VERSION ""

NS_ :

BS_:

BU_: ACM APIM APIM_CDC APIM_CIM APIM_CISM ARM DSP ESPM FCIMB GENERIC GWM HUD_ADV IPC MRCMB_RDAPM_HS3 RACM_RCIM TRM_ITRM TSTR WCM WCMB WCMC

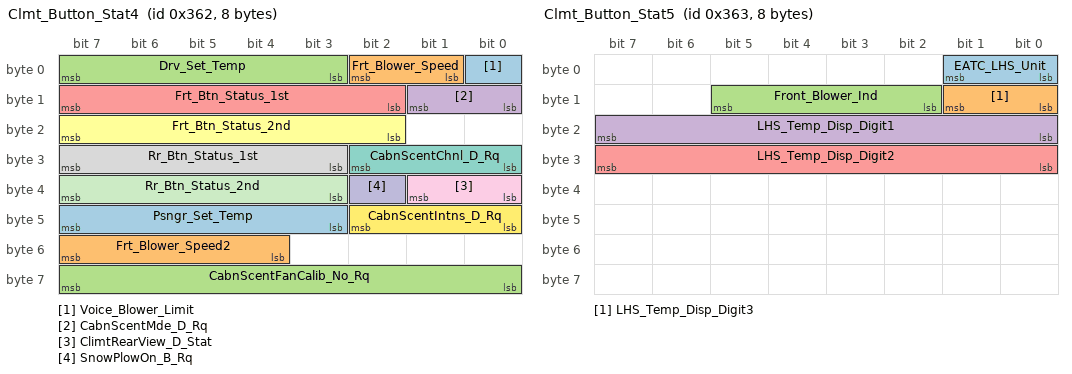
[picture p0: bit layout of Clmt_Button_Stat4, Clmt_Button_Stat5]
BO_ 866 Clmt_Button_Stat4: 8 APIM_CDC
 SG_ Voice_Blower_Limit : 0|1@0+ (1,0) [0|1] "SED"  GWM
 SG_ Frt_Blower_Speed : 2|2@0+ (1,0) [0|3] "SED"  GWM,RACM_RCIM
 SG_ Drv_Set_Temp : 7|5@0+ (1,0) [0|31] "SED"  GWM,RACM_RCIM
 SG_ CabnScentMde_D_Rq : 9|2@0+ (1,0) [0|3] "SED"  GWM
 SG_ Frt_Btn_Status_1st : 15|6@0+ (1,0) [0|63] "SED"  ACM,GWM,RACM_RCIM
 SG_ Frt_Btn_Status_2nd : 23|6@0+ (1,0) [0|63] "SED"  ACM,GWM,RACM_RCIM
 SG_ CabnScentChnl_D_Rq : 26|3@0+ (1,0) [0|7] "SED"  GWM
 SG_ Rr_Btn_Status_1st : 31|5@0+ (1,0) [0|31] "SED"  GWM,RACM_RCIM
 SG_ ClimtRearView_D_Stat : 33|2@0+ (1,0) [0|3] "SED"  GWM,RACM_RCIM
 SG_ SnowPlowOn_B_Rq : 34|1@0+ (1,0) [0|1] "SED"  GWM
 SG_ Rr_Btn_Status_2nd : 39|5@0+ (1,0) [0|31] "SED"  GWM,RACM_RCIM
 SG_ CabnScentIntns_D_Rq : 42|3@0+ (1,0) [0|7] "SED"  GWM
 SG_ Psngr_Set_Temp : 47|5@0+ (1,0) [0|31] "SED"  GWM,RACM_RCIM
 SG_ Frt_Blower_Speed2 : 55|4@0+ (1,0) [0|15] "SED"  GWM,RACM_RCIM
 SG_ CabnScentFanCalib_No_Rq : 63|8@0+ (1,0) [0|255] "SED"  GWM

BO_ 867 Clmt_Button_Stat5: 8 APIM_CDC
 SG_ EATC_LHS_Unit : 1|2@0+ (1,0) [0|3] "SED"  GWM,HUD_ADV
 SG_ LHS_Temp_Disp_Digit3 : 9|2@0+ (1,0) [0|3] "SED"  GWM,HUD_ADV
 SG_ Front_Blower_Ind : 13|4@0+ (1,0) [0|15] "SED"  GWM
 SG_ LHS_Temp_Disp_Digit1 : 23|8@0+ (1,0) [0|255] "ASCII"  GWM,HUD_ADV
 SG_ LHS_Temp_Disp_Digit2 : 31|8@0+ (1,0) [0|255] "ASCII"  GWM,HUD_ADV

BO_ 868 Clmt_Button_Stat6_HS3: 8 GWM
 SG_ Rr_Blower_Indicate_Stat : 7|4@0+ (1,0) [0|15] "SED"  GENERIC

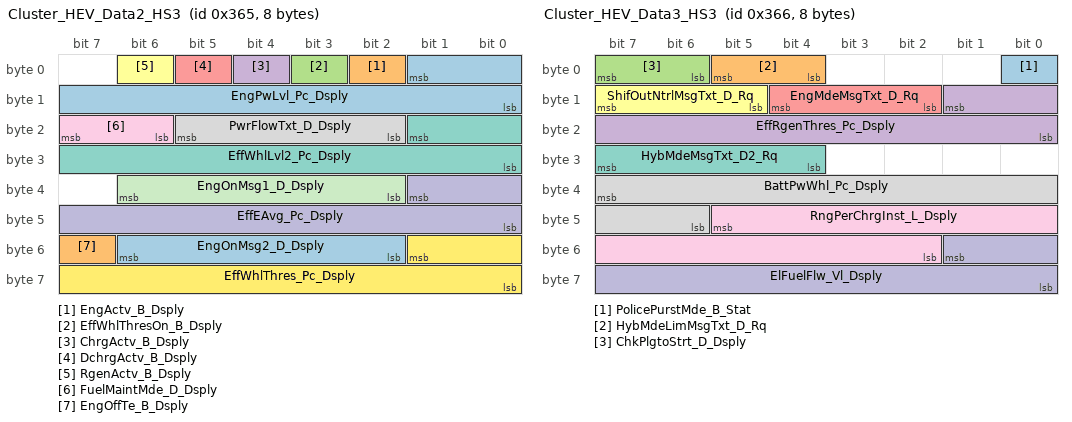
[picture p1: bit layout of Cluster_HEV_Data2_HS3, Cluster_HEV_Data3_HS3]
BO_ 869 Cluster_HEV_Data2_HS3: 8 GWM
 SG_ EngPwLvl_Pc_Dsply : 1|10@0+ (0.1,0) [0|102.3] "percent"  APIM,APIM_CDC,APIM_CIM,APIM_CISM,IPC
 SG_ EngActv_B_Dsply : 2|1@0+ (1,0) [0|1] "SED"  APIM,APIM_CDC,APIM_CIM,APIM_CISM,IPC
 SG_ EffWhlThresOn_B_Dsply : 3|1@0+ (1,0) [0|1] "SED"  APIM_CDC,APIM_CIM,APIM_CISM,IPC
 SG_ ChrgActv_B_Dsply : 4|1@0+ (1,0) [0|1] "SED"  APIM_CDC,APIM_CIM,APIM_CISM,IPC
 SG_ DchrgActv_B_Dsply : 5|1@0+ (1,0) [0|1] "SED"  APIM_CDC,APIM_CIM,APIM_CISM,IPC
 SG_ RgenActv_B_Dsply : 6|1@0+ (1,0) [0|1] "SED"  APIM_CDC,APIM_CIM,APIM_CISM,IPC
 SG_ EffWhlLvl2_Pc_Dsply : 17|10@0+ (0.2,-102.2) [-102.2|102.4] "percent"  ACM,APIM,APIM_CDC,APIM_CIM,APIM_CISM,IPC
 SG_ PwrFlowTxt_D_Dsply : 21|4@0+ (1,0) [0|15] "SED"  APIM,APIM_CDC,APIM_CIM,APIM_CISM,IPC
 SG_ FuelMaintMde_D_Dsply : 23|2@0+ (1,0) [0|3] "SED"  APIM_CDC,APIM_CIM,IPC
 SG_ EffEAvg_Pc_Dsply : 33|10@0+ (0.1,0) [0|102.3] "percent"  APIM,APIM_CDC,APIM_CIM,APIM_CISM,IPC
 SG_ EngOnMsg1_D_Dsply : 38|5@0+ (1,0) [0|31] "SED"  APIM,APIM_CDC,APIM_CIM,APIM_CISM,IPC
 SG_ EffWhlThres_Pc_Dsply : 49|10@0+ (0.1,0) [0|102.3] "percent"  APIM_CDC,APIM_CIM,IPC
 SG_ EngOnMsg2_D_Dsply : 54|5@0+ (1,0) [0|31] "SED"  APIM,APIM_CDC,APIM_CIM,APIM_CISM,IPC
 SG_ EngOffTe_B_Dsply : 55|1@0+ (1,0) [0|1] "SED"  APIM_CDC,APIM_CIM,APIM_CISM,IPC

BO_ 870 Cluster_HEV_Data3_HS3: 8 GWM
 SG_ PolicePurstMde_B_Stat : 0|1@0+ (1,0) [0|1] "SED"  APIM_CDC,APIM_CIM,IPC
 SG_ HybMdeLimMsgTxt_D_Rq : 5|2@0+ (1,0) [0|3] "SED"  APIM_CDC,APIM_CIM,APIM_CISM,IPC
 SG_ ChkPlgtoStrt_D_Dsply : 7|2@0+ (1,0) [0|3] "SED"  APIM_CDC,APIM_CIM,IPC
 SG_ EffRgenThres_Pc_Dsply : 9|10@0+ (0.1,-102.3) [-102.3|0] "percent"  APIM_CDC,APIM_CIM,IPC
 SG_ EngMdeMsgTxt_D_Rq : 12|3@0+ (1,0) [0|7] "SED"  APIM_CDC,APIM_CIM,IPC
 SG_ ShifOutNtrlMsgTxt_D_Rq : 15|3@0+ (1,0) [0|7] "SED"  APIM_CDC,APIM_CIM,APIM_CISM,IPC
 SG_ HybMdeMsgTxt_D2_Rq : 31|4@0+ (1,0) [0|15] "SED"  APIM_CDC,APIM_CIM,IPC
 SG_ BattPwWhl_Pc_Dsply : 39|10@0+ (0.1,0) [0|102.3] "percent"  APIM_CDC,APIM_CIM,APIM_CISM,IPC
 SG_ RngPerChrgInst_L_Dsply : 45|12@0+ (0.1,0) [0|409.5] "km"  APIM_CDC,APIM_CIM,IPC
 SG_ ElFuelFlw_Vl_Dsply : 49|10@0+ (25,0) [0|25575] "micro-litre"  APIM_CDC,APIM_CIM,APIM_CISM,IPC

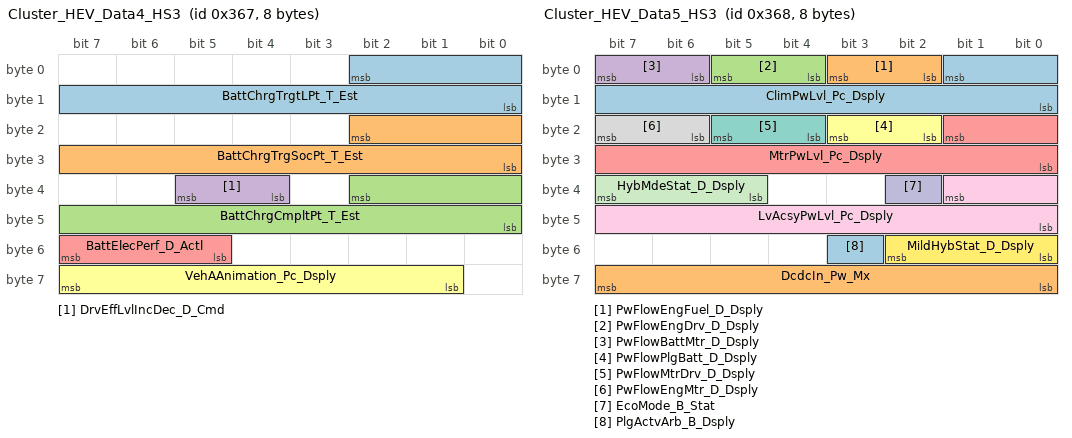
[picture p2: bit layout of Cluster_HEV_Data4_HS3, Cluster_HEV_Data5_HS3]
BO_ 871 Cluster_HEV_Data4_HS3: 8 GWM
 SG_ BattChrgTrgtLPt_T_Est : 2|11@0+ (1,0) [0|2047] "minute"  IPC
 SG_ BattChrgTrgSocPt_T_Est : 18|11@0+ (1,0) [0|2047] "minute"  IPC
 SG_ BattChrgCmpltPt_T_Est : 34|11@0+ (1,0) [0|2047] "minute"  IPC
 SG_ DrvEffLvlIncDec_D_Cmd : 37|2@0+ (1,0) [0|3] "SED"  APIM_CDC,APIM_CIM,APIM_CISM,IPC
 SG_ BattElecPerf_D_Actl : 55|3@0+ (1,0) [0|7] "SED"  APIM_CDC,APIM_CIM,APIM_CISM,IPC
 SG_ VehAAnimation_Pc_Dsply : 63|7@0+ (1,0) [0|127] "percent"  APIM_CDC,APIM_CIM,APIM_CISM,IPC

BO_ 872 Cluster_HEV_Data5_HS3: 8 GWM
 SG_ ClimPwLvl_Pc_Dsply : 1|10@0+ (0.1,0) [0|102.3] "percent"  APIM,APIM_CDC,APIM_CIM,APIM_CISM,IPC
 SG_ PwFlowEngFuel_D_Dsply : 3|2@0+ (1,0) [0|3] "SED"  APIM,APIM_CDC,APIM_CIM,APIM_CISM,IPC
 SG_ PwFlowEngDrv_D_Dsply : 5|2@0+ (1,0) [0|3] "SED"  APIM,APIM_CDC,APIM_CIM,APIM_CISM,IPC
 SG_ PwFlowBattMtr_D_Dsply : 7|2@0+ (1,0) [0|3] "SED"  APIM,APIM_CDC,APIM_CIM,APIM_CISM,IPC
 SG_ MtrPwLvl_Pc_Dsply : 17|10@0+ (0.2,-102.2) [-102.2|102.4] "percent"  APIM,APIM_CDC,APIM_CIM,APIM_CISM,IPC
 SG_ PwFlowPlgBatt_D_Dsply : 19|2@0+ (1,0) [0|3] "SED"  APIM,APIM_CDC,APIM_CIM,APIM_CISM,IPC
 SG_ PwFlowMtrDrv_D_Dsply : 21|2@0+ (1,0) [0|3] "SED"  APIM,APIM_CDC,APIM_CIM,APIM_CISM,IPC
 SG_ PwFlowEngMtr_D_Dsply : 23|2@0+ (1,0) [0|3] "SED"  APIM,APIM_CDC,APIM_CIM,APIM_CISM,IPC
 SG_ LvAcsyPwLvl_Pc_Dsply : 33|10@0+ (0.1,0) [0|102.3] "percent"  APIM,APIM_CDC,APIM_CIM,APIM_CISM,IPC
 SG_ EcoMode_B_Stat : 34|1@0+ (1,0) [0|1] "SED"  APIM_CDC,APIM_CIM,IPC
 SG_ HybMdeStat_D_Dsply : 39|3@0+ (1,0) [0|7] "SED"  APIM,APIM_CDC,APIM_CIM,APIM_CISM,HUD_ADV,IPC
 SG_ MildHybStat_D_Dsply : 50|3@0+ (1,0) [0|7] "SED"  APIM_CDC,APIM_CIM,IPC
 SG_ PlgActvArb_B_Dsply : 51|1@0+ (1,0) [0|1] "SED"  APIM,APIM_CDC,APIM_CIM,APIM_CISM,IPC
 SG_ DcdcIn_Pw_Mx : 63|8@0+ (20,1000) [1000|6100] "watts" Vector__XXX

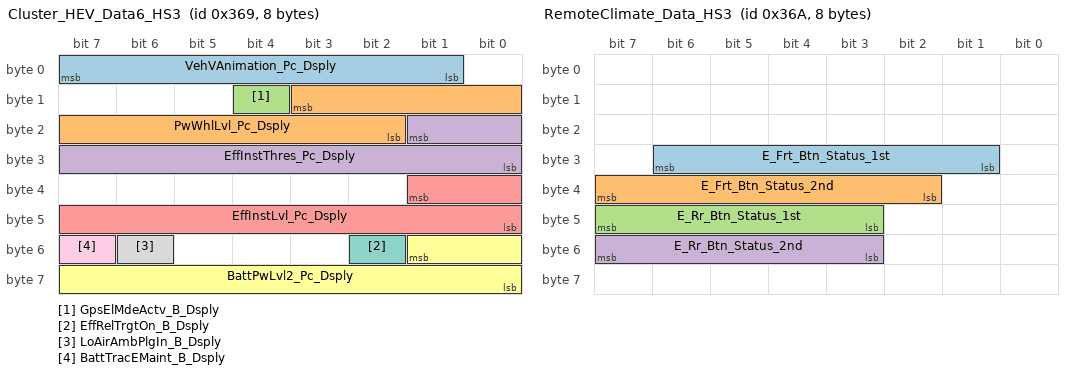
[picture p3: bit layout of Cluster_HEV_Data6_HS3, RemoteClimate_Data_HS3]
BO_ 873 Cluster_HEV_Data6_HS3: 8 GWM
 SG_ VehVAnimation_Pc_Dsply : 7|7@0+ (1,0) [0|127] "percent"  APIM_CDC,APIM_CIM,APIM_CISM,IPC
 SG_ PwWhlLvl_Pc_Dsply : 11|10@0+ (0.2,-102.2) [-102.2|102.4] "percent"  APIM_CDC,APIM_CIM,APIM_CISM,IPC
 SG_ GpsElMdeActv_B_Dsply : 12|1@0+ (1,0) [0|1] "SED"  APIM,APIM_CDC,APIM_CIM,APIM_CISM,IPC
 SG_ EffInstThres_Pc_Dsply : 17|10@0+ (0.1,0) [0|102.3] "percent"  APIM_CDC,APIM_CIM,APIM_CISM,IPC
 SG_ EffInstLvl_Pc_Dsply : 33|10@0+ (0.1,0) [0|102.3] "percent"  APIM_CDC,APIM_CIM,APIM_CISM,IPC
 SG_ BattPwLvl2_Pc_Dsply : 49|10@0+ (0.2,-102.2) [-102.2|102.4] "percent"  APIM,APIM_CDC,APIM_CIM,APIM_CISM,IPC
 SG_ EffRelTrgtOn_B_Dsply : 50|1@0+ (1,0) [0|1] "SED"  APIM_CDC,APIM_CIM,APIM_CISM,IPC
 SG_ LoAirAmbPlgIn_B_Dsply : 54|1@0+ (1,0) [0|1] "SED"  APIM_CDC,APIM_CIM,APIM_CISM,IPC
 SG_ BattTracEMaint_B_Dsply : 55|1@0+ (1,0) [0|1] "SED"  APIM_CDC,APIM_CIM,APIM_CISM,IPC

BO_ 874 RemoteClimate_Data_HS3: 8 FCIMB
 SG_ E_Frt_Btn_Status_1st : 30|6@0+ (1,0) [0|63] "SED"  APIM,APIM_CDC,APIM_CIM,APIM_CISM,GWM
 SG_ E_Frt_Btn_Status_2nd : 39|6@0+ (1,0) [0|63] "SED"  APIM,APIM_CDC,APIM_CIM,APIM_CISM,GWM
 SG_ E_Rr_Btn_Status_1st : 47|5@0+ (1,0) [0|31] "SED"  APIM,APIM_CDC,APIM_CIM,APIM_CISM,GWM
 SG_ E_Rr_Btn_Status_2nd : 55|5@0+ (1,0) [0|31] "SED"  APIM,APIM_CDC,APIM_CIM,APIM_CISM,GWM

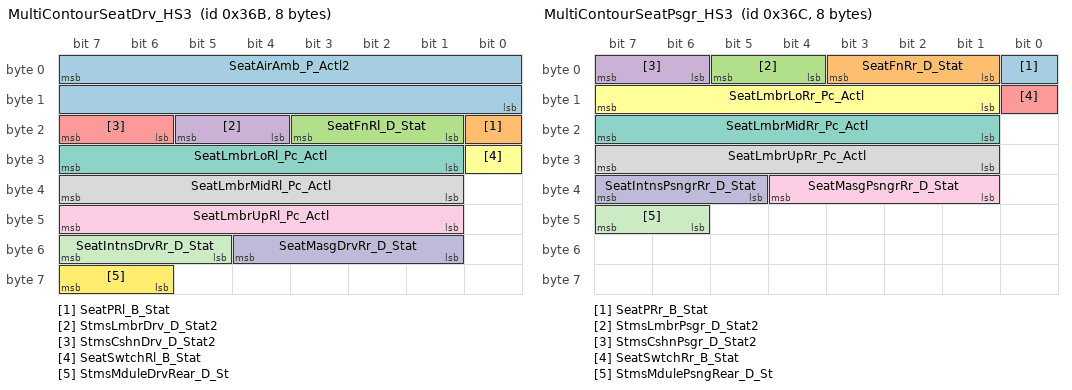
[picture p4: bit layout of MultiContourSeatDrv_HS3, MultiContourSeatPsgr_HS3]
BO_ 875 MultiContourSeatDrv_HS3: 8 GWM
 SG_ SeatAirAmb_P_Actl2 : 7|16@0+ (0.01,0) [0|655.35] "kilopascal"  RACM_RCIM
 SG_ SeatPRl_B_Stat : 16|1@0+ (1,0) [0|1] "SED"  RACM_RCIM
 SG_ SeatFnRl_D_Stat : 19|3@0+ (1,0) [0|7] "SED"  RACM_RCIM
 SG_ StmsLmbrDrv_D_Stat2 : 21|2@0+ (1,0) [0|3] "SED"  RACM_RCIM
 SG_ StmsCshnDrv_D_Stat2 : 23|2@0+ (1,0) [0|3] "SED"  RACM_RCIM
 SG_ SeatSwtchRl_B_Stat : 24|1@0+ (1,0) [0|1] "SED"  RACM_RCIM
 SG_ SeatLmbrLoRl_Pc_Actl : 31|7@0+ (1,0) [0|127] "Percent"  RACM_RCIM
 SG_ SeatLmbrMidRl_Pc_Actl : 39|7@0+ (1,0) [0|127] "Percent"  RACM_RCIM
 SG_ SeatLmbrUpRl_Pc_Actl : 47|7@0+ (1,0) [0|127] "Percent"  RACM_RCIM
 SG_ SeatMasgDrvRr_D_Stat : 52|4@0+ (1,0) [0|15] "SED"  RACM_RCIM
 SG_ SeatIntnsDrvRr_D_Stat : 55|3@0+ (1,0) [0|7] "SED"  RACM_RCIM
 SG_ StmsMduleDrvRear_D_St : 63|2@0+ (1,0) [0|3] "SED"  RACM_RCIM

BO_ 876 MultiContourSeatPsgr_HS3: 8 GWM
 SG_ SeatPRr_B_Stat : 0|1@0+ (1,0) [0|1] "SED"  RACM_RCIM
 SG_ SeatFnRr_D_Stat : 3|3@0+ (1,0) [0|7] "SED"  RACM_RCIM
 SG_ StmsLmbrPsgr_D_Stat2 : 5|2@0+ (1,0) [0|3] "SED"  RACM_RCIM
 SG_ StmsCshnPsgr_D_Stat2 : 7|2@0+ (1,0) [0|3] "SED"  RACM_RCIM
 SG_ SeatSwtchRr_B_Stat : 8|1@0+ (1,0) [0|1] "SED"  RACM_RCIM
 SG_ SeatLmbrLoRr_Pc_Actl : 15|7@0+ (1,0) [0|127] "Percent"  RACM_RCIM
 SG_ SeatLmbrMidRr_Pc_Actl : 23|7@0+ (1,0) [0|127] "Percent"  RACM_RCIM
 SG_ SeatLmbrUpRr_Pc_Actl : 31|7@0+ (1,0) [0|127] "Percent"  RACM_RCIM
 SG_ SeatMasgPsngrRr_D_Stat : 36|4@0+ (1,0) [0|15] "SED"  RACM_RCIM
 SG_ SeatIntnsPsngrRr_D_Stat : 39|3@0+ (1,0) [0|7] "SED"  RACM_RCIM
 SG_ StmsMdulePsngRear_D_St : 47|2@0+ (1,0) [0|3] "SED"  RACM_RCIM

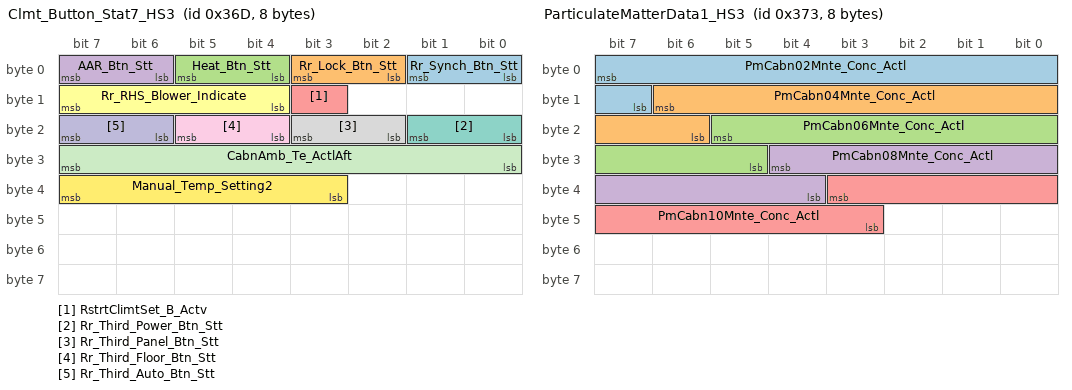
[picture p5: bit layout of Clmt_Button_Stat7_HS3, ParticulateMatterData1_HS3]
BO_ 877 Clmt_Button_Stat7_HS3: 8 GWM
 SG_ Rr_Synch_Btn_Stt : 1|2@0+ (1,0) [0|3] "SED"  APIM,APIM_CDC,APIM_CIM,APIM_CISM,RACM_RCIM
 SG_ Rr_Lock_Btn_Stt : 3|2@0+ (1,0) [0|3] "SED"  APIM,APIM_CDC,APIM_CIM,APIM_CISM,RACM_RCIM
 SG_ Heat_Btn_Stt : 5|2@0+ (1,0) [0|3] "SED"  APIM,APIM_CDC,APIM_CIM,APIM_CISM,FCIMB,RACM_RCIM
 SG_ AAR_Btn_Stt : 7|2@0+ (1,0) [0|3] "SED"  APIM,APIM_CDC,APIM_CIM,APIM_CISM,FCIMB,RACM_RCIM
 SG_ RstrtClimtSet_B_Actv : 11|1@0+ (1,0) [0|1] "SED" Vector__XXX
 SG_ Rr_RHS_Blower_Indicate : 15|4@0+ (1,0) [0|15] "SED"  APIM,APIM_CDC,APIM_CIM,APIM_CISM,RACM_RCIM
 SG_ Rr_Third_Power_Btn_Stt : 17|2@0+ (1,0) [0|3] "SED"  APIM,APIM_CDC,APIM_CIM,APIM_CISM,RACM_RCIM
 SG_ Rr_Third_Panel_Btn_Stt : 19|2@0+ (1,0) [0|3] "SED"  APIM,APIM_CDC,APIM_CIM,APIM_CISM,RACM_RCIM
 SG_ Rr_Third_Floor_Btn_Stt : 21|2@0+ (1,0) [0|3] "SED"  APIM,APIM_CDC,APIM_CIM,APIM_CISM,RACM_RCIM
 SG_ Rr_Third_Auto_Btn_Stt : 23|2@0+ (1,0) [0|3] "SED"  APIM,APIM_CDC,APIM_CIM,APIM_CISM,RACM_RCIM
 SG_ CabnAmb_Te_ActlAft : 31|8@0+ (0.5,-57) [-57|70.5] "degC" Vector__XXX
 SG_ Manual_Temp_Setting2 : 39|5@0+ (1,0) [0|31] "SED"  APIM,APIM_CDC,APIM_CIM,APIM_CISM

BO_ 878 Rear_Climate_Data2: 8 RACM_RCIM
 SG_ ClimtRearTe2_An_Actl : 7|9@0+ (1,0) [0|511] "degrees"  GWM
 SG_ ClimtRearBlwr2_D_Stat : 9|2@0+ (1,0) [0|3] "SED"  GWM
 SG_ ClimtRearTe2_D_Stat : 11|2@0+ (1,0) [0|3] "SED"  GWM
 SG_ ClimtRearFlr2_B_Stat : 12|1@0+ (1,0) [0|1] "SED"  GWM
 SG_ ClimtRearPnlFlr2_B_Stat : 13|1@0+ (1,0) [0|1] "SED"  GWM
 SG_ ClimtRearPnl2_B_Stat : 14|1@0+ (1,0) [0|1] "SED"  GWM
 SG_ ClimtRearBlwr2_An_Actl : 23|9@0+ (1,0) [0|511] "degrees"  GWM
 SG_ ClimtRearPw2_B_Stat : 29|1@0+ (1,0) [0|1] "SED"  GWM
 SG_ ClimtRearAuto2_B_Stat : 30|1@0+ (1,0) [0|1] "SED"  GWM
 SG_ ClimtSeatRr2_D_Rq : 39|8@0+ (1,0) [0|128] "SED"  GWM
 SG_ ClimtSeatRl2_D_Rq : 47|8@0+ (1,0) [0|128] "SED"  GWM
 SG_ ClimtRrBlwr3rd2_D_Stat : 49|2@0+ (1,0) [0|3] "SED"  GWM
 SG_ ClimtRrTe3rd2_D_Stat : 51|2@0+ (1,0) [0|3] "SED"  GWM
 SG_ ClimtStCoolRr2_B_Stat : 52|1@0+ (1,0) [0|1] "SED"  GWM
 SG_ ClimtStCoolRl2_B_Stat : 53|1@0+ (1,0) [0|1] "SED"  GWM
 SG_ ClimtStHeatRr2_B_Stat : 54|1@0+ (1,0) [0|1] "SED"  GWM
 SG_ ClimtStHeatRl2_B_Stat : 55|1@0+ (1,0) [0|1] "SED"  GWM
 SG_ ClimtRearView2_D_Stat : 57|2@0+ (1,0) [0|3] "SED"  GWM
 SG_ ClimtSyncRear2_B_Stat : 58|1@0+ (1,0) [0|1] "SED"  GWM
 SG_ ClimtRrPw3rd2_B_Stat : 59|1@0+ (1,0) [0|1] "SED"  GWM
 SG_ ClimtRrAuto3rd2_B_Stat : 60|1@0+ (1,0) [0|1] "SED"  GWM
 SG_ ClimtRrFlr3rd2_B_Stat : 61|1@0+ (1,0) [0|1] "SED"  GWM
 SG_ ClimtRrPnl3rd2_B_Stat : 62|1@0+ (1,0) [0|1] "SED"  GWM
 SG_ ClimtRrPf3rd2_B_Stat : 63|1@0+ (1,0) [0|1] "SED"  GWM

BO_ 883 ParticulateMatterData1_HS3: 8 GWM
 SG_ PmCabn02Mnte_Conc_Actl : 7|9@0+ (1,0) [0|511] "parts/million"  APIM,APIM_CDC,APIM_CIM,APIM_CISM,RACM_RCIM
 SG_ PmCabn04Mnte_Conc_Actl : 14|9@0+ (1,0) [0|511] "parts/million"  APIM,APIM_CDC,APIM_CIM,APIM_CISM,RACM_RCIM
 SG_ PmCabn06Mnte_Conc_Actl : 21|9@0+ (1,0) [0|511] "parts/million"  APIM,APIM_CDC,APIM_CIM,APIM_CISM,RACM_RCIM
 SG_ PmCabn08Mnte_Conc_Actl : 28|9@0+ (1,0) [0|511] "parts/million"  APIM,APIM_CDC,APIM_CIM,APIM_CISM,RACM_RCIM
 SG_ PmCabn10Mnte_Conc_Actl : 35|9@0+ (1,0) [0|511] "parts/million"  APIM,APIM_CDC,APIM_CIM,APIM_CISM,RACM_RCIM

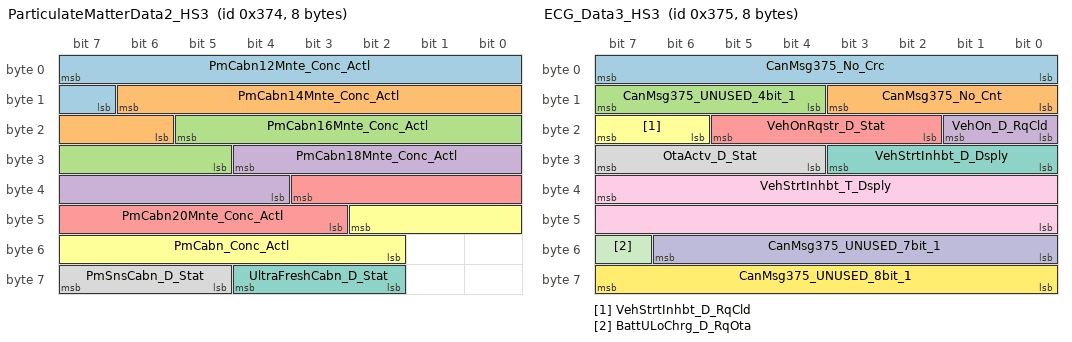
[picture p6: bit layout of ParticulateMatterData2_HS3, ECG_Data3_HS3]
BO_ 884 ParticulateMatterData2_HS3: 8 GWM
 SG_ PmCabn12Mnte_Conc_Actl : 7|9@0+ (1,0) [0|511] "parts/million"  APIM,APIM_CDC,APIM_CIM,APIM_CISM,RACM_RCIM
 SG_ PmCabn14Mnte_Conc_Actl : 14|9@0+ (1,0) [0|511] "parts/million"  APIM,APIM_CDC,APIM_CIM,APIM_CISM,RACM_RCIM
 SG_ PmCabn16Mnte_Conc_Actl : 21|9@0+ (1,0) [0|511] "parts/million"  APIM,APIM_CDC,APIM_CIM,APIM_CISM,RACM_RCIM
 SG_ PmCabn18Mnte_Conc_Actl : 28|9@0+ (1,0) [0|511] "parts/million"  APIM,APIM_CDC,APIM_CIM,APIM_CISM,RACM_RCIM
 SG_ PmCabn20Mnte_Conc_Actl : 35|9@0+ (1,0) [0|511] "parts/million"  APIM,APIM_CDC,APIM_CIM,APIM_CISM,RACM_RCIM
 SG_ PmCabn_Conc_Actl : 42|9@0+ (1,0) [0|511] "parts/million"  APIM,APIM_CDC,APIM_CIM,APIM_CISM,RACM_RCIM
 SG_ UltraFreshCabn_D_Stat : 60|3@0+ (1,0) [0|7] "SED"  APIM_CDC,APIM_CIM,APIM_CISM
 SG_ PmSnsCabn_D_Stat : 63|3@0+ (1,0) [0|7] "SED"  APIM,APIM_CDC,APIM_CIM,APIM_CISM,RACM_RCIM

BO_ 885 ECG_Data3_HS3: 8 GWM
 SG_ CanMsg375_No_Crc : 7|8@0+ (1,0) [0|255] "unitless"  APIM,GWM
 SG_ CanMsg375_No_Cnt : 11|4@0+ (1,0) [0|15] "unitless"  APIM,GWM
 SG_ CanMsg375_UNUSED_4bit_1 : 15|4@0+ (1,0) [15|15] "Unitless"  APIM,GWM
 SG_ VehOn_D_RqCld : 17|2@0+ (1,0) [0|3] "SED"  APIM,GWM
 SG_ VehOnRqstr_D_Stat : 21|4@0+ (1,0) [0|15] "SED"  APIM,GWM
 SG_ VehStrtInhbt_D_RqCld : 23|2@0+ (1,0) [0|3] "SED"  APIM,GWM
 SG_ VehStrtInhbt_D_Dsply : 27|4@0+ (1,0) [0|15] "SED"  APIM,APIM_CDC,APIM_CIM,GWM,IPC
 SG_ OtaActv_D_Stat : 31|4@0+ (1,0) [0|15] "SED"  APIM,APIM_CDC,APIM_CIM,GWM,HUD_ADV,IPC
 SG_ VehStrtInhbt_T_Dsply : 39|16@0+ (1,0) [0|65535] "second"  APIM,APIM_CDC,APIM_CIM,GWM,IPC
 SG_ CanMsg375_UNUSED_7bit_1 : 54|7@0+ (1,0) [127|127] "Unitless"  APIM,GWM
 SG_ BattULoChrg_D_RqOta : 55|1@0+ (1,0) [0|1] "SED"  APIM,GWM
 SG_ CanMsg375_UNUSED_8bit_1 : 63|8@0+ (1,0) [255|255] "Unitless"  APIM,GWM

BO_ 890 Active_Noise: 8 APIM_CDC
 SG_ ActvNseMute_D_Rq : 4|2@0+ (1,0) [0|3] "SED"  ACM,DSP
 SG_ ActvNse_B_Actv : 5|1@0+ (1,0) [0|1] "SED"  ACM,DSP
 SG_ ActvNseAudio_D_Stat : 7|2@0+ (1,0) [0|3] "SED"  DSP

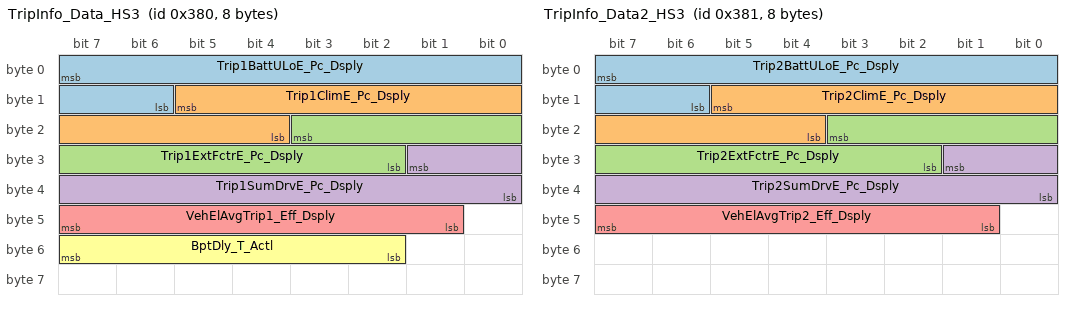
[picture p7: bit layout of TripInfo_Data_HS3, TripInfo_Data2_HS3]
BO_ 896 TripInfo_Data_HS3: 8 GWM
 SG_ Trip1BattULoE_Pc_Dsply : 7|10@0+ (0.1,0) [0|102.3] "percent"  APIM,APIM_CDC,APIM_CIM,APIM_CISM
 SG_ Trip1ClimE_Pc_Dsply : 13|10@0+ (0.1,0) [0|102.3] "percent"  APIM,APIM_CDC,APIM_CIM,APIM_CISM
 SG_ Trip1ExtFctrE_Pc_Dsply : 19|10@0+ (0.1,0) [0|102.3] "percent"  APIM,APIM_CDC,APIM_CIM,APIM_CISM
 SG_ Trip1SumDrvE_Pc_Dsply : 25|10@0+ (0.1,0) [0|102.3] "percent"  APIM,APIM_CDC,APIM_CIM,APIM_CISM
 SG_ VehElAvgTrip1_Eff_Dsply : 47|7@0+ (10,-100) [-100|1170] "wattHr/km"  APIM,APIM_CDC,APIM_CIM,APIM_CISM,IPC
 SG_ BptDly_T_Actl : 55|6@0+ (0.5,0) [0|31.5] "minute"  APIM,APIM_CDC,APIM_CIM,APIM_CISM

BO_ 897 TripInfo_Data2_HS3: 8 GWM
 SG_ Trip2BattULoE_Pc_Dsply : 7|10@0+ (0.1,0) [0|102.3] "percent"  APIM,APIM_CDC,APIM_CIM,APIM_CISM
 SG_ Trip2ClimE_Pc_Dsply : 13|10@0+ (0.1,0) [0|102.3] "percent"  APIM,APIM_CDC,APIM_CIM,APIM_CISM
 SG_ Trip2ExtFctrE_Pc_Dsply : 19|10@0+ (0.1,0) [0|102.3] "percent"  APIM,APIM_CDC,APIM_CIM,APIM_CISM
 SG_ Trip2SumDrvE_Pc_Dsply : 25|10@0+ (0.1,0) [0|102.3] "percent"  APIM,APIM_CDC,APIM_CIM,APIM_CISM
 SG_ VehElAvgTrip2_Eff_Dsply : 47|7@0+ (10,-100) [-100|1170] "wattHr/km"  APIM,APIM_CDC,APIM_CIM,APIM_CISM,IPC

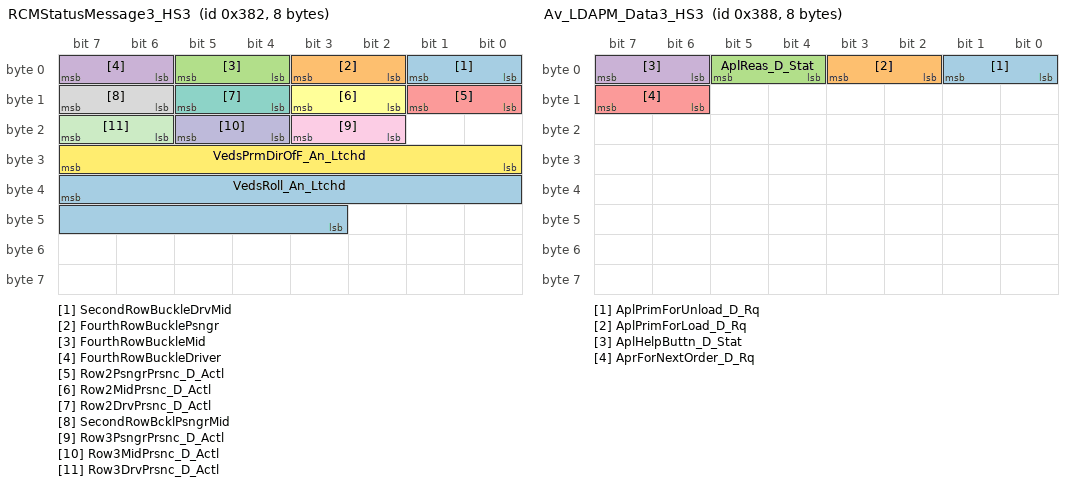
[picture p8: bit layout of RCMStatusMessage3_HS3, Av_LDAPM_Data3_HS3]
BO_ 898 RCMStatusMessage3_HS3: 8 GWM
 SG_ SecondRowBuckleDrvMid : 1|2@0+ (1,0) [0|3] "SED"  APIM_CDC,APIM_CIM,IPC
 SG_ FourthRowBucklePsngr : 3|2@0+ (1,0) [0|3] "SED"  APIM_CDC,APIM_CIM,IPC
 SG_ FourthRowBuckleMid : 5|2@0+ (1,0) [0|3] "SED"  APIM_CDC,APIM_CIM,IPC
 SG_ FourthRowBuckleDriver : 7|2@0+ (1,0) [0|3] "SED"  APIM_CDC,APIM_CIM,IPC
 SG_ Row2PsngrPrsnc_D_Actl : 9|2@0+ (1,0) [0|3] "SED"  APIM,APIM_CDC,APIM_CIM,APIM_CISM,IPC
 SG_ Row2MidPrsnc_D_Actl : 11|2@0+ (1,0) [0|3] "SED"  APIM,APIM_CDC,APIM_CIM,APIM_CISM,IPC
 SG_ Row2DrvPrsnc_D_Actl : 13|2@0+ (1,0) [0|3] "SED"  APIM,APIM_CDC,APIM_CIM,APIM_CISM,IPC
 SG_ SecondRowBcklPsngrMid : 15|2@0+ (1,0) [0|3] "SED"  APIM_CDC,APIM_CIM,IPC
 SG_ Row3PsngrPrsnc_D_Actl : 19|2@0+ (1,0) [0|3] "SED"  APIM,APIM_CDC,APIM_CIM,APIM_CISM,IPC
 SG_ Row3MidPrsnc_D_Actl : 21|2@0+ (1,0) [0|3] "SED"  APIM,APIM_CDC,APIM_CIM,APIM_CISM,IPC
 SG_ Row3DrvPrsnc_D_Actl : 23|2@0+ (1,0) [0|3] "SED"  APIM,APIM_CDC,APIM_CIM,APIM_CISM,IPC
 SG_ VedsPrmDirOfF_An_Ltchd : 31|8@0+ (2,-180) [-180|330] "degree"  APIM,APIM_CDC,APIM_CIM,APIM_CISM
 SG_ VedsRoll_An_Ltchd : 39|13@0+ (0.5,-2048) [-2048|2047.5] "degree"  APIM,APIM_CDC,APIM_CIM,APIM_CISM

BO_ 901 Av_LDAPM_Data2_HS3: 8 GWM
 SG_ AplSnd_D_Rq : 7|6@0+ (1,0) [0|63] "SED"  APIM,APIM_CDC,APIM_CIM,APIM_CISM

BO_ 903 Av_RDAPM_Data2_HS3: 8 GWM
 SG_ AprSnd_D_Rq : 7|6@0+ (1,0) [0|63] "SED"  APIM,APIM_CDC,APIM_CIM,APIM_CISM

BO_ 904 Av_LDAPM_Data3_HS3: 8 GWM
 SG_ AplPrimForUnload_D_Rq : 1|2@0+ (1,0) [0|3] "SED"  MRCMB_RDAPM_HS3
 SG_ AplPrimForLoad_D_Rq : 3|2@0+ (1,0) [0|3] "SED"  MRCMB_RDAPM_HS3
 SG_ AplReas_D_Stat : 5|2@0+ (1,0) [0|3] "SED" Vector__XXX
 SG_ AplHelpButtn_D_Stat : 7|2@0+ (1,0) [0|3] "SED" Vector__XXX
 SG_ AprForNextOrder_D_Rq : 15|2@0+ (1,0) [0|3] "SED"  MRCMB_RDAPM_HS3

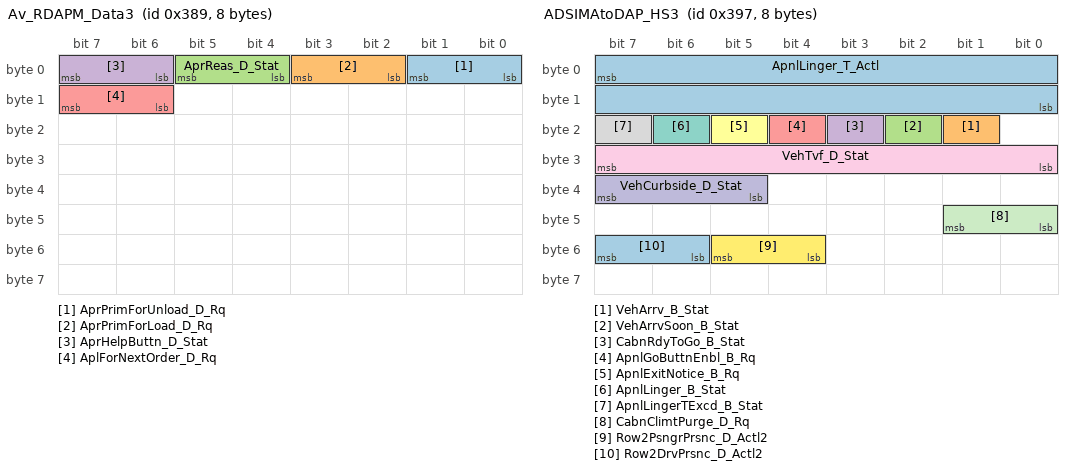
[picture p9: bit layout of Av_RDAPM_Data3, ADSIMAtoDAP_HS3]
BO_ 905 Av_RDAPM_Data3: 8 MRCMB_RDAPM_HS3
 SG_ AprPrimForUnload_D_Rq : 1|2@0+ (1,0) [0|3] "SED"  GWM
 SG_ AprPrimForLoad_D_Rq : 3|2@0+ (1,0) [0|3] "SED"  GWM
 SG_ AprReas_D_Stat : 5|2@0+ (1,0) [0|3] "SED"  GWM
 SG_ AprHelpButtn_D_Stat : 7|2@0+ (1,0) [0|3] "SED"  GWM
 SG_ AplForNextOrder_D_Rq : 15|2@0+ (1,0) [0|3] "SED"  GWM

BO_ 908 DisplayFileID: 8 GWM
 SG_ ApnlLogoId_No_Actl : 7|56@0+ (1,0) [0|7.20575940379279E+016] "unitless"  MRCMB_RDAPM_HS3

BO_ 909 Body_Info_6_HS3: 8 GWM
 SG_ KeyMykeyTot_No_Cnt : 3|4@0+ (1,0) [0|15] "Counts"  ACM,APIM_CDC,APIM_CIM,IPC
 SG_ KeyAdmnTot_No_Cnt : 7|4@0+ (1,0) [0|15] "Counts"  APIM_CDC,APIM_CIM,IPC
 SG_ Keycode_Status : 15|20@0+ (1,0) [0|1048575] "unitless"  APIM_CDC,APIM_CIM,IPC
 SG_ SteWhlLckMsgTxt_D_Rq : 25|2@0+ (1,0) [0|3] "SED"  APIM_CDC,APIM_CIM,IPC
 SG_ PEBackupSlot_Stats : 27|2@0+ (1,0) [0|3] "SED"  APIM_CDC,APIM_CIM,IPC
 SG_ PrmtrAlrmEvnt_D_Stat : 35|4@0+ (1,0) [0|15] "SED"  APIM_CIM
 SG_ immoMsgTxt_D_Rq : 39|4@0+ (1,0) [0|15] "SED"  APIM_CDC,APIM_CIM,IPC
 SG_ PrsnlDevcChrgEnbl_B_Rq : 40|1@0+ (1,0) [0|1] "SED"  APIM,APIM_CDC,APIM_CIM,APIM_CISM,WCM,WCMB,WCMC
 SG_ DrLatchMsgTxt_D_Rq : 43|3@0+ (1,0) [0|7] "SED"  APIM_CDC,APIM_CIM,IPC
 SG_ TracKeyMde_D_Stat : 45|2@0+ (1,0) [0|3] "SED"  APIM_CDC,APIM_CIM,IPC
 SG_ SecurityMsgTxt_D_Rq : 47|2@0+ (1,0) [0|3] "SED"  APIM_CDC,APIM_CIM
 SG_ TurnLghtSwtch_D_Stat2 : 49|2@0+ (1,0) [0|3] "SED"  APIM_CDC,APIM_CIM,IPC
 SG_ HeadLghtHiPrmsn_D_Stat : 51|2@0+ (1,0) [0|3] "SED"  GENERIC
 SG_ PoliceIdlMde_D_Stat : 55|4@0+ (1,0) [0|15] "SED"  APIM_CDC,APIM_CIM,IPC
 SG_ HazrdLght_B_Stat : 56|1@0+ (1,0) [0|1] "SED"  APIM,APIM_CDC,APIM_CIM,APIM_CISM
 SG_ IgnPsswrdDsply_B_Rq : 57|1@0+ (1,0) [0|1] "SED"  APIM,APIM_CDC,APIM_CIM,APIM_CISM,IPC
 SG_ ElPwPoint_D_Rq : 59|2@0+ (1,0) [0|3] "SED"  GENERIC
 SG_ WiprFront_D_Stat2 : 63|4@0+ (1,0) [0|15] "SED"  APIM,APIM_CDC,APIM_CIM,APIM_CISM

BO_ 912 PowerDist_Data1_HS3: 8 GWM
 SG_ AdasRelay_B_Stat : 1|1@0+ (1,0) [0|1] "SED" Vector__XXX
 SG_ BattTracSov_D_Stat : 4|3@0+ (1,0) [0|7] "SED" Vector__XXX
 SG_ BattChlrSov_D_Stat : 7|3@0+ (1,0) [0|7] "SED" Vector__XXX
 SG_ CabnEvapSovRear_D_Stat : 12|3@0+ (1,0) [0|7] "SED" Vector__XXX
 SG_ CabnEvapSovFront_D_Stat : 15|3@0+ (1,0) [0|7] "SED" Vector__XXX
 SG_ VehHorn_D_Stat : 17|2@0+ (1,0) [0|3] "SED" Vector__XXX
 SG_ GearPrkLck_D_Stat : 20|3@0+ (1,0) [0|7] "SED" Vector__XXX
 SG_ HeatCoreSovRear_D_Stat : 23|3@0+ (1,0) [0|7] "SED" Vector__XXX
 SG_ OraZone2_D_Stat : 25|2@0+ (1,0) [0|3] "SED"  APIM_CDC,GWM
 SG_ BattTracClntVlv_D_Stat : 28|3@0+ (1,0) [0|7] "SED" Vector__XXX
 SG_ GearPrkMtr_D_Stat : 31|3@0+ (1,0) [0|7] "SED" Vector__XXX
 SG_ OraZone4_D_Stat : 33|2@0+ (1,0) [0|3] "SED"  APIM_CDC,GWM
 SG_ PwBus07_D_Res : 36|3@0+ (1,0) [0|7] "SED" Vector__XXX
 SG_ PwBus06_D_Res : 39|3@0+ (1,0) [0|7] "SED" Vector__XXX
 SG_ OraZone5_D_Stat : 41|2@0+ (1,0) [0|3] "SED"  APIM_CDC,GWM
 SG_ PwBus09_D_Res : 44|3@0+ (1,0) [0|7] "SED" Vector__XXX
 SG_ PwBus08_D_Res : 47|3@0+ (1,0) [0|7] "SED" Vector__XXX
 SG_ OraZone6_D_Stat : 63|2@0+ (1,0) [0|3] "SED"  APIM_CDC,GWM

BO_ 919 ADSIMAtoDAP_HS3: 8 GWM
 SG_ ApnlLinger_T_Actl : 7|16@0+ (1,0) [0|65535] "second"  MRCMB_RDAPM_HS3
 SG_ VehArrv_B_Stat : 17|1@0+ (1,0) [0|1] "SED"  MRCMB_RDAPM_HS3
 SG_ VehArrvSoon_B_Stat : 18|1@0+ (1,0) [0|1] "SED"  MRCMB_RDAPM_HS3
 SG_ CabnRdyToGo_B_Stat : 19|1@0+ (1,0) [0|1] "SED"  MRCMB_RDAPM_HS3
 SG_ ApnlGoButtnEnbl_B_Rq : 20|1@0+ (1,0) [0|1] "SED"  MRCMB_RDAPM_HS3
 SG_ ApnlExitNotice_B_Rq : 21|1@0+ (1,0) [0|1] "SED"  MRCMB_RDAPM_HS3
 SG_ ApnlLinger_B_Stat : 22|1@0+ (1,0) [0|1] "SED"  MRCMB_RDAPM_HS3
 SG_ ApnlLingerTExcd_B_Stat : 23|1@0+ (1,0) [0|1] "SED"  MRCMB_RDAPM_HS3
 SG_ VehTvf_D_Stat : 31|8@0+ (1,0) [0|255] "SED"  MRCMB_RDAPM_HS3
 SG_ VehCurbside_D_Stat : 39|3@0+ (1,0) [0|7] "SED"  MRCMB_RDAPM_HS3
 SG_ CabnClimtPurge_D_Rq : 41|2@0+ (1,0) [0|3] "SED" Vector__XXX
 SG_ Row2PsngrPrsnc_D_Actl2 : 53|2@0+ (1,0) [0|3] "SED"  APIM_CDC
 SG_ Row2DrvPrsnc_D_Actl2 : 55|2@0+ (1,0) [0|3] "SED"  APIM_CDC

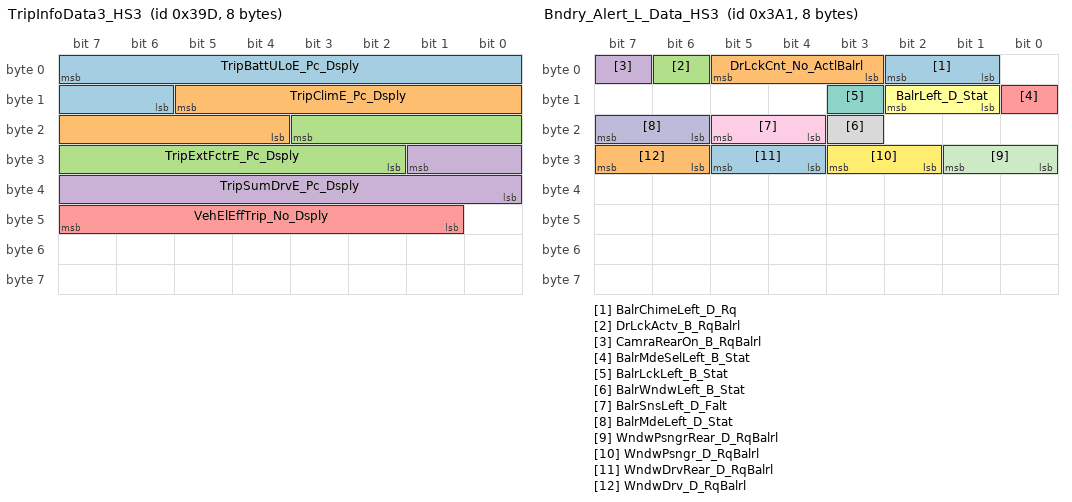
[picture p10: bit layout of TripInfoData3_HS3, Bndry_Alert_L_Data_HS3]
BO_ 925 TripInfoData3_HS3: 8 GWM
 SG_ TripBattULoE_Pc_Dsply : 7|10@0+ (0.1,0) [0|102.3] "percent"  APIM,APIM_CDC,APIM_CIM,APIM_CISM,IPC
 SG_ TripClimE_Pc_Dsply : 13|10@0+ (0.1,0) [0|102.3] "percent"  APIM,APIM_CDC,APIM_CIM,APIM_CISM,IPC
 SG_ TripExtFctrE_Pc_Dsply : 19|10@0+ (0.1,0) [0|102.3] "percent"  APIM,APIM_CDC,APIM_CIM,APIM_CISM,IPC
 SG_ TripSumDrvE_Pc_Dsply : 25|10@0+ (0.1,0) [0|102.3] "percent"  APIM,APIM_CDC,APIM_CIM,APIM_CISM,IPC
 SG_ VehElEffTrip_No_Dsply : 47|7@0+ (10,-100) [-100|1170] "wattHr/km"  APIM,APIM_CDC,APIM_CIM,APIM_CISM,IPC

BO_ 929 Bndry_Alert_L_Data_HS3: 8 GWM
 SG_ BalrChimeLeft_D_Rq : 2|2@0+ (1,0) [0|3] "SED"  APIM_CDC,APIM_CIM,IPC
 SG_ DrLckCnt_No_ActlBalrl : 5|3@0+ (1,0) [0|7] "unitless" Vector__XXX
 SG_ DrLckActv_B_RqBalrl : 6|1@0+ (1,0) [0|1] "SED" Vector__XXX
 SG_ CamraRearOn_B_RqBalrl : 7|1@0+ (1,0) [0|1] "SED"  ACM,APIM,APIM_CDC,APIM_CIM,APIM_CISM,TRM_ITRM
 SG_ BalrMdeSelLeft_B_Stat : 8|1@0+ (1,0) [0|1] "SED"  APIM_CDC,APIM_CIM,IPC
 SG_ BalrLeft_D_Stat : 10|2@0+ (1,0) [0|3] "SED"  APIM_CDC,APIM_CIM,IPC
 SG_ BalrLckLeft_B_Stat : 11|1@0+ (1,0) [0|1] "SED"  APIM_CDC,APIM_CIM,IPC
 SG_ BalrWndwLeft_B_Stat : 19|1@0+ (1,0) [0|1] "SED"  APIM_CDC,APIM_CIM,IPC
 SG_ BalrSnsLeft_D_Falt : 21|2@0+ (1,0) [0|3] "SED"  APIM_CDC,APIM_CIM,IPC
 SG_ BalrMdeLeft_D_Stat : 23|2@0+ (1,0) [0|3] "SED"  APIM_CDC,APIM_CIM,IPC
 SG_ WndwPsngrRear_D_RqBalrl : 25|2@0+ (1,0) [0|3] "SED" Vector__XXX
 SG_ WndwPsngr_D_RqBalrl : 27|2@0+ (1,0) [0|3] "SED" Vector__XXX
 SG_ WndwDrvRear_D_RqBalrl : 29|2@0+ (1,0) [0|3] "SED" Vector__XXX
 SG_ WndwDrv_D_RqBalrl : 31|2@0+ (1,0) [0|3] "SED" Vector__XXX

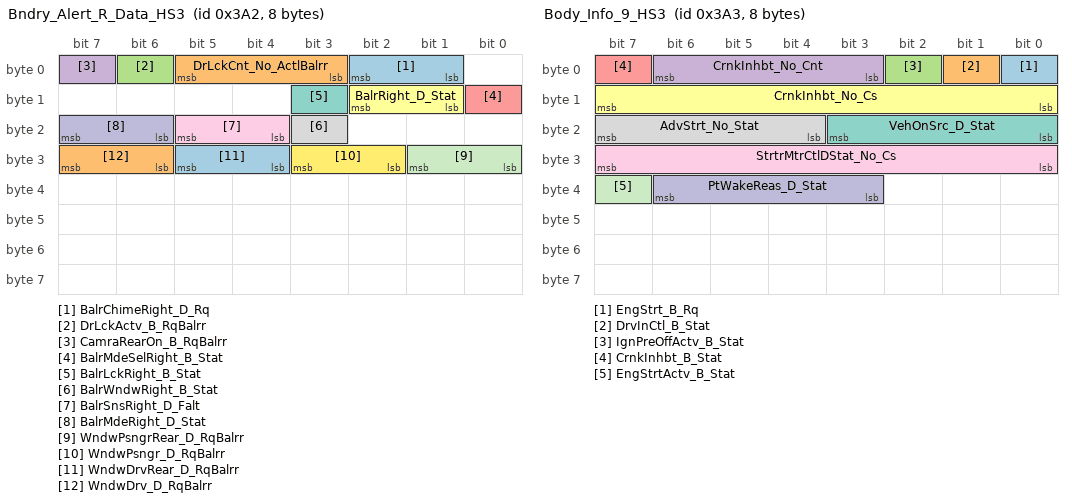
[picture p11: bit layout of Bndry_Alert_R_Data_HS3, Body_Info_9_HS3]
BO_ 930 Bndry_Alert_R_Data_HS3: 8 GWM
 SG_ BalrChimeRight_D_Rq : 2|2@0+ (1,0) [0|3] "SED"  APIM_CDC,APIM_CIM,IPC
 SG_ DrLckCnt_No_ActlBalrr : 5|3@0+ (1,0) [0|7] "unitless" Vector__XXX
 SG_ DrLckActv_B_RqBalrr : 6|1@0+ (1,0) [0|1] "SED" Vector__XXX
 SG_ CamraRearOn_B_RqBalrr : 7|1@0+ (1,0) [0|1] "SED"  ACM,APIM,APIM_CDC,APIM_CIM,APIM_CISM,TRM_ITRM
 SG_ BalrMdeSelRight_B_Stat : 8|1@0+ (1,0) [0|1] "SED"  APIM_CDC,APIM_CIM,IPC
 SG_ BalrRight_D_Stat : 10|2@0+ (1,0) [0|3] "SED"  APIM_CDC,APIM_CIM,IPC
 SG_ BalrLckRight_B_Stat : 11|1@0+ (1,0) [0|1] "SED"  APIM_CDC,APIM_CIM,IPC
 SG_ BalrWndwRight_B_Stat : 19|1@0+ (1,0) [0|1] "SED"  APIM_CDC,APIM_CIM,IPC
 SG_ BalrSnsRight_D_Falt : 21|2@0+ (1,0) [0|3] "SED"  APIM_CDC,APIM_CIM,IPC
 SG_ BalrMdeRight_D_Stat : 23|2@0+ (1,0) [0|3] "SED"  APIM_CDC,APIM_CIM,IPC
 SG_ WndwPsngrRear_D_RqBalrr : 25|2@0+ (1,0) [0|3] "SED" Vector__XXX
 SG_ WndwPsngr_D_RqBalrr : 27|2@0+ (1,0) [0|3] "SED" Vector__XXX
 SG_ WndwDrvRear_D_RqBalrr : 29|2@0+ (1,0) [0|3] "SED" Vector__XXX
 SG_ WndwDrv_D_RqBalrr : 31|2@0+ (1,0) [0|3] "SED" Vector__XXX

BO_ 931 Body_Info_9_HS3: 8 GWM
 SG_ EngStrt_B_Rq : 0|1@0+ (1,0) [0|1] "SED"  TRM_ITRM
 SG_ DrvInCtl_B_Stat : 1|1@0+ (1,0) [0|1] "SED"  TRM_ITRM
 SG_ IgnPreOffActv_B_Stat : 2|1@0+ (1,0) [0|1] "SED"  TRM_ITRM
 SG_ CrnkInhbt_No_Cnt : 6|4@0+ (1,0) [0|15] "unitless"  TRM_ITRM
 SG_ CrnkInhbt_B_Stat : 7|1@0+ (1,0) [0|1] "SED"  TRM_ITRM
 SG_ CrnkInhbt_No_Cs : 15|8@0+ (1,0) [0|255] "unitless"  TRM_ITRM
 SG_ VehOnSrc_D_Stat : 19|4@0+ (1,0) [0|15] "SED"  APIM,APIM_CDC,APIM_CIM,APIM_CISM,IPC,MRCMB_RDAPM_HS3,TRM_ITRM
 SG_ AdvStrt_No_Stat : 23|4@0+ (1,0) [0|15] "unitless"  TRM_ITRM
 SG_ StrtrMtrCtlDStat_No_Cs : 31|8@0+ (1,0) [0|255] "unitless"  TRM_ITRM
 SG_ PtWakeReas_D_Stat : 38|4@0+ (1,0) [0|15] "SED"  TRM_ITRM
 SG_ EngStrtActv_B_Stat : 39|1@0+ (1,0) [0|1] "SED"  TRM_ITRM

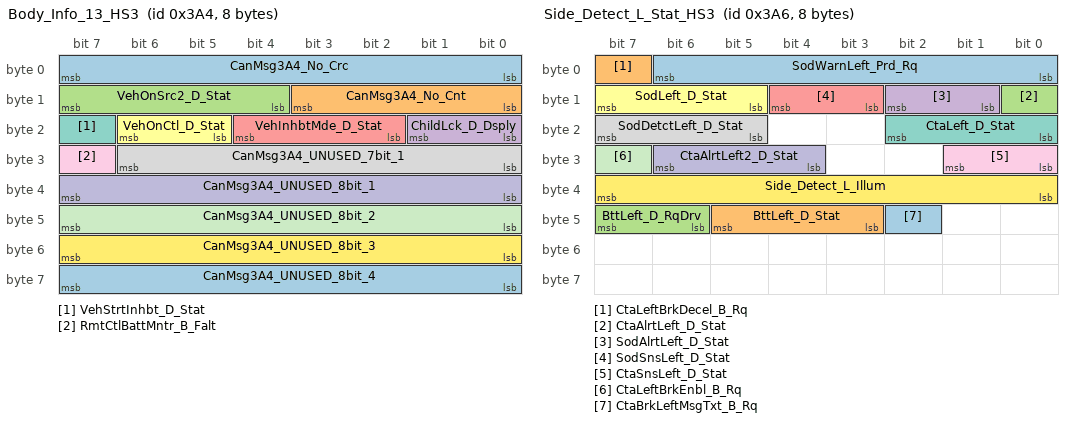
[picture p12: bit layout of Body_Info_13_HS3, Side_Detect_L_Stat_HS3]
BO_ 932 Body_Info_13_HS3: 8 GWM
 SG_ CanMsg3A4_No_Crc : 7|8@0+ (1,0) [0|255] "unitless"  APIM_CDC,APIM_CIM,ESPM,RACM_RCIM
 SG_ CanMsg3A4_No_Cnt : 11|4@0+ (1,0) [0|15] "unitless"  APIM_CDC,APIM_CIM,ESPM,RACM_RCIM
 SG_ VehOnSrc2_D_Stat : 15|4@0+ (1,0) [0|15] "SED"  APIM_CDC,APIM_CIM,ESPM,RACM_RCIM
 SG_ ChildLck_D_Dsply : 17|2@0+ (1,0) [0|3] "SED"  APIM_CDC,APIM_CIM,ESPM,RACM_RCIM
 SG_ VehInhbtMde_D_Stat : 20|3@0+ (1,0) [0|7] "SED"  APIM_CDC,APIM_CIM,ESPM,RACM_RCIM
 SG_ VehOnCtl_D_Stat : 22|2@0+ (1,0) [0|3] "SED"  APIM_CDC,APIM_CIM,ESPM,RACM_RCIM
 SG_ VehStrtInhbt_D_Stat : 23|1@0+ (1,0) [0|1] "SED"  APIM_CDC,APIM_CIM,ESPM,RACM_RCIM
 SG_ CanMsg3A4_UNUSED_7bit_1 : 30|7@0+ (1,0) [127|127] "unitless"  APIM_CDC,APIM_CIM,ESPM,RACM_RCIM
 SG_ RmtCtlBattMntr_B_Falt : 31|1@0+ (1,0) [0|1] "SED"  APIM_CDC,APIM_CIM,ESPM,RACM_RCIM
 SG_ CanMsg3A4_UNUSED_8bit_1 : 39|8@0+ (1,0) [255|255] "unitless"  APIM_CDC,APIM_CIM,ESPM,RACM_RCIM
 SG_ CanMsg3A4_UNUSED_8bit_2 : 47|8@0+ (1,0) [255|255] "unitless"  APIM_CDC,APIM_CIM,ESPM,RACM_RCIM
 SG_ CanMsg3A4_UNUSED_8bit_3 : 55|8@0+ (1,0) [255|255] "unitless"  APIM_CDC,APIM_CIM,ESPM,RACM_RCIM
 SG_ CanMsg3A4_UNUSED_8bit_4 : 63|8@0+ (1,0) [255|255] "unitless"  APIM_CDC,APIM_CIM,ESPM,RACM_RCIM

BO_ 934 Side_Detect_L_Stat_HS3: 8 GWM
 SG_ SodWarnLeft_Prd_Rq : 6|7@0+ (1,0) [0|127] "millisecond" Vector__XXX
 SG_ CtaLeftBrkDecel_B_Rq : 7|1@0+ (1,0) [0|1] "SED"  GENERIC
 SG_ CtaAlrtLeft_D_Stat : 8|1@0+ (1,0) [0|1] "SED"  APIM,APIM_CDC,APIM_CIM,APIM_CISM,IPC
 SG_ SodAlrtLeft_D_Stat : 10|2@0+ (1,0) [0|3] "SED"  APIM,APIM_CDC,APIM_CIM,APIM_CISM,ARM,HUD_ADV,IPC
 SG_ SodSnsLeft_D_Stat : 12|2@0+ (1,0) [0|3] "SED"  APIM_CDC,APIM_CIM,IPC
 SG_ SodLeft_D_Stat : 15|3@0+ (1,0) [0|7] "SED"  APIM_CDC,APIM_CIM,IPC
 SG_ CtaLeft_D_Stat : 18|3@0+ (1,0) [0|7] "SED"  APIM_CDC,APIM_CIM,IPC
 SG_ SodDetctLeft_D_Stat : 23|3@0+ (1,0) [0|7] "SED"  APIM_CDC,APIM_CIM,IPC
 SG_ CtaSnsLeft_D_Stat : 25|2@0+ (1,0) [0|3] "SED"  APIM_CDC,APIM_CIM,IPC
 SG_ CtaAlrtLeft2_D_Stat : 30|3@0+ (1,0) [0|7] "SED"  APIM_CDC,APIM_CIM,IPC
 SG_ CtaLeftBrkEnbl_B_Rq : 31|1@0+ (1,0) [0|1] "SED"  GENERIC
 SG_ Side_Detect_L_Illum : 39|8@0+ (1,0) [0|255] "Percent"  APIM_CDC,APIM_CIM,IPC
 SG_ CtaBrkLeftMsgTxt_B_Rq : 42|1@0+ (1,0) [0|1] "SED"  APIM,APIM_CDC,APIM_CIM,APIM_CISM,IPC
 SG_ BttLeft_D_Stat : 45|3@0+ (1,0) [0|7] "SED"  APIM,APIM_CDC,APIM_CIM,APIM_CISM,IPC
 SG_ BttLeft_D_RqDrv : 47|2@0+ (1,0) [0|3] "SED"  APIM,APIM_CDC,APIM_CIM,APIM_CISM,IPC

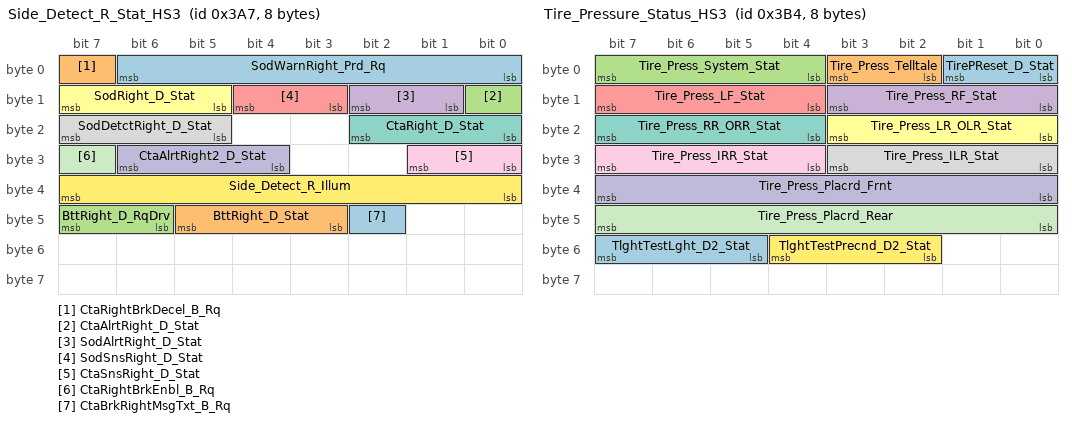
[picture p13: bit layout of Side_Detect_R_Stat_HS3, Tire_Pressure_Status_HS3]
BO_ 935 Side_Detect_R_Stat_HS3: 8 GWM
 SG_ SodWarnRight_Prd_Rq : 6|7@0+ (1,0) [0|127] "millisecond" Vector__XXX
 SG_ CtaRightBrkDecel_B_Rq : 7|1@0+ (1,0) [0|1] "SED"  GENERIC
 SG_ CtaAlrtRight_D_Stat : 8|1@0+ (1,0) [0|1] "SED"  APIM,APIM_CDC,APIM_CIM,APIM_CISM,IPC
 SG_ SodAlrtRight_D_Stat : 10|2@0+ (1,0) [0|3] "SED"  APIM,APIM_CDC,APIM_CIM,APIM_CISM,ARM,HUD_ADV,IPC
 SG_ SodSnsRight_D_Stat : 12|2@0+ (1,0) [0|3] "SED"  APIM_CDC,APIM_CIM,IPC
 SG_ SodRight_D_Stat : 15|3@0+ (1,0) [0|7] "SED"  APIM_CDC,APIM_CIM,IPC
 SG_ CtaRight_D_Stat : 18|3@0+ (1,0) [0|7] "SED"  APIM_CDC,APIM_CIM,IPC
 SG_ SodDetctRight_D_Stat : 23|3@0+ (1,0) [0|7] "SED"  APIM_CDC,APIM_CIM,IPC
 SG_ CtaSnsRight_D_Stat : 25|2@0+ (1,0) [0|3] "SED"  APIM_CDC,APIM_CIM,IPC
 SG_ CtaAlrtRight2_D_Stat : 30|3@0+ (1,0) [0|7] "SED"  APIM_CDC,APIM_CIM,IPC
 SG_ CtaRightBrkEnbl_B_Rq : 31|1@0+ (1,0) [0|1] "SED"  GENERIC
 SG_ Side_Detect_R_Illum : 39|8@0+ (1,0) [0|255] "Percent"  APIM_CDC,APIM_CIM,IPC
 SG_ CtaBrkRightMsgTxt_B_Rq : 42|1@0+ (1,0) [0|1] "SED"  APIM,APIM_CDC,APIM_CIM,APIM_CISM,IPC
 SG_ BttRight_D_Stat : 45|3@0+ (1,0) [0|7] "SED"  APIM,APIM_CDC,APIM_CIM,APIM_CISM,IPC
 SG_ BttRight_D_RqDrv : 47|2@0+ (1,0) [0|3] "SED"  APIM,APIM_CDC,APIM_CIM,APIM_CISM,IPC

BO_ 936 ParkAid_Data_HS3: 8 GWM
 SG_ SAPPStatusCoding : 7|8@0+ (1,0) [0|255] "unitless"  APIM,APIM_CDC,APIM_CIM,APIM_CISM
 SG_ ApaTrgtDist_D_Stat : 11|4@0+ (1,0) [0|15] "SED"  ACM,APIM,APIM_CDC,APIM_CIM,APIM_CISM
 SG_ ApaMsgTxt_D_Rq : 15|4@0+ (1,0) [0|15] "SED"  ACM,APIM,APIM_CDC,APIM_CIM,APIM_CISM
 SG_ ExtSteeringAngleReq2 : 22|15@0+ (0.1,-1000) [-1000|2276.7] "degrees" Vector__XXX
 SG_ EPASExtAngleStatReq : 23|1@0+ (1,0) [0|1] "SED" Vector__XXX
 SG_ ApaActvSide2_D_Stat : 33|2@0+ (1,0) [0|3] "SED"  ACM,APIM,APIM_CDC,APIM_CIM,APIM_CISM
 SG_ ApaAcsy_D_RqDrv : 36|3@0+ (1,0) [0|7] "SED"  ACM,APIM,APIM_CDC,APIM_CIM,APIM_CISM
 SG_ ApaChime_D_Rq : 39|3@0+ (1,0) [0|7] "SED"  APIM_CDC,APIM_CIM,IPC
 SG_ ApaScan_D_Stat : 41|2@0+ (1,0) [0|3] "SED"  ACM,APIM,APIM_CDC,APIM_CIM,APIM_CISM
 SG_ ApaLongCtl_D_RqDrv : 44|3@0+ (1,0) [0|7] "SED"  ACM,APIM,APIM_CDC,APIM_CIM,APIM_CISM
 SG_ ApaGearShif_D_RqDrv : 47|3@0+ (1,0) [0|7] "SED"  ACM,APIM,APIM_CDC,APIM_CIM,APIM_CISM
 SG_ ApaSteScanMde_D_Stat : 49|2@0+ (1,0) [0|3] "SED"  ACM,APIM,APIM_CDC,APIM_CIM,APIM_CISM
 SG_ ApaSelSapp_D_Stat : 51|2@0+ (1,0) [0|3] "SED"  ACM,APIM,APIM_CDC,APIM_CIM,APIM_CISM
 SG_ ApaSelPpa_D_Stat : 53|2@0+ (1,0) [0|3] "SED"  ACM,APIM,APIM_CDC,APIM_CIM,APIM_CISM
 SG_ ApaSelPoa_D_Stat : 55|2@0+ (1,0) [0|3] "SED"  ACM,APIM,APIM_CDC,APIM_CIM,APIM_CISM
 SG_ ApaButtnPrssd_B_Stat : 58|1@0+ (1,0) [0|1] "SED"  GENERIC
 SG_ ApaSys_D_Stat : 61|3@0+ (1,0) [0|7] "SED"  ACM,APIM,APIM_CDC,APIM_CIM,APIM_CISM,IPC
 SG_ ApaSteWhl_D_RqDrv : 63|2@0+ (1,0) [0|3] "SED"  ACM,APIM,APIM_CDC,APIM_CIM,APIM_CISM

BO_ 938 ParkAid_Aud_Warn_Stat_HS3: 8 GWM
 SG_ FpaChime_D_Rq : 3|4@0+ (1,0) [0|15] "SED"  APIM,APIM_CDC,APIM_CIM,APIM_CISM,IPC
 SG_ RpaChime_D_Rq : 7|4@0+ (1,0) [0|15] "SED"  APIM,APIM_CDC,APIM_CIM,APIM_CISM,IPC
 SG_ PrkAidSwtch_B_Stat : 8|1@0+ (1,0) [0|1] "SED"  APIM,APIM_CDC,APIM_CIM,APIM_CISM,IPC
 SG_ ApaMde_D_Avail : 12|4@0+ (1,0) [0|15] "SED"  APIM,APIM_CDC,APIM_CIM,APIM_CISM
 SG_ ApaActvSd_D_Actl : 14|2@0+ (1,0) [0|3] "SED"  APIM,APIM_CDC,APIM_CIM,APIM_CISM,IPC
 SG_ PrkAidAudioMute_B_Rq : 15|1@0+ (1,0) [0|1] "SED"  APIM_CDC,APIM_CIM,IPC
 SG_ PrkAidMsgTxt_D_Rq : 19|4@0+ (1,0) [0|15] "SED"  APIM,APIM_CDC,APIM_CIM,APIM_CISM,IPC
 SG_ PrkBrkEl_B_RqFap : 20|1@0+ (1,0) [0|1] "SED"  APIM_CIM,GENERIC
 SG_ ApaMde_D_Stat : 23|3@0+ (1,0) [0|7] "SED"  APIM,APIM_CDC,APIM_CIM,APIM_CISM,IPC
 SG_ PrkAidSnsFlCrnr_D_Stat : 27|4@0+ (1,0) [0|15] "SED"  APIM,APIM_CDC,APIM_CIM,APIM_CISM,IPC
 SG_ PrkAidSnsFlCntr_D_Stat : 31|4@0+ (1,0) [0|15] "SED"  APIM,APIM_CDC,APIM_CIM,APIM_CISM,IPC
 SG_ PrkAidSnsFrCntr_D_Stat : 35|4@0+ (1,0) [0|15] "SED"  APIM,APIM_CDC,APIM_CIM,APIM_CISM,IPC
 SG_ PrkAidSnsFrCrnr_D_Stat : 47|4@0+ (1,0) [0|15] "SED"  APIM,APIM_CDC,APIM_CIM,APIM_CISM,IPC
 SG_ SidePrkSnsL2_D_Stat : 51|4@0+ (1,0) [0|15] "SED"  APIM,APIM_CDC,APIM_CIM,APIM_CISM,IPC
 SG_ SidePrkSnsL1_D_Stat : 55|4@0+ (1,0) [0|15] "SED"  APIM,APIM_CDC,APIM_CIM,APIM_CISM,IPC
 SG_ SidePrkSnsR2_D_Stat : 59|4@0+ (1,0) [0|15] "SED"  APIM,APIM_CDC,APIM_CIM,APIM_CISM,IPC
 SG_ SidePrkSnsR1_D_Stat : 63|4@0+ (1,0) [0|15] "SED"  APIM,APIM_CDC,APIM_CIM,APIM_CISM,IPC

BO_ 939 ParkAid_Aud_Warn_Stat2_HS3: 8 GWM
 SG_ ApaLongCtrlEnbl_D_Rq : 0|1@0+ (1,0) [0|1] "SED"  GENERIC
 SG_ PrkAidFront_D_Stat : 2|2@0+ (1,0) [0|3] "SED"  APIM,APIM_CDC,APIM_CIM,APIM_CISM,IPC
 SG_ PrkAidChime_D_Stat : 4|2@0+ (1,0) [0|3] "SED"  APIM_CDC,APIM_CIM,IPC
 SG_ PrkAid_D_Falt : 7|3@0+ (1,0) [0|7] "SED"  APIM_CDC,APIM_CIM,IPC
 SG_ PrkAidSnsRlCrnr_D_Stat : 11|4@0+ (1,0) [0|15] "SED"  APIM,APIM_CDC,APIM_CIM,APIM_CISM,IPC
 SG_ PrkAidSnsRlCntr_D_Stat : 15|4@0+ (1,0) [0|15] "SED"  APIM,APIM_CDC,APIM_CIM,APIM_CISM,IPC
 SG_ PrkAidSnsRrCntr_D_Stat : 19|4@0+ (1,0) [0|15] "SED"  APIM,APIM_CDC,APIM_CIM,APIM_CISM,IPC
 SG_ ResPrkAidSnsRlSide_D_Stat : 23|4@0+ (1,0) [0|15] "SED"  APIM,APIM_CDC,APIM_CIM,APIM_CISM,IPC
 SG_ ResPrkAidSnsRrSide_D_Stat : 27|4@0+ (1,0) [0|15] "SED"  APIM,APIM_CDC,APIM_CIM,APIM_CISM,IPC
 SG_ PrkAidSnsRrCrnr_D_Stat : 31|4@0+ (1,0) [0|15] "SED"  APIM,APIM_CDC,APIM_CIM,APIM_CISM,IPC
 SG_ PrkAidLamp_D_Rq : 33|2@0+ (1,0) [0|3] "SED"  APIM_CDC,APIM_CIM,FCIMB
 SG_ SidePrkSnsL3_D_Stat : 37|4@0+ (1,0) [0|15] "SED"  APIM,APIM_CDC,APIM_CIM,APIM_CISM,IPC
 SG_ PrkAidRear_D_Stat : 39|2@0+ (1,0) [0|3] "SED"  APIM,APIM_CDC,APIM_CIM,APIM_CISM,IPC
 SG_ SidePrkSnsL4_D_Stat : 43|4@0+ (1,0) [0|15] "SED"  APIM,APIM_CDC,APIM_CIM,APIM_CISM,IPC
 SG_ SidePrkSnsR3_D_Stat : 47|4@0+ (1,0) [0|15] "SED"  APIM,APIM_CDC,APIM_CIM,APIM_CISM,IPC
 SG_ DrTgateMde_D_Stat : 49|2@0+ (1,0) [0|3] "SED"  APIM,APIM_CDC,APIM_CIM,APIM_CISM
 SG_ ApaBrk_D_Rq : 51|2@0+ (1,0) [0|3] "SED"  GENERIC
 SG_ SidePrkSnsR4_D_Stat : 55|4@0+ (1,0) [0|15] "SED"  APIM,APIM_CDC,APIM_CIM,APIM_CISM,IPC
 SG_ ApaBrk_A_Rq : 63|8@0+ (0.05,-12.75) [-12.75|0] "m/sec^2"  GENERIC

BO_ 942 ParkAid_Data2_HS3: 8 GWM
 SG_ PrkAidRdiusLeft_L_Dsply : 7|8@0+ (1,0) [0|255] "unitless"  APIM,APIM_CDC,APIM_CIM,APIM_CISM
 SG_ PrkAidRdiusRight_L_Dsply : 15|8@0+ (1,0) [0|255] "unitless"  APIM,APIM_CDC,APIM_CIM,APIM_CISM
 SG_ ApaControlMode_D_Stat : 16|1@0+ (1,0) [0|1] "SED"  APIM,APIM_CDC,APIM_CIM,APIM_CISM
 SG_ PrkAidAcsyRear_D_Stat : 18|2@0+ (1,0) [0|3] "SED"  APIM_CDC,APIM_CIM,IPC
 SG_ PrkAidAcsyFront_D_Stat : 20|2@0+ (1,0) [0|3] "SED"  APIM_CDC,APIM_CIM,IPC
 SG_ PrkAidDrvDir_D_Stat : 23|3@0+ (1,0) [0|7] "SED"  APIM,APIM_CDC,APIM_CIM,APIM_CISM
 SG_ ApaParkInSel_B_Avail : 24|1@0+ (1,0) [0|1] "SED"  APIM,APIM_CDC,APIM_CIM,APIM_CISM
 SG_ ApaMsgTxt_D2_Stat : 28|4@0+ (1,0) [0|15] "SED"  APIM,APIM_CDC,APIM_CIM,APIM_CISM
 SG_ ApaDynmcSlot_B_Stat : 29|1@0+ (1,0) [0|1] "SED"  APIM,APIM_CDC,APIM_CIM,APIM_CISM
 SG_ ApaDisplayMode_D_Stat : 31|2@0+ (1,0) [0|3] "SED"  APIM,APIM_CDC,APIM_CIM,APIM_CISM
 SG_ ApaSys_D2_Stat : 35|4@0+ (1,0) [0|15] "SED"  APIM,APIM_CDC,APIM_CIM,APIM_CISM
 SG_ ApaSlotTrgt_D_Stat : 39|4@0+ (1,0) [0|15] "SED"  APIM,APIM_CDC,APIM_CIM,APIM_CISM
 SG_ ApaDrvRq1MsgTxt_D_Rq : 42|3@0+ (1,0) [0|7] "SED"  APIM,APIM_CDC,APIM_CIM,APIM_CISM
 SG_ ApaSlotOption_B_Avail : 43|1@0+ (1,0) [0|1] "SED"  APIM,APIM_CDC,APIM_CIM,APIM_CISM
 SG_ ApaSlotAlrtSet_B_Stat : 44|1@0+ (1,0) [0|1] "SED"  APIM,APIM_CDC,APIM_CIM,APIM_CISM
 SG_ ApaSlotAlrt_B_Rq : 45|1@0+ (1,0) [0|1] "SED"  APIM,APIM_CDC,APIM_CIM,APIM_CISM
 SG_ ApaRmtFeatSel_B_Avail : 46|1@0+ (1,0) [0|1] "SED"  APIM,APIM_CDC,APIM_CIM,APIM_CISM
 SG_ ApaParkOutSel_B_Avail : 47|1@0+ (1,0) [0|1] "SED"  APIM,APIM_CDC,APIM_CIM,APIM_CISM
 SG_ PrkBrkElRleas_B_RqApa : 50|1@0+ (1,0) [0|1] "SED" Vector__XXX
 SG_ ApaOffOptnSel_B_Avail : 51|1@0+ (1,0) [0|1] "SED"  APIM,APIM_CDC,APIM_CIM,APIM_CISM
 SG_ ApaDrvRq2MsgTxt_D_Rq : 55|4@0+ (1,0) [0|15] "SED"  APIM,APIM_CDC,APIM_CIM,APIM_CISM

BO_ 945 Body_Info_7_HS3: 8 GWM
 SG_ PrkLckCtlMsgTxt_D2_Rq : 2|3@0+ (1,0) [0|7] "SED"  APIM,APIM_CDC,APIM_CIM,APIM_CISM,IPC
 SG_ PrkLckCtlLatch_B_Rq : 3|1@0+ (1,0) [0|1] "SED"  APIM_CDC,APIM_CIM,IPC
 SG_ KeyOffMde_D_Actl : 7|4@0+ (1,0) [0|15] "SED"  ACM,APIM,APIM_CDC,APIM_CIM,APIM_CISM,ARM,IPC,TRM_ITRM
 SG_ KeyPadCodeDgt2_D_Dsply : 11|4@0+ (1,0) [0|15] "SED"  APIM_CDC,APIM_CIM,IPC
 SG_ KeyPadCodeDgt1_D_Dsply : 15|4@0+ (1,0) [0|15] "SED"  APIM_CDC,APIM_CIM,IPC
 SG_ KeyPadCodeDgt4_D_Dsply : 19|4@0+ (1,0) [0|15] "SED"  APIM_CDC,APIM_CIM,IPC
 SG_ KeyPadCodeDgt3_D_Dsply : 23|4@0+ (1,0) [0|15] "SED"  APIM_CDC,APIM_CIM,IPC
 SG_ KeyPadCodeDgt6_D_Dsply : 27|4@0+ (1,0) [0|15] "SED"  APIM_CDC,APIM_CIM,IPC
 SG_ KeyPadCodeDgt5_D_Dsply : 31|4@0+ (1,0) [0|15] "SED"  APIM_CDC,APIM_CIM,IPC
 SG_ PwLoApim_T_Actl : 34|11@0+ (1,0) [0|2047] "minute"  APIM,APIM_CDC,APIM_CIM,APIM_CISM
 SG_ KeyPadCodeDgt7_D_Dsply : 39|4@0+ (1,0) [0|15] "SED"  APIM_CDC,APIM_CIM,IPC
 SG_ DelvrAsstMsgTxt_D_Rq : 51|4@0+ (1,0) [0|15] "SED"  APIM_CDC,IPC
 SG_ StrtrMtrCtlMsgTxt_D_Rq2 : 55|4@0+ (1,0) [0|15] "SED"  APIM_CDC,APIM_CIM,IPC
 SG_ DrMatRleas_B_Rq : 60|1@0+ (1,0) [0|1] "SED"  APIM,APIM_CDC,APIM_CIM,APIM_CISM,IPC
 SG_ DrMatChime_B_Rq : 61|1@0+ (1,0) [0|1] "SED"  APIM,APIM_CDC,APIM_CIM,APIM_CISM,IPC
 SG_ PaseKeySearch_Stat : 62|1@0+ (1,0) [0|1] "SED" Vector__XXX
 SG_ BrkPtsActv_B_Stat : 63|1@0+ (1,0) [0|1] "SED"  APIM_CDC,APIM_CIM

BO_ 946 BodyInfo_3_HS3: 8 GWM
 SG_ DrStatTgate_B_Actl : 0|1@0+ (1,0) [0|1] "SED"  ACM,APIM,APIM_CDC,APIM_CIM,APIM_CISM,IPC,TRM_ITRM
 SG_ FogLghtRearOn_B_Stat : 1|1@0+ (1,0) [0|1] "SED"  APIM_CDC,APIM_CIM,APIM_CISM,IPC,TRM_ITRM
 SG_ Parklamp_Status : 3|2@0+ (1,0) [0|3] "SED"  ACM,APIM,APIM_CDC,APIM_CIM,APIM_CISM,ARM,IPC,RACM_RCIM,TRM_ITRM
 SG_ Ignition_Status : 7|4@0+ (1,0) [0|15] "SED"  ACM,APIM,APIM_CDC,APIM_CIM,APIM_CISM,ARM,DSP,ESPM,HUD_ADV,IPC,MRCMB_RDAPM_HS3,RACM_RCIM,TRM_ITRM,WCM,WCMB,WCMC
 SG_ TurnLghtLeft_D_Rq : 9|2@0+ (1,0) [0|3] "SED"  APIM_CIM,APIM_CISM,TRM_ITRM
 SG_ BodySrvcRqd_B_Rq : 10|1@0+ (1,0) [0|1] "SED"  APIM_CDC,APIM_CIM,IPC
 SG_ Key_In_Ignition_Stat : 11|1@0+ (1,0) [0|1] "SED"  ACM,APIM,APIM_CDC,APIM_CIM,APIM_CISM,DSP,IPC
 SG_ Remote_Start_Status : 13|2@0+ (1,0) [0|3] "SED"  APIM,APIM_CDC,APIM_CIM,APIM_CISM,ARM,IPC
 SG_ Day_Night_Status : 15|2@0+ (1,0) [0|3] "SED"  ACM,APIM,APIM_CDC,APIM_CIM,APIM_CISM,ARM,HUD_ADV,IPC,MRCMB_RDAPM_HS3,RACM_RCIM,TRM_ITRM
 SG_ ValetMode_D_Mem : 16|1@0+ (1,0) [0|1] "SED"  GENERIC
 SG_ DimmingLvlEvnt_No_Actl : 18|2@0+ (1,0) [0|3] "unitless"  APIM_CDC,APIM_CIM,IPC
 SG_ DrStatDrvErrCnt_B_Stat : 19|1@0+ (1,0) [0|1] "SED" Vector__XXX
 SG_ Backlit_LED_Status : 23|4@0+ (1,0) [0|15] "SED"  APIM,APIM_CDC,APIM_CIM,APIM_CISM,MRCMB_RDAPM_HS3,TRM_ITRM
 SG_ Dimming_Lvl : 31|8@0+ (1,0) [0|255] "SED"  ACM,APIM,APIM_CDC,APIM_CIM,APIM_CISM,ARM,HUD_ADV,IPC,MRCMB_RDAPM_HS3,RACM_RCIM,TRM_ITRM
 SG_ FuelPmpInhbt_B_Stat : 32|1@0+ (1,0) [0|1] "SED" Vector__XXX
 SG_ CrashEvnt_D_Stat : 34|2@0+ (1,0) [0|3] "SED"  ARM
 SG_ TurnLghtRightOn_B_Stat : 35|1@0+ (1,0) [0|1] "SED"  ACM,APIM_CDC,APIM_CIM,APIM_CISM,HUD_ADV,IPC
 SG_ IgnKeyType_D_Actl : 39|4@0+ (1,0) [0|15] "SED"  ACM,APIM,APIM_CDC,APIM_CIM,APIM_CISM,DSP,IPC
 SG_ Litval : 47|8@0+ (1,0) [0|255] "SED"  ACM,APIM,APIM_CDC,APIM_CIM,APIM_CISM,ARM,IPC,MRCMB_RDAPM_HS3,RACM_RCIM
 SG_ DrStatRl_B_Actl : 48|1@0+ (1,0) [0|1] "SED"  ACM,APIM,APIM_CDC,APIM_CIM,APIM_CISM,HUD_ADV,IPC,TRM_ITRM
 SG_ DrStatRr_B_Actl : 49|1@0+ (1,0) [0|1] "SED"  ACM,APIM,APIM_CDC,APIM_CIM,APIM_CISM,HUD_ADV,IPC,TRM_ITRM
 SG_ LifeCycMde_D_Actl : 53|4@0+ (1,0) [0|15] "SED"  ACM,APIM,APIM_CDC,APIM_CIM,APIM_CISM,DSP,HUD_ADV,IPC,RACM_RCIM,TRM_ITRM,WCM,WCMB,WCMC
 SG_ TurnLghtLeftOn_B_Stat : 54|1@0+ (1,0) [0|1] "SED"  ACM,APIM_CDC,APIM_CIM,APIM_CISM,DSP,HUD_ADV,IPC
 SG_ PrkBrkActv_B_Actl : 55|1@0+ (1,0) [0|1] "SED"  APIM,APIM_CDC,APIM_CIM,APIM_CISM,IPC
 SG_ FogLghtFrontOn_B_Stat : 56|1@0+ (1,0) [0|1] "SED"  APIM,APIM_CDC,APIM_CIM,APIM_CISM,ARM,IPC
 SG_ Delay_Accy : 57|1@0+ (1,0) [0|1] "SED"  ACM,APIM,APIM_CDC,APIM_CIM,APIM_CISM,ARM,DSP,HUD_ADV,IPC,WCM,WCMB,WCMC
 SG_ DrStatInnrTgate_B_Actl : 58|1@0+ (1,0) [0|1] "SED"  ACM,APIM,APIM_CDC,APIM_CIM,APIM_CISM,HUD_ADV,IPC,TRM_ITRM
 SG_ DrStatHood_B_Actl : 59|1@0+ (1,0) [0|1] "SED"  ACM,APIM,APIM_CDC,APIM_CIM,APIM_CISM,IPC
 SG_ DrStatPsngr_B_Actl : 60|1@0+ (1,0) [0|1] "SED"  ACM,APIM,APIM_CDC,APIM_CIM,APIM_CISM,HUD_ADV,IPC,TRM_ITRM
 SG_ DrStatDrv_B_Actl : 61|1@0+ (1,0) [0|1] "SED"  ACM,APIM,APIM_CDC,APIM_CIM,APIM_CISM,HUD_ADV,IPC,TRM_ITRM
 SG_ TurnLghtRight_D_Rq : 63|2@0+ (1,0) [0|3] "SED"  APIM_CIM,APIM_CISM,DSP,TRM_ITRM

BO_ 948 Tire_Pressure_Status_HS3: 8 GWM
 SG_ TirePReset_D_Stat : 1|2@0+ (1,0) [0|3] "Discrete"  APIM,APIM_CDC,APIM_CIM,APIM_CISM,IPC
 SG_ Tire_Press_Telltale : 3|2@0+ (1,0) [0|3] "SED"  APIM,APIM_CDC,APIM_CIM,APIM_CISM,IPC
 SG_ Tire_Press_System_Stat : 7|4@0+ (1,0) [0|15] "SED"  APIM,APIM_CDC,APIM_CIM,APIM_CISM,IPC
 SG_ Tire_Press_RF_Stat : 11|4@0+ (1,0) [0|15] "SED"  APIM,APIM_CDC,APIM_CIM,APIM_CISM,HUD_ADV,IPC
 SG_ Tire_Press_LF_Stat : 15|4@0+ (1,0) [0|15] "SED"  APIM,APIM_CDC,APIM_CIM,APIM_CISM,HUD_ADV,IPC
 SG_ Tire_Press_LR_OLR_Stat : 19|4@0+ (1,0) [0|15] "SED"  APIM,APIM_CDC,APIM_CIM,APIM_CISM,HUD_ADV,IPC
 SG_ Tire_Press_RR_ORR_Stat : 23|4@0+ (1,0) [0|15] "SED"  APIM,APIM_CDC,APIM_CIM,APIM_CISM,HUD_ADV,IPC
 SG_ Tire_Press_ILR_Stat : 27|4@0+ (1,0) [0|15] "SED"  APIM,APIM_CDC,APIM_CIM,APIM_CISM,HUD_ADV,IPC
 SG_ Tire_Press_IRR_Stat : 31|4@0+ (1,0) [0|15] "SED"  APIM,APIM_CDC,APIM_CIM,APIM_CISM,HUD_ADV,IPC
 SG_ Tire_Press_Placrd_Frnt : 39|8@0+ (1,0) [0|255] "pounds/inch^2"  APIM,APIM_CDC,APIM_CIM,APIM_CISM,IPC
 SG_ Tire_Press_Placrd_Rear : 47|8@0+ (1,0) [0|255] "pounds/inch^2"  APIM,APIM_CDC,APIM_CIM,APIM_CISM,IPC
 SG_ TlghtTestPrecnd_D2_Stat : 52|3@0+ (1,0) [0|7] "SED"  APIM,APIM_CDC,APIM_CIM,APIM_CISM
 SG_ TlghtTestLght_D2_Stat : 55|3@0+ (1,0) [0|7] "SED"  APIM,APIM_CDC,APIM_CIM,APIM_CISM

BO_ 949 Tire_Pressure_Data_HS3: 8 GWM
 SG_ Tire_Press_LF_Data : 7|16@0+ (1,0) [0|65535] "kilopascal"  APIM,APIM_CDC,APIM_CIM,APIM_CISM,IPC
 SG_ Tire_Press_RF_Data : 23|16@0+ (1,0) [0|65535] "kilopascal"  APIM,APIM_CDC,APIM_CIM,APIM_CISM,IPC
 SG_ Tire_Press_RR_ORR_Data : 39|16@0+ (1,0) [0|65535] "kilopascal"  APIM,APIM_CDC,APIM_CIM,APIM_CISM,IPC
 SG_ Tire_Press_LR_OLR_Data : 55|16@0+ (1,0) [0|65535] "kilopascal"  APIM,APIM_CDC,APIM_CIM,APIM_CISM,IPC

BO_ 952 Tire_Pressure_Data_DRW_HS3: 8 GWM
 SG_ Tire_Press_ILR_Data : 7|16@0+ (1,0) [0|65535] "kilopascal"  APIM,APIM_CDC,APIM_CIM,APIM_CISM,IPC
 SG_ Tire_Press_IRR_Data : 23|16@0+ (1,0) [0|65535] "kilopascal"  APIM,APIM_CDC,APIM_CIM,APIM_CISM,IPC

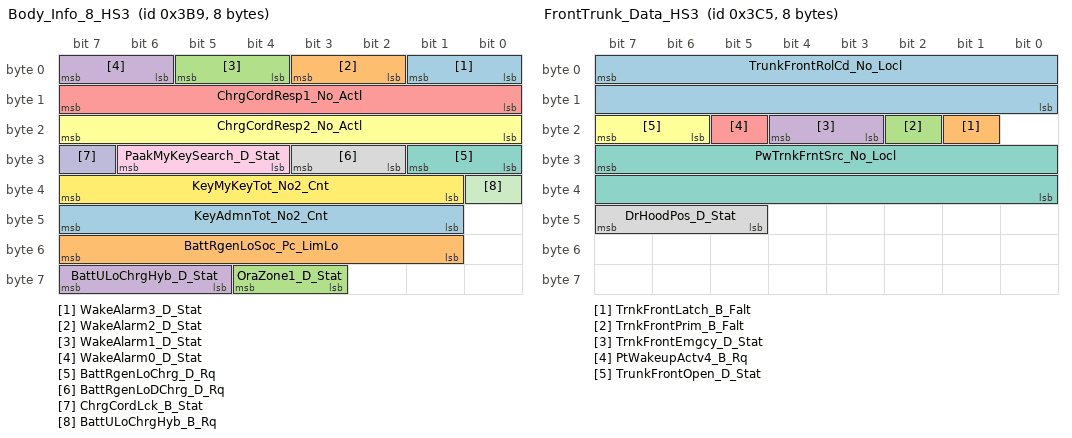
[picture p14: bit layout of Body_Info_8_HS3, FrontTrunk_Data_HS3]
BO_ 953 Body_Info_8_HS3: 8 GWM
 SG_ WakeAlarm3_D_Stat : 1|2@0+ (1,0) [0|3] "SED" Vector__XXX
 SG_ WakeAlarm2_D_Stat : 3|2@0+ (1,0) [0|3] "SED"  TRM_ITRM
 SG_ WakeAlarm1_D_Stat : 5|2@0+ (1,0) [0|3] "SED" Vector__XXX
 SG_ WakeAlarm0_D_Stat : 7|2@0+ (1,0) [0|3] "SED" Vector__XXX
 SG_ ChrgCordResp1_No_Actl : 15|8@0+ (1,0) [0|255] "unitless" Vector__XXX
 SG_ ChrgCordResp2_No_Actl : 23|8@0+ (1,0) [0|255] "unitless" Vector__XXX
 SG_ BattRgenLoChrg_D_Rq : 25|2@0+ (1,0) [0|3] "SED" Vector__XXX
 SG_ BattRgenLoDChrg_D_Rq : 27|2@0+ (1,0) [0|3] "SED" Vector__XXX
 SG_ PaakMyKeySearch_D_Stat : 30|3@0+ (1,0) [0|7] "SED"  APIM,APIM_CDC,APIM_CIM,APIM_CISM
 SG_ ChrgCordLck_B_Stat : 31|1@0+ (1,0) [0|1] "SED" Vector__XXX
 SG_ BattULoChrgHyb_B_Rq : 32|1@0+ (1,0) [0|1] "SED" Vector__XXX
 SG_ KeyMyKeyTot_No2_Cnt : 39|7@0+ (1,0) [0|127] "unitless"  APIM,APIM_CDC,APIM_CIM,APIM_CISM
 SG_ KeyAdmnTot_No2_Cnt : 47|7@0+ (1,0) [0|127] "unitless"  APIM,APIM_CDC,APIM_CIM,APIM_CISM
 SG_ BattRgenLoSoc_Pc_LimLo : 55|7@0+ (1,0) [0|100] "percent" Vector__XXX
 SG_ OraZone1_D_Stat : 60|2@0+ (1,0) [0|3] "unitless"  APIM_CDC
 SG_ BattULoChrgHyb_D_Stat : 63|3@0+ (1,0) [0|7] "SED"  APIM_CDC,APIM_CIM,IPC

BO_ 954 Body_Info_10_HS3: 8 GWM
 SG_ ExtLght_D_Falt : 1|2@0+ (1,0) [0|3] "SED"  APIM,APIM_CDC,APIM_CIM,APIM_CISM
 SG_ GenericSwtch2_No_Actl : 4|3@0+ (1,0) [0|7] "unitless"  IPC,TRM_ITRM
 SG_ GenericSwtch1_No_Actl : 7|3@0+ (1,0) [0|7] "unitless"  TRM_ITRM
 SG_ ExtLghtLeft_D_Stat : 9|2@0+ (1,0) [0|3] "SED"  APIM,APIM_CDC,APIM_CIM,APIM_CISM
 SG_ ExtLghtFront_D_Stat : 11|2@0+ (1,0) [0|3] "SED"  APIM,APIM_CDC,APIM_CIM,APIM_CISM
 SG_ ExtLghtAlrt_B_Rq : 12|1@0+ (1,0) [0|1] "SED"  APIM,APIM_CDC,APIM_CIM,APIM_CISM
 SG_ GenericSwtch3_No_Actl : 15|3@0+ (1,0) [0|7] "unitless"  TRM_ITRM
 SG_ PudSptLghtRight_D_Rq : 17|2@0+ (1,0) [0|3] "SED"  GENERIC
 SG_ PudSptLghtLeft_D_Rq : 19|2@0+ (1,0) [0|3] "SED"  GENERIC
 SG_ ExtLghtRight_D_Stat : 21|2@0+ (1,0) [0|3] "SED"  APIM,APIM_CDC,APIM_CIM,APIM_CISM
 SG_ ExtLghtRear_D_Stat : 23|2@0+ (1,0) [0|3] "SED"  APIM,APIM_CDC,APIM_CIM,APIM_CISM
 SG_ TrukBedLght_B_Stat : 24|1@0+ (1,0) [0|1] "SED"  APIM,APIM_CDC,APIM_CIM,APIM_CISM
 SG_ TrlrHitchLamp_D_Stat : 25|1@0+ (1,0) [0|1] "SED"  APIM,APIM_CDC,APIM_CIM,APIM_CISM
 SG_ LicPlateLght_B_Stat : 26|1@0+ (1,0) [0|1] "SED"  APIM,APIM_CDC,APIM_CIM,APIM_CISM
 SG_ VehWlcmFrwlMde_D_Stat : 29|3@0+ (1,0) [0|7] "SED"  APIM,APIM_CDC,APIM_CIM,APIM_CISM,IPC,RACM_RCIM
 SG_ VehWlcmFrwl_D_Stat : 31|2@0+ (1,0) [0|3] "SED"  APIM,APIM_CDC,APIM_CIM,APIM_CISM,GENERIC,IPC,RACM_RCIM
 SG_ TlghtTest_D_Stat : 33|2@0+ (1,0) [0|3] "SED"  APIM,APIM_CDC,APIM_CIM,APIM_CISM
 SG_ LghtAmbDrvMde_B_Stat : 34|1@0+ (1,0) [0|1] "SED"  APIM,APIM_CDC,APIM_CIM,APIM_CISM
 SG_ PwRnngBoardPoll_D_Stat : 36|2@0+ (1,0) [0|3] "SED"  GENERIC
 SG_ PoliceDmngLvl_D_Stat : 39|3@0+ (1,0) [0|7] "SED"  APIM,APIM_CDC,APIM_CIM,APIM_CISM,IPC
 SG_ LoadShedRelay_B_Rq : 40|1@0+ (1,0) [0|1] "SED" Vector__XXX
 SG_ KeylessIdl_B_Stat : 41|1@0+ (1,0) [0|1] "SED"  APIM,APIM_CDC,APIM_CIM,APIM_CISM
 SG_ TlghtTestLght_D_Stat : 44|3@0+ (1,0) [0|7] "SED"  APIM,APIM_CDC,APIM_CIM,APIM_CISM
 SG_ TlghtTestPrecnd_D_Stat : 47|3@0+ (1,0) [0|7] "SED"  APIM,APIM_CDC,APIM_CIM,APIM_CISM
 SG_ PosLghtFr_D_Stat : 49|2@0+ (1,0) [0|3] "SED" Vector__XXX
 SG_ PosLghtFl_D_Stat : 51|2@0+ (1,0) [0|3] "SED" Vector__XXX
 SG_ LoadShedRelayMde_D_Stat : 53|2@0+ (1,0) [0|3] "SED" Vector__XXX
 SG_ CargoLght_D_Stat : 55|2@0+ (1,0) [0|3] "SED"  APIM,APIM_CDC,APIM_CIM,APIM_CISM
 SG_ TrlrHitchLamp_D2_Stat : 57|2@0+ (1,0) [0|3] "SED"  APIM,APIM_CDC,APIM_CIM,APIM_CISM
 SG_ ChildLckMaint_D_Stat : 59|2@0+ (1,0) [0|3] "SED" Vector__XXX
 SG_ ExtLghtFront_D_RqBody : 61|2@0+ (1,0) [0|3] "SED" Vector__XXX
 SG_ CrtsyLghtRear_D_Stat : 63|2@0+ (1,0) [0|3] "SED"  APIM,APIM_CDC,APIM_CIM,APIM_CISM

BO_ 955 Tire_Temp_Data_HS3: 8 GWM
 SG_ Tire_Temp_ILR_Data : 7|8@0+ (1,-60) [-60|195] "degC"  APIM,APIM_CDC,APIM_CIM,APIM_CISM,IPC
 SG_ Tire_Temp_IRR_Data : 15|8@0+ (1,-60) [-60|195] "degC"  APIM,APIM_CDC,APIM_CIM,APIM_CISM,IPC
 SG_ Tire_Temp_LF_Data : 23|8@0+ (1,-60) [-60|195] "degC"  APIM,APIM_CDC,APIM_CIM,APIM_CISM,IPC
 SG_ Tire_Temp_OLR_Data : 31|8@0+ (1,-60) [-60|195] "degC"  APIM,APIM_CDC,APIM_CIM,APIM_CISM,IPC
 SG_ Tire_Temp_ORR_Data : 39|8@0+ (1,-60) [-60|195] "degC"  APIM,APIM_CDC,APIM_CIM,APIM_CISM,IPC
 SG_ Tire_Temp_RF_Data : 47|8@0+ (1,-60) [-60|195] "degC"  APIM,APIM_CDC,APIM_CIM,APIM_CISM,IPC

BO_ 963 BCM_Lamp_Stat_HS3: 8 GWM
 SG_ PerimeterAlarmChimeRq : 0|1@0+ (1,0) [0|1] "SED"  APIM_CDC,APIM_CIM,IPC
 SG_ HeadLghtHiOn_B_Stat : 1|1@0+ (1,0) [0|1] "SED"  APIM,APIM_CDC,APIM_CIM,APIM_CISM,IPC
 SG_ HeadLampLoFrOn_B_Stat : 2|1@0+ (1,0) [0|1] "SED" Vector__XXX
 SG_ HeadLampLoFlOn_B_Stat : 3|1@0+ (1,0) [0|1] "SED" Vector__XXX
 SG_ HeadLampLoActv_B_Stat : 4|1@0+ (1,0) [0|1] "SED"  APIM,APIM_CDC,APIM_CIM,APIM_CISM
 SG_ DayRnngLampOn_B_Stat : 5|1@0+ (1,0) [0|1] "SED"  APIM,APIM_CDC,APIM_CIM,APIM_CISM,IPC
 SG_ Courtesy_BSave_Stat : 7|2@0+ (1,0) [0|3] "SED"  ACM,APIM_CDC,APIM_CIM,TRM_ITRM
 SG_ StopLghtOn_B_Stat : 8|1@0+ (1,0) [0|1] "SED"  TRM_ITRM
 SG_ RvrseLghtOn_B_Stat : 9|1@0+ (1,0) [0|1] "SED"  APIM,APIM_CDC,APIM_CIM,APIM_CISM,TRM_ITRM
 SG_ PudLamp_D_Rq : 11|2@0+ (1,0) [0|3] "SED"  APIM,APIM_CDC,APIM_CIM,APIM_CISM,HUD_ADV
 SG_ PrkLght_D_Stat : 13|2@0+ (1,0) [0|3] "SED"  TRM_ITRM
 SG_ HeadLghtSwtch_D_Stat : 15|2@0+ (1,0) [0|3] "SED"  APIM_CDC,APIM_CIM,IPC
 SG_ Perimeter_Alarm_Status : 17|2@0+ (1,0) [0|3] "SED"  APIM,APIM_CDC,APIM_CIM,TRM_ITRM
 SG_ ReducedGuard_D_Stat : 19|2@0+ (1,0) [0|3] "SED"  APIM_CDC,APIM_CIM,IPC
 SG_ BrkWarnInd_B_Rq : 20|1@0+ (1,0) [0|1] "SED"  APIM_CDC,APIM_CIM,IPC
 SG_ WndwGlbl_D_Cmd : 23|3@0+ (1,0) [0|7] "SED" Vector__XXX
 SG_ TrnNotInPrkChime_B_Rq : 24|1@0+ (1,0) [0|1] "SED"  APIM_CDC,APIM_CIM,IPC
 SG_ PrkLightChime_B_Rq : 25|1@0+ (1,0) [0|1] "SED"  APIM_CDC,APIM_CIM,IPC
 SG_ Park_Brake_Chime_Rqst : 26|1@0+ (1,0) [0|1] "SED"  APIM_CDC,APIM_CIM,IPC
 SG_ KeyInIgnWarn_B_Cmd : 27|1@0+ (1,0) [0|1] "SED"  APIM_CDC,APIM_CIM,IPC
 SG_ HomeSafeLtChime_B_Rq : 28|1@0+ (1,0) [0|1] "SED"  APIM_CDC,APIM_CIM,IPC
 SG_ Headlamp_On_Wrning_Cmd : 29|1@0+ (1,0) [0|1] "SED"  APIM_CDC,APIM_CIM,IPC
 SG_ Brk_Fluid_Lvl_Low : 31|2@0+ (1,0) [0|3] "SED"  APIM_CDC,APIM_CIM,IPC
 SG_ HeadLampLoOut_B_Stat : 32|1@0+ (1,0) [0|1] "SED"  APIM_CDC,APIM_CIM,IPC
 SG_ CrnrLghtLeft_Pc_Rq : 39|7@0+ (1,0) [0|100] "percent" Vector__XXX
 SG_ WrlssAcsyChrgInhbt_B_Rq : 40|1@0+ (1,0) [0|1] "SED"  WCM,WCMB,WCMC
 SG_ CrnrLghtRight_Pc_Rq : 47|7@0+ (1,0) [0|100] "percent" Vector__XXX
 SG_ Dr_Courtesy_Light_Stat : 49|2@0+ (1,0) [0|3] "SED" Vector__XXX
 SG_ Courtesy_Delay_Status : 51|2@0+ (1,0) [0|3] "SED" Vector__XXX
 SG_ ImpactEvntFdbck_D_Stat : 53|2@0+ (1,0) [0|3] "SED" Vector__XXX
 SG_ HeadLghtHiFdbck_D_Stat : 55|2@0+ (1,0) [0|3] "SED" Vector__XXX
 SG_ PudLampPsngr_D_Rq : 57|2@0+ (1,0) [0|3] "SED" Vector__XXX
 SG_ PudLampDrv_D_Rq : 59|2@0+ (1,0) [0|3] "SED" Vector__XXX
 SG_ DrTgateLck_D_Stat : 61|2@0+ (1,0) [0|3] "SED"  APIM_CDC,APIM_CIM,IPC
 SG_ Illuminated_Entry_Stat : 63|2@0+ (1,0) [0|3] "SED" Vector__XXX

BO_ 965 FrontTrunk_Data_HS3: 8 GWM
 SG_ TrunkFrontRolCd_No_Locl : 7|16@0+ (1,0) [0|65535] "unitless" Vector__XXX
 SG_ TrnkFrontLatch_B_Falt : 17|1@0+ (1,0) [0|1] "SED" Vector__XXX
 SG_ TrnkFrontPrim_B_Falt : 18|1@0+ (1,0) [0|1] "SED"  APIM_CDC,APIM_CIM,IPC
 SG_ TrnkFrontEmgcy_D_Stat : 20|2@0+ (1,0) [0|3] "SED"  APIM_CDC,APIM_CIM,IPC
 SG_ PtWakeupActv4_B_Rq : 21|1@0+ (1,0) [0|1] "SED" Vector__XXX
 SG_ TrunkFrontOpen_D_Stat : 23|2@0+ (1,0) [0|3] "SED"  APIM,APIM_CDC,APIM_CIM,APIM_CISM
 SG_ PwTrnkFrntSrc_No_Locl : 31|16@0+ (1,0) [0|65535] "unitless" Vector__XXX
 SG_ DrHoodPos_D_Stat : 47|3@0+ (1,0) [0|7] "SED" Vector__XXX

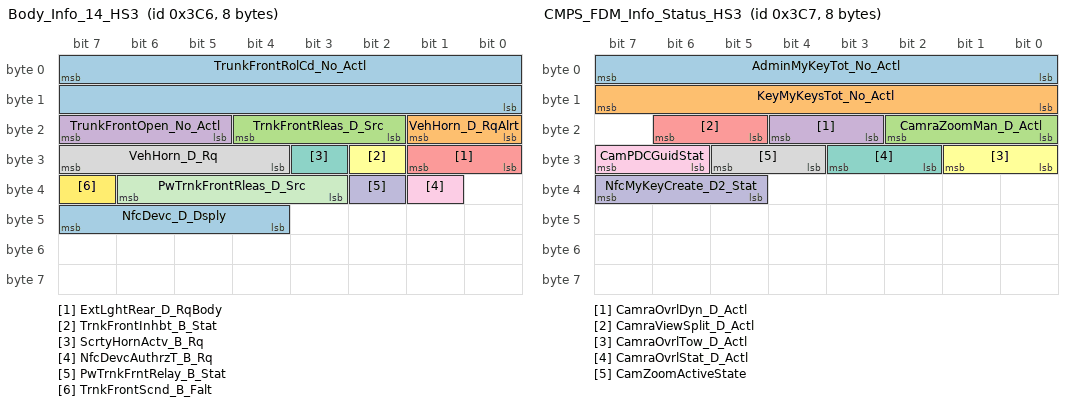
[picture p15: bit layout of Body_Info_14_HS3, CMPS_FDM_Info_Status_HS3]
BO_ 966 Body_Info_14_HS3: 8 GWM
 SG_ TrunkFrontRolCd_No_Actl : 7|16@0+ (1,0) [0|65535] "unitless" Vector__XXX
 SG_ VehHorn_D_RqAlrt : 17|2@0+ (1,0) [0|3] "SED" Vector__XXX
 SG_ TrnkFrontRleas_D_Src : 20|3@0+ (1,0) [0|7] "SED" Vector__XXX
 SG_ TrunkFrontOpen_No_Actl : 23|3@0+ (1,0) [0|7] "unitless" Vector__XXX
 SG_ ExtLghtRear_D_RqBody : 25|2@0+ (1,0) [0|3] "SED" Vector__XXX
 SG_ TrnkFrontInhbt_B_Stat : 26|1@0+ (1,0) [0|1] "SED" Vector__XXX
 SG_ ScrtyHornActv_B_Rq : 27|1@0+ (1,0) [0|1] "SED" Vector__XXX
 SG_ VehHorn_D_Rq : 31|4@0+ (1,0) [0|15] "SED" Vector__XXX
 SG_ NfcDevcAuthrzT_B_Rq : 33|1@0+ (1,0) [0|1] "SED" Vector__XXX
 SG_ PwTrnkFrntRelay_B_Stat : 34|1@0+ (1,0) [0|1] "SED" Vector__XXX
 SG_ PwTrnkFrontRleas_D_Src : 38|4@0+ (1,0) [0|15] "SED" Vector__XXX
 SG_ TrnkFrontScnd_B_Falt : 39|1@0+ (1,0) [0|1] "SED"  APIM_CDC,APIM_CIM,IPC
 SG_ NfcDevc_D_Dsply : 47|4@0+ (1,0) [0|15] "SED"  APIM_CDC,APIM_CIM,IPC

BO_ 967 CMPS_FDM_Info_Status_HS3: 8 GWM
 SG_ AdminMyKeyTot_No_Actl : 7|8@0+ (1,0) [0|255] "unitless"  APIM,APIM_CDC,APIM_CIM
 SG_ KeyMyKeysTot_No_Actl : 15|8@0+ (1,0) [0|255] "unitless"  APIM,APIM_CDC,APIM_CIM
 SG_ CamraZoomMan_D_Actl : 18|3@0+ (1,0) [0|7] "SED"  APIM,APIM_CDC,APIM_CIM,APIM_CISM
 SG_ CamraOvrlDyn_D_Actl : 20|2@0+ (1,0) [0|3] "SED"  APIM,APIM_CDC,APIM_CIM,APIM_CISM
 SG_ CamraViewSplit_D_Actl : 22|2@0+ (1,0) [0|3] "SED"  APIM,APIM_CDC,APIM_CIM,APIM_CISM
 SG_ CamraOvrlTow_D_Actl : 25|2@0+ (1,0) [0|3] "SED"  APIM,APIM_CDC,APIM_CIM,APIM_CISM
 SG_ CamraOvrlStat_D_Actl : 27|2@0+ (1,0) [0|3] "SED"  APIM,APIM_CDC,APIM_CIM,APIM_CISM
 SG_ CamZoomActiveState : 29|2@0+ (1,0) [0|3] "SED"  APIM,APIM_CDC,APIM_CIM,APIM_CISM
 SG_ CamPDCGuidStat : 31|2@0+ (1,0) [0|3] "SED"  APIM,APIM_CDC,APIM_CIM,APIM_CISM
 SG_ NfcMyKeyCreate_D2_Stat : 39|3@0+ (1,0) [0|7] "SED"  APIM,APIM_CDC,APIM_CIM

BO_ 968 Cluster_Lighting_Rq: 8 APIM_CDC
 SG_ Dimming_Level_Cmd : 1|2@0+ (1,0) [0|3] "SED"  GWM
 SG_ BlendedColorBlue_Cmd : 5|4@0+ (1,0) [0|15] "SED"  GWM
 SG_ BlendedColor_Cmd : 7|2@0+ (1,0) [0|3] "SED"  GWM
 SG_ BlendedColorRed_Cmd : 11|4@0+ (1,0) [0|15] "SED"  GWM
 SG_ BlendedColorGreen_Cmd : 15|4@0+ (1,0) [0|15] "SED"  GWM
 SG_ BrkDrvMde_D_Rq : 18|3@0+ (1,0) [0|7] "SED"  GWM
 SG_ Current_Color_Cmd : 23|4@0+ (1,0) [0|15] "SED"  GWM
 SG_ BlendedColor_CmdGage : 25|2@0+ (1,0) [0|3] "SED"  GWM
 SG_ SlMde_D_Rq : 27|2@0+ (1,0) [0|3] "SED"  GWM
 SG_ IsaOffst_D_Rq : 31|4@0+ (1,0) [0|15] "SED"  GWM
 SG_ BlendColorGrn_CmdGage : 35|4@0+ (1,0) [0|15] "SED"  GWM
 SG_ BlendColorBlue_CmdGage : 39|4@0+ (1,0) [0|15] "SED"  GWM
 SG_ CurrentColor_CmdGage : 43|4@0+ (1,0) [0|15] "SED"  GWM
 SG_ BlendColorRed_CmdGage : 47|4@0+ (1,0) [0|15] "SED"  GWM
 SG_ LnchCtl_N_Rq : 55|8@0+ (50,0) [0|12750] "rpm"  GWM
 SG_ IpcLvl_B_Type : 56|1@0+ (1,0) [0|1] "SED"  GWM
 SG_ RvltnMatchAllw_D_Rq : 58|2@0+ (1,0) [0|3] "SED"  GWM
 SG_ SuspDrvMde_D_Rq : 61|3@0+ (1,0) [0|7] "SED"  GWM
 SG_ LnchCtl_D_Rq : 63|2@0+ (1,0) [0|3] "SED"  GWM

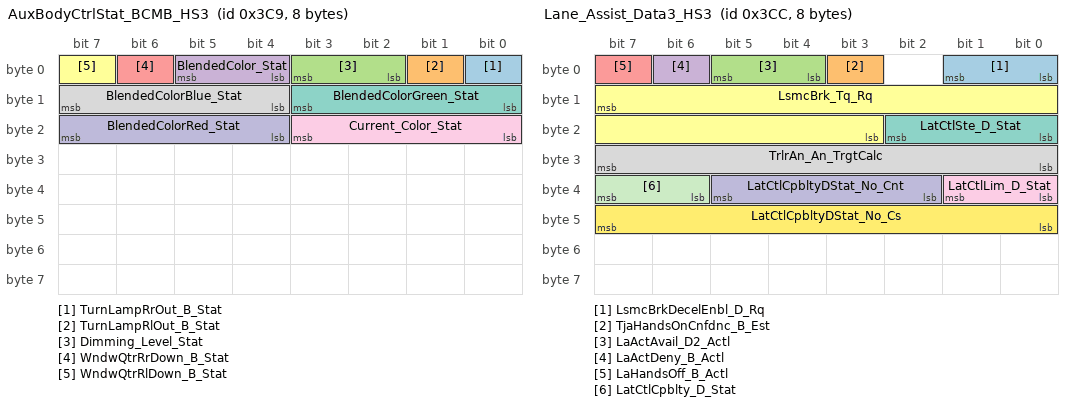
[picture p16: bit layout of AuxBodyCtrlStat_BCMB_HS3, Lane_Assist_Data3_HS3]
BO_ 969 AuxBodyCtrlStat_BCMB_HS3: 8 GWM
 SG_ TurnLampRrOut_B_Stat : 0|1@0+ (1,0) [0|1] "SED" Vector__XXX
 SG_ TurnLampRlOut_B_Stat : 1|1@0+ (1,0) [0|1] "SED" Vector__XXX
 SG_ Dimming_Level_Stat : 3|2@0+ (1,0) [0|3] "SED"  APIM_CDC,APIM_CIM
 SG_ BlendedColor_Stat : 5|2@0+ (1,0) [0|3] "SED"  APIM_CDC,APIM_CIM
 SG_ WndwQtrRrDown_B_Stat : 6|1@0+ (1,0) [0|1] "SED" Vector__XXX
 SG_ WndwQtrRlDown_B_Stat : 7|1@0+ (1,0) [0|1] "SED" Vector__XXX
 SG_ BlendedColorGreen_Stat : 11|4@0+ (1,0) [0|15] "SED"  APIM_CDC,APIM_CIM
 SG_ BlendedColorBlue_Stat : 15|4@0+ (1,0) [0|15] "SED"  APIM_CDC,APIM_CIM
 SG_ Current_Color_Stat : 19|4@0+ (1,0) [0|15] "SED"  APIM_CDC,APIM_CIM
 SG_ BlendedColorRed_Stat : 23|4@0+ (1,0) [0|15] "SED"  APIM_CDC,APIM_CIM

BO_ 972 Lane_Assist_Data3_HS3: 8 GWM
 SG_ LsmcBrkDecelEnbl_D_Rq : 1|2@0+ (1,0) [0|3] "SED" Vector__XXX
 SG_ TjaHandsOnCnfdnc_B_Est : 3|1@0+ (1,0) [0|1] "SED" Vector__XXX
 SG_ LaActAvail_D2_Actl : 5|2@0+ (1,0) [0|3] "SED" Vector__XXX
 SG_ LaActDeny_B_Actl : 6|1@0+ (1,0) [0|1] "SED"  APIM_CDC,APIM_CIM,IPC
 SG_ LaHandsOff_B_Actl : 7|1@0+ (1,0) [0|1] "SED"  APIM_CIM,IPC
 SG_ LsmcBrk_Tq_Rq : 15|13@0+ (4,0) [0|32764] "Nm" Vector__XXX
 SG_ LatCtlSte_D_Stat : 18|3@0+ (1,0) [0|7] "SED" Vector__XXX
 SG_ TrlrAn_An_TrgtCalc : 31|8@0+ (1,-128) [-128|127] "degrees" Vector__XXX
 SG_ LatCtlLim_D_Stat : 33|2@0+ (1,0) [0|3] "SED" Vector__XXX
 SG_ LatCtlCpbltyDStat_No_Cnt : 37|4@0+ (1,0) [0|15] "unitless" Vector__XXX
 SG_ LatCtlCpblty_D_Stat : 39|2@0+ (1,0) [0|3] "SED" Vector__XXX
 SG_ LatCtlCpbltyDStat_No_Cs : 47|8@0+ (1,0) [0|255] "unitless" Vector__XXX

BO_ 973 Traffic_RecogitionData_HS3: 8 GWM
 SG_ TsrOvtkStatMsgTxt_D_Rq : 1|2@0+ (1,0) [0|3] "SED"  APIM_CDC,APIM_CIM,APIM_CISM,HUD_ADV,IPC
 SG_ TsrOswWarnMsgTxt_D_Rq : 3|2@0+ (1,0) [0|3] "SED"  APIM_CDC,APIM_CIM,APIM_CISM,HUD_ADV,IPC
 SG_ TsrMsgTxt_D_Rq : 7|4@0+ (1,0) [0|15] "SED"  APIM_CDC,APIM_CIM,APIM_CISM,IPC
 SG_ TsrStatMsgTxt_D_Rq : 10|3@0+ (1,0) [0|7] "SED"  APIM_CDC,APIM_CIM,APIM_CISM,IPC
 SG_ PersCtaSplitView_D_Stat : 12|2@0+ (1,0) [0|3] "SED"  APIM,APIM_CDC,APIM_CIM,APIM_CISM
 SG_ TsrOvtkMsgTxt_D_Rq : 15|3@0+ (1,0) [0|7] "SED"  APIM_CDC,APIM_CIM,APIM_CISM,HUD_ADV,IPC
 SG_ TsrVl2RstrcMsgTxt_D_Rq : 17|2@0+ (1,0) [0|3] "SED"  APIM_CDC,APIM_CIM,APIM_CISM,IPC
 SG_ RoadSignRgltry_D_Dsply : 19|2@0+ (1,0) [0|3] "SED"  APIM_CDC,APIM_CIM,IPC
 SG_ TsrVl1StatMsgTxt_D_Rq : 21|2@0+ (1,0) [0|3] "SED"  APIM_CDC,APIM_CIM,APIM_CISM,HUD_ADV,IPC
 SG_ TsrVl1RstrcMsgTxt_D_Rq : 23|2@0+ (1,0) [0|3] "SED"  APIM_CDC,APIM_CIM,APIM_CISM,IPC
 SG_ TsrVLim1MsgTxt_D_Rq : 31|8@0+ (1,0) [0|255] "SED"  APIM_CDC,APIM_CIM,APIM_CISM,HUD_ADV,IPC
 SG_ TsrVLim2MsgTxt_D_Rq : 39|8@0+ (1,0) [0|255] "SED"  APIM_CDC,APIM_CIM,APIM_CISM,HUD_ADV,IPC
 SG_ TsrVl1PrmntMsgTxt_D_Rq : 41|2@0+ (1,0) [0|3] "SED"  APIM_CDC,APIM_CIM,APIM_CISM,HUD_ADV,IPC
 SG_ TsrVlUnitMsgTxt_D_Rq : 43|2@0+ (1,0) [0|3] "SED"  APIM,APIM_CDC,APIM_CIM,APIM_CISM,HUD_ADV,IPC
 SG_ TsrChime_D_Rq : 45|2@0+ (1,0) [0|3] "SED"  APIM_CDC,APIM_CIM,IPC
 SG_ TsrVl2StatMsgTxt_D_Rq : 47|2@0+ (1,0) [0|3] "SED"  APIM_CDC,APIM_CIM,APIM_CISM,HUD_ADV,IPC
 SG_ WwaWarn_B_Rq : 48|1@0+ (1,0) [0|1] "SED"  APIM_CDC,APIM_CIM,APIM_CISM,HUD_ADV,IPC
 SG_ TsrVl1RstrcMsgTxt2_D_Rq : 51|3@0+ (1,0) [0|7] "SED"  APIM_CDC,APIM_CIM,APIM_CISM,HUD_ADV,IPC
 SG_ TsrOvtkMsgTxt2_D_Rq : 55|4@0+ (1,0) [0|15] "SED"  APIM_CDC,APIM_CIM,APIM_CISM,HUD_ADV,IPC
 SG_ LaSysOffStat_D_Dsply : 58|2@0+ (1,0) [0|3] "SED"  APIM_CDC,APIM_CIM,IPC
 SG_ TsrVl2PrmntMsgTxt_D_Rq : 60|2@0+ (1,0) [0|3] "SED"  APIM_CDC,APIM_CIM,APIM_CISM,HUD_ADV,IPC
 SG_ TsrVl2RstrcMsgTxt2_D_Rq : 63|3@0+ (1,0) [0|7] "SED"  APIM_CDC,APIM_CIM,APIM_CISM,HUD_ADV,IPC

BO_ 974 DCACA_Data4_HS3: 8 GWM
 SG_ DcacGfciTest_B_Rq : 0|1@0+ (1,0) [0|1] "SED" Vector__XXX
 SG_ DcacElPw_D_Stat : 2|2@0+ (1,0) [0|3] "SED"  APIM,APIM_CDC,APIM_CIM,APIM_CISM
 SG_ PwBedPnlEnbl_B_Rq : 3|1@0+ (1,0) [0|1] "SED"  GENERIC
 SG_ DcacOn_B_Rq : 4|1@0+ (1,0) [0|1] "SED"  GENERIC
 SG_ DcacSys_B_Falt : 5|1@0+ (1,0) [0|1] "SED"  GENERIC
 SG_ DcacLedCtl_D_Rq : 7|2@0+ (1,0) [0|3] "SED"  GENERIC
 SG_ DcacHw_D_Confg : 11|4@0+ (1,0) [0|15] "SED"  APIM,APIM_CDC,APIM_CIM,APIM_CISM
 SG_ DcacFaltMsgTxt_D_Rq : 15|4@0+ (1,0) [0|15] "SED"  APIM,APIM_CDC,APIM_CIM,APIM_CISM
 SG_ DcacOut_Pw_DsplyMx : 23|10@0+ (10,0) [0|10230] "watts"  APIM,APIM_CDC,APIM_CIM,APIM_CISM
 SG_ DcacGfciTestScnd_B_Rq : 24|1@0+ (1,0) [0|1] "SED" Vector__XXX
 SG_ DcacLoFuelMsgTxt_D_Rq : 29|5@0+ (1,0) [0|31] "SED"  APIM,APIM_CDC,APIM_CIM,APIM_CISM
 SG_ DcacOnScnd_B_Rq : 32|1@0+ (1,0) [0|1] "SED" Vector__XXX
 SG_ DcacOut1_Pw_Dsply : 39|7@0+ (100,0) [0|12600] "watts"  APIM,APIM_CDC,APIM_CIM,APIM_CISM
 SG_ DcacSysScnd_B_Falt : 40|1@0+ (1,0) [0|1] "SED" Vector__XXX
 SG_ DcacOut2_Pw_Dsply : 47|7@0+ (100,0) [0|12600] "watts"  APIM,APIM_CDC,APIM_CIM,APIM_CISM
 SG_ PwBedPnlEnblScnd_B_Rq : 48|1@0+ (1,0) [0|1] "SED" Vector__XXX
 SG_ EngExhMdeHrStrt_D_Stat : 53|5@0+ (1,0) [0|31] "SED"  APIM,APIM_CDC,APIM_CIM,APIM_CISM
 SG_ DcacEngOnMsgTxt_D_Rq : 55|2@0+ (1,0) [0|3] "SED"  APIM,APIM_CDC,APIM_CIM,APIM_CISM
 SG_ LowFuelDsplyType_B_Rq : 56|1@0+ (1,0) [0|1] "SED"  APIM_CDC,IPC
 SG_ EngExhMdeHrEnbl_D_Stat : 58|2@0+ (1,0) [0|3] "SED"  APIM,APIM_CDC,APIM_CIM,APIM_CISM
 SG_ EngExhMdeHrEnd_D_Stat : 63|5@0+ (1,0) [0|31] "SED"  APIM,APIM_CDC,APIM_CIM,APIM_CISM

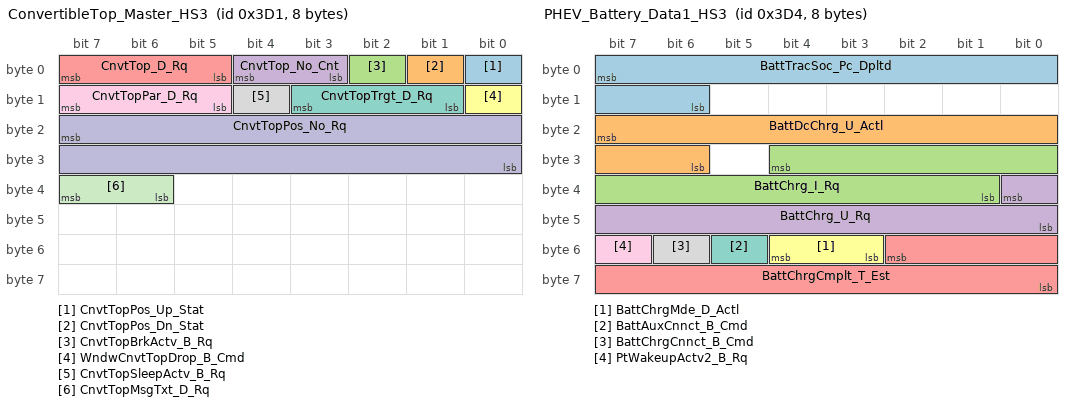
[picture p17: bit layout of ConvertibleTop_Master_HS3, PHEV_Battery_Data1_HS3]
BO_ 977 ConvertibleTop_Master_HS3: 8 GWM
 SG_ CnvtTopPos_Up_Stat : 0|1@0+ (1,0) [0|1] "SED"  ACM,APIM_CDC,APIM_CIM,APIM_CISM,DSP
 SG_ CnvtTopPos_Dn_Stat : 1|1@0+ (1,0) [0|1] "SED"  ACM,APIM_CDC,APIM_CIM,APIM_CISM
 SG_ CnvtTopBrkActv_B_Rq : 2|1@0+ (1,0) [0|1] "SED" Vector__XXX
 SG_ CnvtTop_No_Cnt : 4|2@0+ (1,0) [0|3] "unitless" Vector__XXX
 SG_ CnvtTop_D_Rq : 7|3@0+ (1,0) [0|7] "SED" Vector__XXX
 SG_ WndwCnvtTopDrop_B_Cmd : 8|1@0+ (1,0) [0|1] "SED" Vector__XXX
 SG_ CnvtTopTrgt_D_Rq : 11|3@0+ (1,0) [0|7] "SED" Vector__XXX
 SG_ CnvtTopSleepActv_B_Rq : 12|1@0+ (1,0) [0|1] "SED" Vector__XXX
 SG_ CnvtTopPar_D_Rq : 15|3@0+ (1,0) [0|7] "SED" Vector__XXX
 SG_ CnvtTopPos_No_Rq : 23|16@0+ (1,0) [0|65535] "unitless" Vector__XXX
 SG_ CnvtTopMsgTxt_D_Rq : 39|2@0+ (1,0) [0|3] "SED"  APIM_CDC,APIM_CIM,IPC

BO_ 978 ConvertibleTop_Slave_HS3: 8 GWM
 SG_ CnvtTopDir_B_Falt : 0|1@0+ (1,0) [0|1] "SED" Vector__XXX
 SG_ CnvtTopComplt_D_Stat : 3|3@0+ (1,0) [0|7] "SED" Vector__XXX
 SG_ CnvtTopCnfm_B_Stat : 4|1@0+ (1,0) [0|1] "SED" Vector__XXX
 SG_ CnvtTopClose_D_Stat : 6|2@0+ (1,0) [0|3] "SED" Vector__XXX
 SG_ CnvtTopActv_B_Stat : 7|1@0+ (1,0) [0|1] "SED" Vector__XXX
 SG_ CnvtTopPos_B_Falt : 8|1@0+ (1,0) [0|1] "SED" Vector__XXX
 SG_ CnvtTopOut_B_Falt : 9|1@0+ (1,0) [0|1] "SED" Vector__XXX
 SG_ CnvtTopOpen_D_Stat : 11|2@0+ (1,0) [0|3] "SED" Vector__XXX
 SG_ CnvtTopOpen_B_Stat : 12|1@0+ (1,0) [0|1] "SED" Vector__XXX
 SG_ CnvtTopNom_B_Stat : 13|1@0+ (1,0) [0|1] "SED" Vector__XXX
 SG_ CnvtTopComplt_No_Cnt : 15|2@0+ (1,0) [0|3] "unitless" Vector__XXX
 SG_ CnvtTopRngClose_B_Stat : 16|1@0+ (1,0) [0|1] "SED" Vector__XXX
 SG_ CnvtTopRestrc_B_Falt : 17|1@0+ (1,0) [0|1] "SED" Vector__XXX
 SG_ CnvtTopRdy_B_Stat : 18|1@0+ (1,0) [0|1] "SED" Vector__XXX
 SG_ CnvtTopPosSet_B_Stat : 19|1@0+ (1,0) [0|1] "SED" Vector__XXX
 SG_ CnvtTopPos_D_Stat : 23|4@0+ (1,0) [0|15] "SED"  APIM,APIM_CDC,APIM_CIM,APIM_CISM
 SG_ CnvtTopTWarn_B_Falt : 25|1@0+ (1,0) [0|1] "SED" Vector__XXX
 SG_ CnvtTopTOvr_B_Falt : 26|1@0+ (1,0) [0|1] "SED" Vector__XXX
 SG_ CnvtTopTDir_B_Falt : 27|1@0+ (1,0) [0|1] "SED" Vector__XXX
 SG_ CnvtTopStall_B_Falt : 28|1@0+ (1,0) [0|1] "SED" Vector__XXX
 SG_ CnvtTopSns_B_Falt : 29|1@0+ (1,0) [0|1] "SED" Vector__XXX
 SG_ CnvtTopRvrse_B_Stat : 30|1@0+ (1,0) [0|1] "SED" Vector__XXX
 SG_ CnvtTopRngOpen_B_Stat : 31|1@0+ (1,0) [0|1] "SED" Vector__XXX
 SG_ CnvtTopPos_No_Actl : 39|16@0+ (1,0) [0|65535] "unitless" Vector__XXX
 SG_ TonneuCapMde_D_Stat : 55|2@0+ (1,0) [0|3] "SED" Vector__XXX

BO_ 980 PHEV_Battery_Data1_HS3: 8 GWM
 SG_ BattTracSoc_Pc_Dpltd : 7|10@0+ (0.1,0) [0|102.3] "percent"  APIM,APIM_CDC,APIM_CIM,APIM_CISM
 SG_ BattDcChrg_U_Actl : 23|10@0+ (0.5,0) [0|511.5] "volt" Vector__XXX
 SG_ BattChrg_I_Rq : 28|12@0+ (0.1,0) [0|409.5] "ampere" Vector__XXX
 SG_ BattChrg_U_Rq : 32|9@0+ (1,0) [0|511] "volt"  APIM,APIM_CDC
 SG_ BattChrgCmplt_T_Est : 50|11@0+ (1,0) [0|2047] "minute" Vector__XXX
 SG_ BattChrgMde_D_Actl : 52|2@0+ (1,0) [0|3] "SED" Vector__XXX
 SG_ BattAuxCnnct_B_Cmd : 53|1@0+ (1,0) [0|1] "SED" Vector__XXX
 SG_ BattChrgCnnct_B_Cmd : 54|1@0+ (1,0) [0|1] "SED" Vector__XXX
 SG_ PtWakeupActv2_B_Rq : 55|1@0+ (1,0) [0|1] "SED" Vector__XXX

BO_ 984 IPMA_Data_HS3: 8 GWM
 SG_ FeatConfigIpmaActl : 7|16@0+ (1,0) [0|65535] "Undefined"  APIM,APIM_CDC,APIM_CIM,APIM_CISM,HUD_ADV,IPC
 SG_ FeatNoIpmaActl : 23|16@0+ (1,0) [0|65535] "Number"  APIM,APIM_CDC,APIM_CIM,APIM_CISM,HUD_ADV,IPC
 SG_ LaDenyStats_B_Dsply : 32|1@0+ (1,0) [0|1] "SED"  APIM_CDC,APIM_CIM,IPC
 SG_ HzrdWarnLamp_B_Rq : 33|1@0+ (1,0) [0|1] "SED" Vector__XXX
 SG_ CamraStats_D_Dsply : 35|2@0+ (1,0) [0|3] "SED"  APIM_CDC,APIM_CIM,IPC
 SG_ CamraDefog_B_Req : 36|1@0+ (1,0) [0|1] "SED"  APIM_CDC,APIM_CIM,IPC
 SG_ PersIndexIpma_D_Actl : 39|3@0+ (1,0) [0|7] "SED"  APIM,APIM_CDC,APIM_CIM,APIM_CISM,HUD_ADV,IPC
 SG_ DasAlrtLvl_D_Dsply : 42|3@0+ (1,0) [0|7] "SED"  APIM_CDC,APIM_CIM,IPC
 SG_ DasWarn_D_Dsply : 44|2@0+ (1,0) [0|3] "SED"  APIM_CDC,APIM_CIM,IPC
 SG_ DasFalt_B_Dsply : 45|1@0+ (1,0) [0|1] "SED"  APIM_CDC,IPC
 SG_ DasStats_D_Dsply : 47|2@0+ (1,0) [0|3] "SED"  APIM_CDC,APIM_CIM,IPC
 SG_ LaHandsOff_D_Dsply : 50|2@0+ (1,0) [0|3] "SED"  APIM,APIM_CDC,APIM_CIM,APIM_CISM,HUD_ADV,IPC
 SG_ LaActvStats_D2_Dsply : 55|5@0+ (1,0) [0|31] "SED"  APIM,APIM_CDC,APIM_CIM,APIM_CISM,HUD_ADV,IPC
 SG_ AhbcRampingV_D_Rq : 57|2@0+ (1,0) [0|3] "SED"  GENERIC
 SG_ AhbHiBeam_D_Rq : 59|2@0+ (1,0) [0|3] "SED"  GENERIC
 SG_ DsmcMsgTxt_D_Dsply : 61|2@0+ (1,0) [0|3] "SED"  APIM_CDC,APIM_CIM,IPC
 SG_ AhbFeat_D_Stat : 63|2@0+ (1,0) [0|3] "SED"  APIM_CDC,APIM_CIM,IPC

BO_ 985 IPMA_Data2_HS3: 8 GWM
 SG_ IsaVLim_D_Rq : 7|8@0+ (1,0) [0|255] "SED" Vector__XXX
 SG_ SblmStopScnr_B_Stat : 8|1@0+ (1,0) [0|1] "SED" Vector__XXX
 SG_ SblmRndAbtScnr_B_Stat : 9|1@0+ (1,0) [0|1] "SED" Vector__XXX
 SG_ IaccVLimUnit_D_Rq : 11|2@0+ (1,0) [0|3] "SED" Vector__XXX
 SG_ DasAlrtInfo_D_Dsply : 13|2@0+ (1,0) [0|3] "SED"  APIM,APIM_CDC,APIM_CIM,APIM_CISM
 SG_ IsaVLimUnit_D_Rq : 15|2@0+ (1,0) [0|3] "SED" Vector__XXX
 SG_ IaccVLim_D_Rq : 23|8@0+ (1,0) [0|255] "SED" Vector__XXX
 SG_ LongCtrlBrk_D_Rq : 25|2@0+ (1,0) [0|3] "SED" Vector__XXX
 SG_ LongCtrlEnblDRq_No_Cnt : 29|4@0+ (1,0) [0|15] "unitless" Vector__XXX
 SG_ AdbDividedRoad_B_Stat : 30|1@0+ (1,0) [0|1] "SED" Vector__XXX
 SG_ SblmYieldScnr_B_Stat : 31|1@0+ (1,0) [0|1] "SED" Vector__XXX
 SG_ SblmPedCrossScnr_B_Stat : 33|1@0+ (1,0) [0|1] "SED" Vector__XXX
 SG_ LdwChime_B_Rq : 34|1@0+ (1,0) [0|1] "SED"  APIM_CDC,APIM_CIM,IPC
 SG_ AdbDrvSide_B_Stat : 35|1@0+ (1,0) [0|1] "SED" Vector__XXX
 SG_ LcwaMsgTxt_D_Stat : 37|2@0+ (1,0) [0|3] "SED"  APIM_CDC,APIM_CIM,IPC
 SG_ ClrExitAsst_D_Stat : 39|2@0+ (1,0) [0|3] "SED"  APIM,APIM_CDC,APIM_CIM,APIM_CISM,IPC
 SG_ LongCtrlEnbl_D_Rq : 42|3@0+ (1,0) [0|7] "SED" Vector__XXX
 SG_ TsrRegionTxt_D_Stat : 47|5@0+ (1,0) [0|31] "SED"  APIM_CDC,APIM_CIM,HUD_ADV,IPC
 SG_ PwSustnAdas_B_Rq : 48|1@0+ (1,0) [0|1] "SED" Vector__XXX
 SG_ ClrExitAsstMsgTxt_D_Rq : 52|4@0+ (1,0) [0|15] "SED"  APIM_CDC,APIM_CIM,IPC
 SG_ ClrExitAsstChime_D_Rq : 55|3@0+ (1,0) [0|7] "SED"  APIM_CDC,APIM_CIM,IPC
 SG_ LongCtrlEnblDRq_No_Cs : 63|8@0+ (1,0) [0|255] "unitless" Vector__XXX

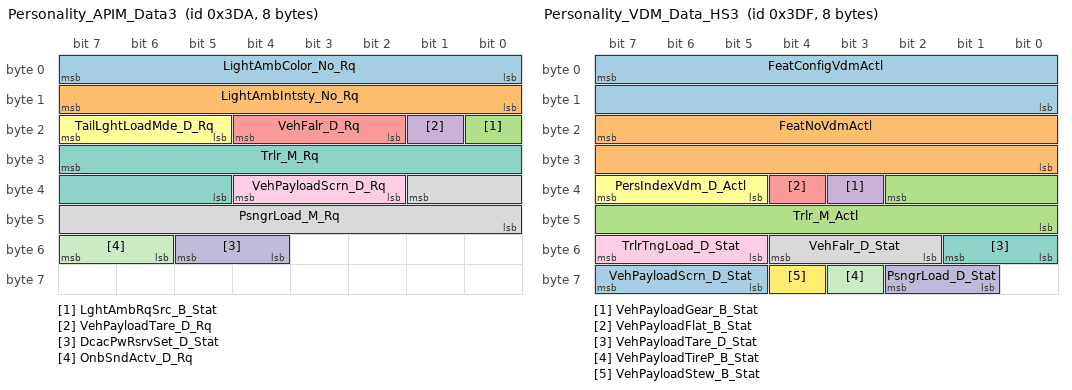
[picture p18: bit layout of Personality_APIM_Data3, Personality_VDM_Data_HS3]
BO_ 986 Personality_APIM_Data3: 8 APIM_CDC
 SG_ LightAmbColor_No_Rq : 7|8@0+ (1,0) [0|255] "Discrete"  GWM
 SG_ LightAmbIntsty_No_Rq : 15|8@0+ (1,0) [0|255] "unitless"  GWM
 SG_ LghtAmbRqSrc_B_Stat : 16|1@0+ (1,0) [0|1] "SED"  GWM,RACM_RCIM
 SG_ VehPayloadTare_D_Rq : 17|1@0+ (1,0) [0|1] "SED"  GWM
 SG_ VehFalr_D_Rq : 20|3@0+ (1,0) [0|7] "SED"  GWM
 SG_ TailLghtLoadMde_D_Rq : 23|3@0+ (1,0) [0|7] "SED"  GWM
 SG_ Trlr_M_Rq : 31|11@0+ (10,0) [0|20470] "kilogram"  GWM
 SG_ PsngrLoad_M_Rq : 33|10@0+ (1,0) [0|1023] "kilogram"  GWM
 SG_ VehPayloadScrn_D_Rq : 36|3@0+ (1,0) [0|7] "SED"  GWM
 SG_ DcacPwRsrvSet_D_Stat : 53|2@0+ (1,0) [0|3] "SED"  GWM
 SG_ OnbSndActv_D_Rq : 55|2@0+ (1,0) [0|3] "SED"  GWM

BO_ 989 Personality_HCM_Data_HS3: 8 GWM
 SG_ FeatConfigHcmActl : 7|16@0+ (1,0) [0|65535] "Undefined"  APIM,APIM_CDC,APIM_CIM,APIM_CISM,IPC
 SG_ FeatNoHcm_No_Actl : 23|16@0+ (1,0) [0|65535] "Number"  APIM,APIM_CDC,APIM_CIM,APIM_CISM,IPC
 SG_ AwlLamp_B_Rq : 38|1@0+ (1,0) [0|1] "SED"  APIM_CDC,IPC
 SG_ AwlEnbl_B_Stat : 39|1@0+ (1,0) [0|1] "SED"  APIM_CDC,IPC

BO_ 990 Personality_DDM_Data_HS3: 8 GWM
 SG_ FeatConfigDdmActl : 7|16@0+ (1,0) [0|65535] "Undefined"  APIM,APIM_CDC,APIM_CIM,APIM_CISM,IPC
 SG_ FeatNoDdm_No_Actl : 23|16@0+ (1,0) [0|65535] "Number"  APIM,APIM_CDC,APIM_CIM,APIM_CISM,IPC
 SG_ PersIndexDdm_D_Actl : 39|3@0+ (1,0) [0|7] "SED"  APIM,APIM_CDC,APIM_CIM,APIM_CISM,IPC

BO_ 991 Personality_VDM_Data_HS3: 8 GWM
 SG_ FeatConfigVdmActl : 7|16@0+ (1,0) [0|65535] "Undefined"  APIM,APIM_CDC,APIM_CIM,APIM_CISM,IPC
 SG_ FeatNoVdmActl : 23|16@0+ (1,0) [0|65535] "Number"  APIM,APIM_CDC,APIM_CIM,APIM_CISM,IPC
 SG_ Trlr_M_Actl : 34|11@0+ (10,0) [0|20470] "kilogram"  APIM,APIM_CDC,APIM_CIM,APIM_CISM
 SG_ VehPayloadGear_B_Stat : 35|1@0+ (1,0) [0|1] "SED"  APIM,APIM_CDC,APIM_CIM,APIM_CISM
 SG_ VehPayloadFlat_B_Stat : 36|1@0+ (1,0) [0|1] "SED"  APIM,APIM_CDC,APIM_CIM,APIM_CISM
 SG_ PersIndexVdm_D_Actl : 39|3@0+ (1,0) [0|7] "SED"  APIM,APIM_CDC,APIM_CIM,APIM_CISM,IPC
 SG_ VehPayloadTare_D_Stat : 49|2@0+ (1,0) [0|3] "SED"  APIM,APIM_CDC,APIM_CIM,APIM_CISM
 SG_ VehFalr_D_Stat : 52|3@0+ (1,0) [0|7] "SED"  APIM,APIM_CDC,APIM_CIM,APIM_CISM
 SG_ TrlrTngLoad_D_Stat : 55|3@0+ (1,0) [0|7] "SED" Vector__XXX
 SG_ PsngrLoad_D_Stat : 58|2@0+ (1,0) [0|3] "SED"  APIM,APIM_CDC
 SG_ VehPayloadTireP_B_Stat : 59|1@0+ (1,0) [0|1] "SED"  APIM,APIM_CDC,APIM_CIM,APIM_CISM
 SG_ VehPayloadStew_B_Stat : 60|1@0+ (1,0) [0|1] "SED"  APIM,APIM_CDC,APIM_CIM,APIM_CISM
 SG_ VehPayloadScrn_D_Stat : 63|3@0+ (1,0) [0|7] "SED"  APIM,APIM_CDC,APIM_CIM,APIM_CISM

BO_ 992 Personality_Data: 8 APIM_CDC
 SG_ MsgCntrFeatNoRq : 7|16@0+ (1,0) [0|65535] "Number"  GWM,HUD_ADV
 SG_ MsgCntrFeatConfigRq : 23|16@0+ (1,0) [0|65535] "unitless"  GWM,HUD_ADV
 SG_ MsgCntrDsplyOp_D_Rq : 36|3@0+ (1,0) [0|7] "SED"  GWM,HUD_ADV
 SG_ MsgCntrPersIndex_D_Rq : 39|3@0+ (1,0) [0|7] "SED"  GWM,HUD_ADV

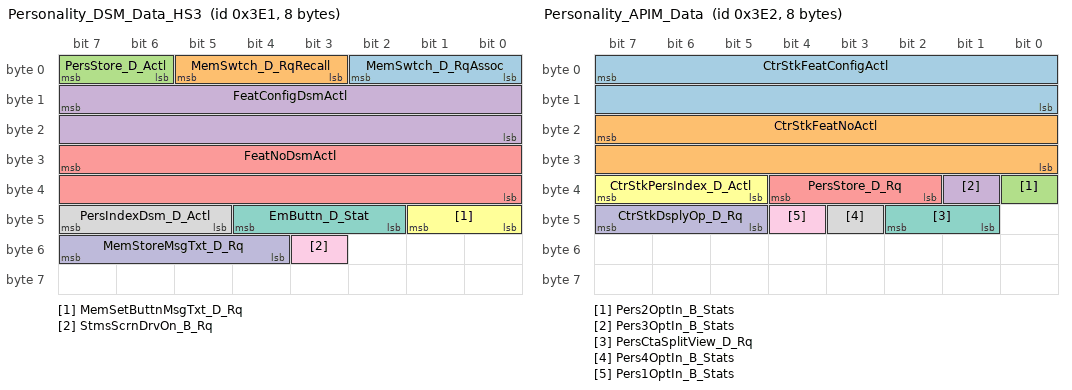
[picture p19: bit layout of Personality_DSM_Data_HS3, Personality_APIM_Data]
BO_ 993 Personality_DSM_Data_HS3: 8 GWM
 SG_ MemSwtch_D_RqAssoc : 2|3@0+ (1,0) [0|7] "SED" Vector__XXX
 SG_ MemSwtch_D_RqRecall : 5|3@0+ (1,0) [0|7] "SED" Vector__XXX
 SG_ PersStore_D_Actl : 7|2@0+ (1,0) [0|3] "SED"  APIM,APIM_CDC,APIM_CIM,APIM_CISM
 SG_ FeatConfigDsmActl : 15|16@0+ (1,0) [0|65535] "Undefined"  APIM,APIM_CDC,APIM_CIM,APIM_CISM,IPC
 SG_ FeatNoDsmActl : 31|16@0+ (1,0) [0|65535] "Number"  APIM,APIM_CDC,APIM_CIM,APIM_CISM,IPC
 SG_ MemSetButtnMsgTxt_D_Rq : 41|2@0+ (1,0) [0|3] "SED"  APIM_CDC,APIM_CIM,IPC
 SG_ EmButtn_D_Stat : 44|3@0+ (1,0) [0|7] "SED"  APIM,APIM_CDC,APIM_CIM,APIM_CISM
 SG_ PersIndexDsm_D_Actl : 47|3@0+ (1,0) [0|7] "SED"  APIM,APIM_CDC,APIM_CIM,APIM_CISM,IPC
 SG_ StmsScrnDrvOn_B_Rq : 51|1@0+ (1,0) [0|1] "SED"  APIM,APIM_CDC,APIM_CIM,APIM_CISM
 SG_ MemStoreMsgTxt_D_Rq : 55|4@0+ (1,0) [0|15] "SED"  APIM_CDC,APIM_CIM,IPC

BO_ 994 Personality_APIM_Data: 8 APIM_CDC
 SG_ CtrStkFeatConfigActl : 7|16@0+ (1,0) [0|65535] "Undefined"  GWM,IPC,RACM_RCIM
 SG_ CtrStkFeatNoActl : 23|16@0+ (1,0) [0|65535] "Undefined"  GWM,IPC,RACM_RCIM
 SG_ Pers2OptIn_B_Stats : 32|1@0+ (1,0) [0|1] "SED"  GWM
 SG_ Pers3OptIn_B_Stats : 33|1@0+ (1,0) [0|1] "SED"  GWM
 SG_ PersStore_D_Rq : 36|3@0+ (1,0) [0|7] "SED"  GWM
 SG_ CtrStkPersIndex_D_Actl : 39|3@0+ (1,0) [0|7] "SED"  ACM,DSP,GWM,IPC,RACM_RCIM
 SG_ PersCtaSplitView_D_Rq : 42|2@0+ (1,0) [0|3] "SED"  GWM
 SG_ Pers4OptIn_B_Stats : 43|1@0+ (1,0) [0|1] "SED"  GWM
 SG_ Pers1OptIn_B_Stats : 44|1@0+ (1,0) [0|1] "SED"  GWM
 SG_ CtrStkDsplyOp_D_Rq : 47|3@0+ (1,0) [0|7] "SED"  ACM,DSP,GWM,IPC,RACM_RCIM

BO_TX_BU_ 866 : APIM,APIM_CDC,APIM_CIM,APIM_CISM;
BO_TX_BU_ 867 : APIM_CDC,IPC;
BO_TX_BU_ 890 : ACM,APIM_CDC,APIM_CIM,APIM_CISM;
BO_TX_BU_ 903 : GWM,MRCMB_RDAPM_HS3;
BO_TX_BU_ 968 : APIM_CDC,APIM_CIM,APIM_CISM,IPC;
BO_TX_BU_ 986 : APIM,APIM_CDC,APIM_CIM,APIM_CISM;
BO_TX_BU_ 992 : APIM_CDC,APIM_CIM,APIM_CISM,IPC;
BO_TX_BU_ 994 : APIM,APIM_CDC,APIM_CIM,APIM_CISM;
CM_ BO_ 866 "APIM Tx";
CM_ BO_ 885 "NOTE: START BITS 8-11 MUST BE OPEN SPEC REQUIREMENT";
CM_ BO_ 932 "NOTE: START BITS 8-11 MUST BE OPEN SPEC REQUIREMENT";
CM_ BO_ 948 "$3B4 used by CGEA SPDJB";
CM_ BO_ 949 "For 2010MY and beyond, use for SCT (non-CGEA) and CGEA modules";
CM_ BO_ 967 "2008' programs, Tx by IC;  updated on 5/6/05";
CM_ BO_ 986 "APIM Tx";
BA_DEF_ BO_  "E2EDataId" INT 0 65535;
BA_DEF_ BO_  "E2EDataLength" INT 0 512;
BA_DEF_ BO_  "E2EProfile" STRING ;
BA_DEF_ BO_  "GenMsgRoutingTimeoutTime" INT 0 5000;
BA_DEF_ BO_  "MessageGateway" ENUM  "No","Yes";
BA_DEF_ BO_  "VFrameFormat" ENUM  "StandardCAN","ExtendedCAN","reserved","reserved","reserved","reserved","reserved","reserved","reserved","reserved","reserved","reserved","reserved","reserved","StandardCAN_FD","ExtendedCAN_FD";
BA_DEF_ SG_  "ECGUsedRxSignal" ENUM  "No","Yes";
BA_DEF_ SG_  "ECGUsedTxSignal" ENUM  "No","Yes";
BA_DEF_ SG_  "GenSigInactiveValue" INT 0 100000;
BA_DEF_ SG_  "GenSigSendType" ENUM  "Cyclic","OnWrite","vector_leerstring","OnChange","vector_leerstring","IfActive","vector_leerstring","NoSigSendType";
BA_DEF_ BO_  "NetworkInitialization" ENUM  "No","Yes";
BA_DEF_ SG_  "GenSigStartValue" HEX 0 268435455;
BA_DEF_ BO_  "GenMsgStartDelayTime" INT 0 10000;
BA_DEF_ SG_  "WakeupSignal" ENUM  "No","Yes";
BA_DEF_ BO_  "GenMsgNrOfRepetition" INT 0 100;
BA_DEF_ BO_  "GenMsgDelayTime" INT 0 1000;
BA_DEF_ BO_  "GenMsgCycleTime" INT 0 100000;
BA_DEF_ BO_  "GenMsgSendType" ENUM  "FixedPeriodic","Event","EnabledPeriodic","NotUsed","NotUsed","EventPeriodic","NotUsed","NotUsed","NoMsgSendType";
BA_DEF_ BO_  "FrameRouting" STRING ;
BA_DEF_ BO_  "TpTxIndex" INT 0 536870911;
BA_DEF_ BO_  "OvtpPushApplication" ENUM  "FALSE","TRUE";
BA_DEF_ BO_  "SCP_FreshnessValueLength" INT 0 512;
BA_DEF_ BO_  "SCP_FreshnessValueTxLength" INT 0 512;
BA_DEF_ BO_  "SCP_AuthInfoTxLength" INT 0 512;
BA_DEF_ BO_  "NmAsrMessage" ENUM  "No","Yes";
BA_DEF_ BO_  "DiagState" ENUM  "No","Yes";
BA_DEF_ BO_  "DiagRequest" ENUM  "No","Yes";
BA_DEF_ BO_  "DiagResponse" ENUM  "No","Yes";
BA_DEF_ BO_  "GenMsgILSupport" ENUM  "No","Yes";
BA_DEF_ SG_  "SystemSignalLongSymbol" STRING ;
BA_DEF_ BO_  "SystemMessageLongSymbol" STRING ;
BA_DEF_DEF_  "E2EDataId" 1;
BA_DEF_DEF_  "E2EDataLength" 0;
BA_DEF_DEF_  "E2EProfile" "";
BA_DEF_DEF_  "GenMsgRoutingTimeoutTime" 0;
BA_DEF_DEF_  "MessageGateway" "No";
BA_DEF_DEF_  "VFrameFormat" "StandardCAN";
BA_DEF_DEF_  "ECGUsedRxSignal" "No";
BA_DEF_DEF_  "ECGUsedTxSignal" "No";
BA_DEF_DEF_  "GenSigInactiveValue" 0;
BA_DEF_DEF_  "GenSigSendType" "NoSigSendType";
BA_DEF_DEF_  "NetworkInitialization" "Yes";
BA_DEF_DEF_  "GenSigStartValue" 0;
BA_DEF_DEF_  "GenMsgStartDelayTime" 0;
BA_DEF_DEF_  "WakeupSignal" "No";
BA_DEF_DEF_  "GenMsgNrOfRepetition" 1;
BA_DEF_DEF_  "GenMsgDelayTime" 20;
BA_DEF_DEF_  "GenMsgCycleTime" 0;
BA_DEF_DEF_  "GenMsgSendType" "NoMsgSendType";
BA_DEF_DEF_  "FrameRouting" "";
BA_DEF_DEF_  "TpTxIndex" 0;
BA_DEF_DEF_  "OvtpPushApplication" "FALSE";
BA_DEF_DEF_  "SCP_FreshnessValueLength" 64;
BA_DEF_DEF_  "SCP_FreshnessValueTxLength" 11;
BA_DEF_DEF_  "SCP_AuthInfoTxLength" 53;
BA_DEF_DEF_  "NmAsrMessage" "No";
BA_DEF_DEF_  "DiagState" "No";
BA_DEF_DEF_  "DiagRequest" "No";
BA_DEF_DEF_  "DiagResponse" "No";
BA_DEF_DEF_  "GenMsgILSupport" "Yes";
BA_DEF_DEF_  "SystemSignalLongSymbol" "";
BA_DEF_DEF_  "SystemMessageLongSymbol" "";
BA_ "GenMsgSendType" BO_ 866 5;
BA_ "GenMsgCycleTime" BO_ 866 1000;
BA_ "NetworkInitialization" BO_ 867 0;
BA_ "GenMsgSendType" BO_ 867 1;
BA_ "FrameRouting" BO_ 868 "MS1_CAN,0x364;";
BA_ "FrameRouting" BO_ 869 "FD1_CAN,0x365;";
BA_ "FrameRouting" BO_ 870 "FD1_CAN,0x366;";
BA_ "FrameRouting" BO_ 871 "FD1_CAN,0x367;";
BA_ "FrameRouting" BO_ 872 "FD1_CAN,0x368;";
BA_ "FrameRouting" BO_ 873 "FD1_CAN,0x369;";
BA_ "GenMsgSendType" BO_ 874 5;
BA_ "GenMsgCycleTime" BO_ 874 1000;
BA_ "FrameRouting" BO_ 875 "MS1_CAN,0x36B;";
BA_ "FrameRouting" BO_ 876 "MS1_CAN,0x36C;";
BA_ "FrameRouting" BO_ 877 "MS1_CAN,0x36D;";
BA_ "GenMsgSendType" BO_ 878 5;
BA_ "GenMsgCycleTime" BO_ 878 1000;
BA_ "FrameRouting" BO_ 883 "MS1_CAN,0x373;";
BA_ "FrameRouting" BO_ 884 "MS1_CAN,0x374;";
BA_ "GenMsgSendType" BO_ 885 0;
BA_ "GenMsgCycleTime" BO_ 885 200;
BA_ "GenMsgSendType" BO_ 890 5;
BA_ "GenMsgCycleTime" BO_ 890 1000;
BA_ "FrameRouting" BO_ 896 "FD1_CAN,0x380;";
BA_ "FrameRouting" BO_ 897 "FD1_CAN,0x381;";
BA_ "FrameRouting" BO_ 898 "HS2_CAN,0x382;FD1_CAN,0x382;";
BA_ "FrameRouting" BO_ 901 "FD2_CAN,0x385;";
BA_ "FrameRouting" BO_ 903 "FD2_CAN,0x387;";
BA_ "FrameRouting" BO_ 904 "FD2_CAN,0x388;FD2_CAN,0x388;";
BA_ "GenMsgSendType" BO_ 905 5;
BA_ "GenMsgCycleTime" BO_ 905 1000;
BA_ "GenMsgSendType" BO_ 908 5;
BA_ "GenMsgCycleTime" BO_ 908 1000;
BA_ "FrameRouting" BO_ 909 "FD1_CAN,0x38D;";
BA_ "FrameRouting" BO_ 912 "FD1_CAN,0x390;";
BA_ "FrameRouting" BO_ 919 "FD1_CAN,0x397;";
BA_ "FrameRouting" BO_ 925 "FD1_CAN,0x39D;";
BA_ "FrameRouting" BO_ 929 "FD1_CAN,0x3A1;FD3_CAN,0x3A1;";
BA_ "FrameRouting" BO_ 930 "FD1_CAN,0x3A2;FD3_CAN,0x3A2;";
BA_ "FrameRouting" BO_ 931 "FD1_CAN,0x3A3;";
BA_ "FrameRouting" BO_ 932 "FD1_CAN,0x3A4;";
BA_ "FrameRouting" BO_ 934 "FD1_CAN,0x3A6;FD3_CAN,0x3A6;";
BA_ "FrameRouting" BO_ 935 "FD1_CAN,0x3A7;FD3_CAN,0x3A7;";
BA_ "FrameRouting" BO_ 936 "FD3_CAN,0x3A8;";
BA_ "FrameRouting" BO_ 938 "FD1_CAN,0x3AA;FD3_CAN,0x3AA;";
BA_ "FrameRouting" BO_ 939 "FD1_CAN,0x3AB;FD3_CAN,0x3AB;";
BA_ "FrameRouting" BO_ 942 "FD1_CAN,0x3AE;FD3_CAN,0x3AE;";
BA_ "FrameRouting" BO_ 945 "FD1_CAN,0x3B1;";
BA_ "FrameRouting" BO_ 946 "FD1_CAN,0x3B3;";
BA_ "FrameRouting" BO_ 948 "FD1_CAN,0x3B4;";
BA_ "FrameRouting" BO_ 949 "FD1_CAN,0x3B5;";
BA_ "FrameRouting" BO_ 952 "FD1_CAN,0x3B8;";
BA_ "FrameRouting" BO_ 953 "FD1_CAN,0x3B9;";
BA_ "FrameRouting" BO_ 954 "FD1_CAN,0x3BA;";
BA_ "FrameRouting" BO_ 955 "FD1_CAN,0x3BB;";
BA_ "FrameRouting" BO_ 963 "FD1_CAN,0x3C3;";
BA_ "FrameRouting" BO_ 965 "FD1_CAN,0x3C5;";
BA_ "FrameRouting" BO_ 966 "FD1_CAN,0x3C6;";
BA_ "FrameRouting" BO_ 967 "FD1_CAN,0x3C7;";
BA_ "GenMsgSendType" BO_ 968 5;
BA_ "GenMsgCycleTime" BO_ 968 1000;
BA_ "FrameRouting" BO_ 969 "MS1_CAN,0x3C9;";
BA_ "FrameRouting" BO_ 972 "FD1_CAN,0x3CC;FD3_CAN,0x3CC;";
BA_ "FrameRouting" BO_ 973 "FD3_CAN,0x3CD;FD1_CAN,0x3CD;";
BA_ "FrameRouting" BO_ 974 "FD1_CAN,0x36E;";
BA_ "FrameRouting" BO_ 977 "MS1_CAN,0x3D1;";
BA_ "FrameRouting" BO_ 978 "MS1_CAN,0x3D2;";
BA_ "FrameRouting" BO_ 980 "HS2_CAN,0x2E4;";
BA_ "FrameRouting" BO_ 984 "FD1_CAN,0x3D8;FD3_CAN,0x3D8;";
BA_ "FrameRouting" BO_ 985 "FD1_CAN,0x3D9;FD3_CAN,0x3D9;";
BA_ "GenMsgSendType" BO_ 986 5;
BA_ "GenMsgCycleTime" BO_ 986 1000;
BA_ "FrameRouting" BO_ 989 "FD3_CAN,0x3DD;FD1_CAN,0x3DD;";
BA_ "FrameRouting" BO_ 990 "FD3_CAN,0x3DE;";
BA_ "FrameRouting" BO_ 991 "FD1_CAN,0x3DF;HS2_CAN,0x3DF;";
BA_ "GenMsgSendType" BO_ 992 5;
BA_ "GenMsgCycleTime" BO_ 992 1000;
BA_ "FrameRouting" BO_ 993 "FD3_CAN,0x3E1;MS1_CAN,0x3E1;";
BA_ "GenMsgSendType" BO_ 994 5;
BA_ "GenMsgCycleTime" BO_ 994 1000;
BA_ "GenSigSendType" SG_ 866 Voice_Blower_Limit 3;
BA_ "GenSigSendType" SG_ 866 Frt_Blower_Speed 3;
BA_ "GenSigSendType" SG_ 866 Drv_Set_Temp 3;
BA_ "GenSigSendType" SG_ 866 CabnScentMde_D_Rq 3;
BA_ "GenSigSendType" SG_ 866 Frt_Btn_Status_1st 3;
BA_ "GenSigSendType" SG_ 866 Frt_Btn_Status_2nd 3;
BA_ "GenSigSendType" SG_ 866 CabnScentChnl_D_Rq 3;
BA_ "GenSigSendType" SG_ 866 Rr_Btn_Status_1st 3;
BA_ "GenSigSendType" SG_ 866 ClimtRearView_D_Stat 3;
BA_ "GenSigSendType" SG_ 866 SnowPlowOn_B_Rq 3;
BA_ "GenSigSendType" SG_ 866 Rr_Btn_Status_2nd 3;
BA_ "GenSigSendType" SG_ 866 CabnScentIntns_D_Rq 3;
BA_ "GenSigSendType" SG_ 866 Psngr_Set_Temp 3;
BA_ "GenSigSendType" SG_ 866 Frt_Blower_Speed2 3;
BA_ "GenSigSendType" SG_ 866 CabnScentFanCalib_No_Rq 3;
BA_ "GenSigSendType" SG_ 867 EATC_LHS_Unit 1;
BA_ "GenSigSendType" SG_ 867 LHS_Temp_Disp_Digit3 1;
BA_ "GenSigStartValue" SG_ 867 Front_Blower_Ind 15;
BA_ "GenSigSendType" SG_ 867 Front_Blower_Ind 1;
BA_ "GenSigSendType" SG_ 867 LHS_Temp_Disp_Digit1 1;
BA_ "GenSigSendType" SG_ 867 LHS_Temp_Disp_Digit2 1;
BA_ "GenSigStartValue" SG_ 868 Rr_Blower_Indicate_Stat 15;
BA_ "GenSigStartValue" SG_ 870 EffRgenThres_Pc_Dsply 1023;
BA_ "GenSigStartValue" SG_ 870 RngPerChrgInst_L_Dsply 4093;
BA_ "GenSigStartValue" SG_ 872 DcdcIn_Pw_Mx 115;
BA_ "GenSigStartValue" SG_ 873 PwWhlLvl_Pc_Dsply 511;
BA_ "GenSigSendType" SG_ 874 E_Frt_Btn_Status_1st 3;
BA_ "GenSigSendType" SG_ 874 E_Frt_Btn_Status_2nd 3;
BA_ "GenSigSendType" SG_ 874 E_Rr_Btn_Status_1st 3;
BA_ "GenSigSendType" SG_ 874 E_Rr_Btn_Status_2nd 3;
BA_ "GenSigStartValue" SG_ 875 SeatAirAmb_P_Actl2 10000;
BA_ "GenSigStartValue" SG_ 875 SeatLmbrLoRl_Pc_Actl 127;
BA_ "GenSigStartValue" SG_ 875 SeatLmbrMidRl_Pc_Actl 127;
BA_ "GenSigStartValue" SG_ 875 SeatLmbrUpRl_Pc_Actl 127;
BA_ "GenSigStartValue" SG_ 876 SeatLmbrLoRr_Pc_Actl 127;
BA_ "GenSigStartValue" SG_ 876 SeatLmbrMidRr_Pc_Actl 127;
BA_ "GenSigStartValue" SG_ 876 SeatLmbrUpRr_Pc_Actl 127;
BA_ "GenSigStartValue" SG_ 877 Rr_Synch_Btn_Stt 2;
BA_ "GenSigStartValue" SG_ 877 Rr_Lock_Btn_Stt 2;
BA_ "GenSigStartValue" SG_ 877 Heat_Btn_Stt 2;
BA_ "GenSigStartValue" SG_ 877 AAR_Btn_Stt 2;
BA_ "GenSigStartValue" SG_ 877 Rr_RHS_Blower_Indicate 15;
BA_ "GenSigStartValue" SG_ 877 Rr_Third_Power_Btn_Stt 2;
BA_ "GenSigStartValue" SG_ 877 Rr_Third_Panel_Btn_Stt 2;
BA_ "GenSigStartValue" SG_ 877 Rr_Third_Floor_Btn_Stt 2;
BA_ "GenSigStartValue" SG_ 877 Rr_Third_Auto_Btn_Stt 2;
BA_ "GenSigStartValue" SG_ 877 CabnAmb_Te_ActlAft 255;
BA_ "GenSigStartValue" SG_ 878 ClimtRearTe2_An_Actl 511;
BA_ "GenSigSendType" SG_ 878 ClimtRearTe2_An_Actl 3;
BA_ "GenSigSendType" SG_ 878 ClimtRearBlwr2_D_Stat 3;
BA_ "GenSigSendType" SG_ 878 ClimtRearTe2_D_Stat 3;
BA_ "GenSigSendType" SG_ 878 ClimtRearFlr2_B_Stat 3;
BA_ "GenSigSendType" SG_ 878 ClimtRearPnlFlr2_B_Stat 3;
BA_ "GenSigSendType" SG_ 878 ClimtRearPnl2_B_Stat 3;
BA_ "GenSigStartValue" SG_ 878 ClimtRearBlwr2_An_Actl 511;
BA_ "GenSigSendType" SG_ 878 ClimtRearBlwr2_An_Actl 3;
BA_ "GenSigSendType" SG_ 878 ClimtRearPw2_B_Stat 3;
BA_ "GenSigSendType" SG_ 878 ClimtRearAuto2_B_Stat 3;
BA_ "GenSigSendType" SG_ 878 ClimtSeatRr2_D_Rq 3;
BA_ "GenSigSendType" SG_ 878 ClimtSeatRl2_D_Rq 3;
BA_ "GenSigSendType" SG_ 878 ClimtRrBlwr3rd2_D_Stat 3;
BA_ "GenSigSendType" SG_ 878 ClimtRrTe3rd2_D_Stat 3;
BA_ "GenSigSendType" SG_ 878 ClimtStCoolRr2_B_Stat 3;
BA_ "GenSigSendType" SG_ 878 ClimtStCoolRl2_B_Stat 3;
BA_ "GenSigSendType" SG_ 878 ClimtStHeatRr2_B_Stat 3;
BA_ "GenSigSendType" SG_ 878 ClimtStHeatRl2_B_Stat 3;
BA_ "GenSigSendType" SG_ 878 ClimtRearView2_D_Stat 3;
BA_ "GenSigSendType" SG_ 878 ClimtSyncRear2_B_Stat 3;
BA_ "GenSigSendType" SG_ 878 ClimtRrPw3rd2_B_Stat 3;
BA_ "GenSigSendType" SG_ 878 ClimtRrAuto3rd2_B_Stat 3;
BA_ "GenSigSendType" SG_ 878 ClimtRrFlr3rd2_B_Stat 3;
BA_ "GenSigSendType" SG_ 878 ClimtRrPnl3rd2_B_Stat 3;
BA_ "GenSigSendType" SG_ 878 ClimtRrPf3rd2_B_Stat 3;
BA_ "GenSigStartValue" SG_ 883 PmCabn02Mnte_Conc_Actl 510;
BA_ "GenSigStartValue" SG_ 883 PmCabn04Mnte_Conc_Actl 510;
BA_ "GenSigStartValue" SG_ 883 PmCabn06Mnte_Conc_Actl 510;
BA_ "GenSigStartValue" SG_ 883 PmCabn08Mnte_Conc_Actl 510;
BA_ "GenSigStartValue" SG_ 883 PmCabn10Mnte_Conc_Actl 510;
BA_ "GenSigStartValue" SG_ 884 PmCabn12Mnte_Conc_Actl 510;
BA_ "GenSigStartValue" SG_ 884 PmCabn14Mnte_Conc_Actl 510;
BA_ "GenSigStartValue" SG_ 884 PmCabn16Mnte_Conc_Actl 510;
BA_ "GenSigStartValue" SG_ 884 PmCabn18Mnte_Conc_Actl 510;
BA_ "GenSigStartValue" SG_ 884 PmCabn20Mnte_Conc_Actl 510;
BA_ "GenSigStartValue" SG_ 884 PmCabn_Conc_Actl 510;
BA_ "GenSigStartValue" SG_ 884 PmSnsCabn_D_Stat 5;
BA_ "ECGUsedTxSignal" SG_ 885 CanMsg375_No_Crc 1;
BA_ "ECGUsedTxSignal" SG_ 885 CanMsg375_No_Cnt 1;
BA_ "GenSigStartValue" SG_ 885 CanMsg375_UNUSED_4bit_1 15;
BA_ "ECGUsedTxSignal" SG_ 885 CanMsg375_UNUSED_4bit_1 1;
BA_ "ECGUsedTxSignal" SG_ 885 VehOn_D_RqCld 1;
BA_ "ECGUsedTxSignal" SG_ 885 VehOnRqstr_D_Stat 1;
BA_ "ECGUsedTxSignal" SG_ 885 VehStrtInhbt_D_RqCld 1;
BA_ "ECGUsedTxSignal" SG_ 885 VehStrtInhbt_D_Dsply 1;
BA_ "ECGUsedTxSignal" SG_ 885 OtaActv_D_Stat 1;
BA_ "ECGUsedTxSignal" SG_ 885 VehStrtInhbt_T_Dsply 1;
BA_ "GenSigStartValue" SG_ 885 CanMsg375_UNUSED_7bit_1 127;
BA_ "ECGUsedTxSignal" SG_ 885 CanMsg375_UNUSED_7bit_1 1;
BA_ "ECGUsedTxSignal" SG_ 885 BattULoChrg_D_RqOta 1;
BA_ "GenSigStartValue" SG_ 885 CanMsg375_UNUSED_8bit_1 255;
BA_ "ECGUsedTxSignal" SG_ 885 CanMsg375_UNUSED_8bit_1 1;
BA_ "GenSigSendType" SG_ 890 ActvNseMute_D_Rq 3;
BA_ "GenSigSendType" SG_ 890 ActvNse_B_Actv 3;
BA_ "GenSigSendType" SG_ 890 ActvNseAudio_D_Stat 3;
BA_ "GenSigStartValue" SG_ 896 Trip1BattULoE_Pc_Dsply 1022;
BA_ "GenSigStartValue" SG_ 896 Trip1ClimE_Pc_Dsply 1022;
BA_ "GenSigStartValue" SG_ 896 Trip1ExtFctrE_Pc_Dsply 1022;
BA_ "GenSigStartValue" SG_ 896 Trip1SumDrvE_Pc_Dsply 1022;
BA_ "GenSigStartValue" SG_ 896 VehElAvgTrip1_Eff_Dsply 126;
BA_ "GenSigStartValue" SG_ 896 BptDly_T_Actl 62;
BA_ "GenSigStartValue" SG_ 897 Trip2BattULoE_Pc_Dsply 1022;
BA_ "GenSigStartValue" SG_ 897 Trip2ClimE_Pc_Dsply 1022;
BA_ "GenSigStartValue" SG_ 897 Trip2ExtFctrE_Pc_Dsply 1022;
BA_ "GenSigStartValue" SG_ 897 Trip2SumDrvE_Pc_Dsply 1022;
BA_ "GenSigStartValue" SG_ 897 VehElAvgTrip2_Eff_Dsply 126;
BA_ "GenSigStartValue" SG_ 898 SecondRowBuckleDrvMid 3;
BA_ "GenSigStartValue" SG_ 898 FourthRowBucklePsngr 3;
BA_ "GenSigStartValue" SG_ 898 FourthRowBuckleMid 3;
BA_ "GenSigStartValue" SG_ 898 FourthRowBuckleDriver 3;
BA_ "GenSigStartValue" SG_ 898 Row2PsngrPrsnc_D_Actl 3;
BA_ "GenSigStartValue" SG_ 898 Row2MidPrsnc_D_Actl 3;
BA_ "GenSigStartValue" SG_ 898 Row2DrvPrsnc_D_Actl 3;
BA_ "GenSigStartValue" SG_ 898 SecondRowBcklPsngrMid 3;
BA_ "GenSigStartValue" SG_ 898 Row3PsngrPrsnc_D_Actl 3;
BA_ "GenSigStartValue" SG_ 898 Row3MidPrsnc_D_Actl 3;
BA_ "GenSigStartValue" SG_ 898 Row3DrvPrsnc_D_Actl 3;
BA_ "GenSigStartValue" SG_ 898 VedsPrmDirOfF_An_Ltchd 90;
BA_ "GenSigStartValue" SG_ 898 VedsRoll_An_Ltchd 4096;
BA_ "GenSigSendType" SG_ 904 AplPrimForUnload_D_Rq 3;
BA_ "GenSigSendType" SG_ 904 AplPrimForLoad_D_Rq 3;
BA_ "GenSigSendType" SG_ 904 AplReas_D_Stat 3;
BA_ "GenSigSendType" SG_ 904 AplHelpButtn_D_Stat 3;
BA_ "GenSigSendType" SG_ 904 AprForNextOrder_D_Rq 3;
BA_ "GenSigSendType" SG_ 905 AprPrimForUnload_D_Rq 3;
BA_ "GenSigSendType" SG_ 905 AprPrimForLoad_D_Rq 3;
BA_ "GenSigSendType" SG_ 905 AprReas_D_Stat 3;
BA_ "GenSigSendType" SG_ 905 AprHelpButtn_D_Stat 3;
BA_ "GenSigSendType" SG_ 905 AplForNextOrder_D_Rq 3;
BA_ "GenSigSendType" SG_ 908 ApnlLogoId_No_Actl 3;
BA_ "ECGUsedTxSignal" SG_ 908 ApnlLogoId_No_Actl 1;
BA_ "WakeupSignal" SG_ 909 immoMsgTxt_D_Rq 1;
BA_ "WakeupSignal" SG_ 909 PrsnlDevcChrgEnbl_B_Rq 1;
BA_ "GenSigStartValue" SG_ 909 HeadLghtHiPrmsn_D_Stat 3;
BA_ "WakeupSignal" SG_ 909 HazrdLght_B_Stat 1;
BA_ "WakeupSignal" SG_ 909 IgnPsswrdDsply_B_Rq 1;
BA_ "WakeupSignal" SG_ 909 ElPwPoint_D_Rq 1;
BA_ "GenSigStartValue" SG_ 909 WiprFront_D_Stat2 15;
BA_ "GenSigStartValue" SG_ 912 OraZone2_D_Stat 1;
BA_ "ECGUsedRxSignal" SG_ 912 OraZone2_D_Stat 1;
BA_ "GenSigStartValue" SG_ 912 OraZone4_D_Stat 1;
BA_ "ECGUsedRxSignal" SG_ 912 OraZone4_D_Stat 1;
BA_ "GenSigStartValue" SG_ 912 OraZone5_D_Stat 1;
BA_ "ECGUsedRxSignal" SG_ 912 OraZone5_D_Stat 1;
BA_ "GenSigStartValue" SG_ 912 OraZone6_D_Stat 1;
BA_ "ECGUsedRxSignal" SG_ 912 OraZone6_D_Stat 1;
BA_ "GenSigStartValue" SG_ 919 Row2PsngrPrsnc_D_Actl2 3;
BA_ "GenSigStartValue" SG_ 919 Row2DrvPrsnc_D_Actl2 3;
BA_ "GenSigStartValue" SG_ 925 TripBattULoE_Pc_Dsply 1022;
BA_ "GenSigStartValue" SG_ 925 TripClimE_Pc_Dsply 1022;
BA_ "GenSigStartValue" SG_ 925 TripExtFctrE_Pc_Dsply 1022;
BA_ "GenSigStartValue" SG_ 925 TripSumDrvE_Pc_Dsply 1022;
BA_ "GenSigStartValue" SG_ 925 VehElEffTrip_No_Dsply 126;
BA_ "GenSigStartValue" SG_ 929 BalrLeft_D_Stat 2;
BA_ "GenSigStartValue" SG_ 929 BalrMdeLeft_D_Stat 1;
BA_ "GenSigStartValue" SG_ 930 BalrRight_D_Stat 2;
BA_ "GenSigStartValue" SG_ 930 BalrMdeRight_D_Stat 1;
BA_ "GenSigStartValue" SG_ 931 CrnkInhbt_B_Stat 1;
BA_ "WakeupSignal" SG_ 932 ChildLck_D_Dsply 1;
BA_ "GenSigStartValue" SG_ 932 ChildLck_D_Dsply 1;
BA_ "GenSigStartValue" SG_ 932 CanMsg3A4_UNUSED_7bit_1 127;
BA_ "GenSigStartValue" SG_ 932 CanMsg3A4_UNUSED_8bit_1 255;
BA_ "GenSigStartValue" SG_ 932 CanMsg3A4_UNUSED_8bit_2 255;
BA_ "GenSigStartValue" SG_ 932 CanMsg3A4_UNUSED_8bit_3 255;
BA_ "GenSigStartValue" SG_ 932 CanMsg3A4_UNUSED_8bit_4 255;
BA_ "GenSigStartValue" SG_ 934 SodWarnLeft_Prd_Rq 14;
BA_ "GenSigStartValue" SG_ 934 SodLeft_D_Stat 2;
BA_ "GenSigStartValue" SG_ 934 Side_Detect_L_Illum 100;
BA_ "GenSigStartValue" SG_ 935 SodWarnRight_Prd_Rq 14;
BA_ "GenSigStartValue" SG_ 935 SodRight_D_Stat 2;
BA_ "GenSigStartValue" SG_ 935 Side_Detect_R_Illum 100;
BA_ "GenSigStartValue" SG_ 938 ApaActvSd_D_Actl 1;
BA_ "GenSigStartValue" SG_ 939 ApaBrk_A_Rq 255;
BA_ "GenSigStartValue" SG_ 942 ApaOffOptnSel_B_Avail 1;
BA_ "WakeupSignal" SG_ 945 PrkLckCtlMsgTxt_D2_Rq 1;
BA_ "WakeupSignal" SG_ 945 KeyPadCodeDgt2_D_Dsply 1;
BA_ "WakeupSignal" SG_ 945 KeyPadCodeDgt1_D_Dsply 1;
BA_ "WakeupSignal" SG_ 945 KeyPadCodeDgt4_D_Dsply 1;
BA_ "WakeupSignal" SG_ 945 KeyPadCodeDgt3_D_Dsply 1;
BA_ "WakeupSignal" SG_ 945 KeyPadCodeDgt6_D_Dsply 1;
BA_ "WakeupSignal" SG_ 945 KeyPadCodeDgt5_D_Dsply 1;
BA_ "WakeupSignal" SG_ 945 PwLoApim_T_Actl 1;
BA_ "WakeupSignal" SG_ 945 DelvrAsstMsgTxt_D_Rq 1;
BA_ "WakeupSignal" SG_ 946 DrStatTgate_B_Actl 1;
BA_ "WakeupSignal" SG_ 946 Parklamp_Status 1;
BA_ "GenSigStartValue" SG_ 946 Parklamp_Status 1;
BA_ "WakeupSignal" SG_ 946 Ignition_Status 1;
BA_ "WakeupSignal" SG_ 946 TurnLghtLeft_D_Rq 1;
BA_ "WakeupSignal" SG_ 946 Key_In_Ignition_Stat 1;
BA_ "WakeupSignal" SG_ 946 Remote_Start_Status 1;
BA_ "WakeupSignal" SG_ 946 Day_Night_Status 1;
BA_ "WakeupSignal" SG_ 946 DimmingLvlEvnt_No_Actl 1;
BA_ "WakeupSignal" SG_ 946 Backlit_LED_Status 1;
BA_ "WakeupSignal" SG_ 946 Dimming_Lvl 1;
BA_ "GenSigStartValue" SG_ 946 Dimming_Lvl 12;
BA_ "WakeupSignal" SG_ 946 CrashEvnt_D_Stat 1;
BA_ "GenSigStartValue" SG_ 946 CrashEvnt_D_Stat 3;
BA_ "GenSigStartValue" SG_ 946 IgnKeyType_D_Actl 14;
BA_ "WakeupSignal" SG_ 946 Litval 1;
BA_ "WakeupSignal" SG_ 946 DrStatRl_B_Actl 1;
BA_ "WakeupSignal" SG_ 946 DrStatRr_B_Actl 1;
BA_ "WakeupSignal" SG_ 946 PrkBrkActv_B_Actl 1;
BA_ "WakeupSignal" SG_ 946 Delay_Accy 1;
BA_ "WakeupSignal" SG_ 946 DrStatInnrTgate_B_Actl 1;
BA_ "WakeupSignal" SG_ 946 DrStatHood_B_Actl 1;
BA_ "WakeupSignal" SG_ 946 DrStatPsngr_B_Actl 1;
BA_ "WakeupSignal" SG_ 946 DrStatDrv_B_Actl 1;
BA_ "WakeupSignal" SG_ 946 TurnLghtRight_D_Rq 1;
BA_ "GenSigStartValue" SG_ 948 Tire_Press_Placrd_Frnt 255;
BA_ "GenSigStartValue" SG_ 948 Tire_Press_Placrd_Rear 255;
BA_ "GenSigStartValue" SG_ 949 Tire_Press_LF_Data 65533;
BA_ "GenSigStartValue" SG_ 949 Tire_Press_RF_Data 65533;
BA_ "GenSigStartValue" SG_ 949 Tire_Press_RR_ORR_Data 65533;
BA_ "GenSigStartValue" SG_ 949 Tire_Press_LR_OLR_Data 65533;
BA_ "GenSigStartValue" SG_ 952 Tire_Press_ILR_Data 65533;
BA_ "GenSigStartValue" SG_ 952 Tire_Press_IRR_Data 65533;
BA_ "GenSigStartValue" SG_ 953 WakeAlarm3_D_Stat 3;
BA_ "GenSigStartValue" SG_ 953 WakeAlarm2_D_Stat 3;
BA_ "GenSigStartValue" SG_ 953 WakeAlarm1_D_Stat 3;
BA_ "GenSigStartValue" SG_ 953 WakeAlarm0_D_Stat 3;
BA_ "GenSigStartValue" SG_ 953 BattRgenLoSoc_Pc_LimLo 30;
BA_ "GenSigStartValue" SG_ 953 OraZone1_D_Stat 1;
BA_ "WakeupSignal" SG_ 954 ExtLght_D_Falt 1;
BA_ "WakeupSignal" SG_ 954 ExtLghtLeft_D_Stat 1;
BA_ "WakeupSignal" SG_ 954 ExtLghtFront_D_Stat 1;
BA_ "WakeupSignal" SG_ 954 ExtLghtAlrt_B_Rq 1;
BA_ "WakeupSignal" SG_ 954 PudSptLghtRight_D_Rq 1;
BA_ "WakeupSignal" SG_ 954 PudSptLghtLeft_D_Rq 1;
BA_ "WakeupSignal" SG_ 954 ExtLghtRight_D_Stat 1;
BA_ "WakeupSignal" SG_ 954 ExtLghtRear_D_Stat 1;
BA_ "WakeupSignal" SG_ 954 TrukBedLght_B_Stat 1;
BA_ "WakeupSignal" SG_ 954 TrlrHitchLamp_D_Stat 1;
BA_ "WakeupSignal" SG_ 954 VehWlcmFrwlMde_D_Stat 1;
BA_ "WakeupSignal" SG_ 954 VehWlcmFrwl_D_Stat 1;
BA_ "WakeupSignal" SG_ 954 LghtAmbDrvMde_B_Stat 1;
BA_ "WakeupSignal" SG_ 954 PwRnngBoardPoll_D_Stat 1;
BA_ "WakeupSignal" SG_ 954 ExtLghtFront_D_RqBody 1;
BA_ "GenSigStartValue" SG_ 954 ExtLghtFront_D_RqBody 1;
BA_ "GenSigStartValue" SG_ 955 Tire_Temp_ILR_Data 253;
BA_ "GenSigStartValue" SG_ 955 Tire_Temp_IRR_Data 253;
BA_ "GenSigStartValue" SG_ 955 Tire_Temp_LF_Data 253;
BA_ "GenSigStartValue" SG_ 955 Tire_Temp_OLR_Data 253;
BA_ "GenSigStartValue" SG_ 955 Tire_Temp_ORR_Data 253;
BA_ "GenSigStartValue" SG_ 955 Tire_Temp_RF_Data 253;
BA_ "WakeupSignal" SG_ 963 PerimeterAlarmChimeRq 1;
BA_ "WakeupSignal" SG_ 963 HeadLghtHiOn_B_Stat 1;
BA_ "GenSigStartValue" SG_ 963 HeadLampLoFrOn_B_Stat 1;
BA_ "GenSigStartValue" SG_ 963 HeadLampLoFlOn_B_Stat 1;
BA_ "GenSigStartValue" SG_ 963 HeadLampLoActv_B_Stat 1;
BA_ "WakeupSignal" SG_ 963 Courtesy_BSave_Stat 1;
BA_ "GenSigStartValue" SG_ 963 Courtesy_BSave_Stat 1;
BA_ "WakeupSignal" SG_ 963 StopLghtOn_B_Stat 1;
BA_ "WakeupSignal" SG_ 963 PudLamp_D_Rq 1;
BA_ "WakeupSignal" SG_ 963 PrkLght_D_Stat 1;
BA_ "WakeupSignal" SG_ 963 HeadLghtSwtch_D_Stat 1;
BA_ "GenSigStartValue" SG_ 963 HeadLghtSwtch_D_Stat 2;
BA_ "WakeupSignal" SG_ 963 Perimeter_Alarm_Status 1;
BA_ "WakeupSignal" SG_ 963 WndwGlbl_D_Cmd 1;
BA_ "WakeupSignal" SG_ 963 KeyInIgnWarn_B_Cmd 1;
BA_ "WakeupSignal" SG_ 963 HomeSafeLtChime_B_Rq 1;
BA_ "WakeupSignal" SG_ 963 Headlamp_On_Wrning_Cmd 1;
BA_ "WakeupSignal" SG_ 963 ImpactEvntFdbck_D_Stat 1;
BA_ "WakeupSignal" SG_ 965 TrunkFrontRolCd_No_Locl 1;
BA_ "WakeupSignal" SG_ 965 TrnkFrontEmgcy_D_Stat 1;
BA_ "GenSigStartValue" SG_ 965 TrnkFrontEmgcy_D_Stat 3;
BA_ "WakeupSignal" SG_ 965 PtWakeupActv4_B_Rq 1;
BA_ "WakeupSignal" SG_ 965 TrunkFrontOpen_D_Stat 1;
BA_ "GenSigStartValue" SG_ 965 TrunkFrontOpen_D_Stat 2;
BA_ "WakeupSignal" SG_ 966 TrunkFrontRolCd_No_Actl 1;
BA_ "WakeupSignal" SG_ 966 VehHorn_D_RqAlrt 1;
BA_ "WakeupSignal" SG_ 966 TrunkFrontOpen_No_Actl 1;
BA_ "WakeupSignal" SG_ 966 ScrtyHornActv_B_Rq 1;
BA_ "WakeupSignal" SG_ 966 VehHorn_D_Rq 1;
BA_ "GenSigStartValue" SG_ 967 CamraViewSplit_D_Actl 2;
BA_ "GenSigSendType" SG_ 968 Dimming_Level_Cmd 3;
BA_ "GenSigSendType" SG_ 968 BlendedColorBlue_Cmd 3;
BA_ "GenSigStartValue" SG_ 968 BlendedColor_Cmd 2;
BA_ "GenSigSendType" SG_ 968 BlendedColor_Cmd 3;
BA_ "GenSigSendType" SG_ 968 BlendedColorRed_Cmd 3;
BA_ "GenSigSendType" SG_ 968 BlendedColorGreen_Cmd 3;
BA_ "GenSigSendType" SG_ 968 BrkDrvMde_D_Rq 3;
BA_ "GenSigStartValue" SG_ 968 Current_Color_Cmd 8;
BA_ "GenSigSendType" SG_ 968 Current_Color_Cmd 3;
BA_ "GenSigStartValue" SG_ 968 BlendedColor_CmdGage 2;
BA_ "GenSigSendType" SG_ 968 BlendedColor_CmdGage 3;
BA_ "GenSigStartValue" SG_ 968 SlMde_D_Rq 2;
BA_ "GenSigSendType" SG_ 968 SlMde_D_Rq 3;
BA_ "GenSigStartValue" SG_ 968 IsaOffst_D_Rq 14;
BA_ "GenSigSendType" SG_ 968 IsaOffst_D_Rq 3;
BA_ "GenSigSendType" SG_ 968 BlendColorGrn_CmdGage 3;
BA_ "GenSigSendType" SG_ 968 BlendColorBlue_CmdGage 3;
BA_ "GenSigStartValue" SG_ 968 CurrentColor_CmdGage 8;
BA_ "GenSigSendType" SG_ 968 CurrentColor_CmdGage 3;
BA_ "GenSigSendType" SG_ 968 BlendColorRed_CmdGage 3;
BA_ "GenSigSendType" SG_ 968 LnchCtl_N_Rq 3;
BA_ "GenSigSendType" SG_ 968 RvltnMatchAllw_D_Rq 3;
BA_ "GenSigSendType" SG_ 968 SuspDrvMde_D_Rq 3;
BA_ "GenSigSendType" SG_ 968 LnchCtl_D_Rq 3;
BA_ "WakeupSignal" SG_ 969 TurnLampRrOut_B_Stat 1;
BA_ "WakeupSignal" SG_ 969 TurnLampRlOut_B_Stat 1;
BA_ "GenSigStartValue" SG_ 969 BlendedColor_Stat 2;
BA_ "GenSigStartValue" SG_ 969 Current_Color_Stat 8;
BA_ "GenSigStartValue" SG_ 972 TjaHandsOnCnfdnc_B_Est 1;
BA_ "GenSigStartValue" SG_ 972 LaHandsOff_B_Actl 1;
BA_ "GenSigStartValue" SG_ 973 TsrOswWarnMsgTxt_D_Rq 1;
BA_ "GenSigStartValue" SG_ 973 TsrMsgTxt_D_Rq 1;
BA_ "GenSigStartValue" SG_ 973 TsrOvtkMsgTxt_D_Rq 1;
BA_ "GenSigStartValue" SG_ 973 TsrVLim1MsgTxt_D_Rq 255;
BA_ "GenSigStartValue" SG_ 973 TsrVLim2MsgTxt_D_Rq 255;
BA_ "GenSigStartValue" SG_ 973 TsrVlUnitMsgTxt_D_Rq 2;
BA_ "GenSigStartValue" SG_ 973 TsrVl1RstrcMsgTxt2_D_Rq 1;
BA_ "GenSigStartValue" SG_ 973 TsrVl2RstrcMsgTxt2_D_Rq 1;
BA_ "GenSigStartValue" SG_ 974 DcacElPw_D_Stat 1;
BA_ "WakeupSignal" SG_ 977 CnvtTopPos_Up_Stat 1;
BA_ "WakeupSignal" SG_ 977 CnvtTopPos_Dn_Stat 1;
BA_ "WakeupSignal" SG_ 977 CnvtTopMsgTxt_D_Rq 1;
BA_ "GenSigStartValue" SG_ 978 CnvtTopPos_D_Stat 7;
BA_ "GenSigStartValue" SG_ 980 BattDcChrg_U_Actl 1022;
BA_ "WakeupSignal" SG_ 980 PtWakeupActv2_B_Rq 1;
BA_ "GenSigStartValue" SG_ 984 PersIndexIpma_D_Actl 4;
BA_ "GenSigStartValue" SG_ 985 IsaVLim_D_Rq 254;
BA_ "GenSigStartValue" SG_ 985 IaccVLimUnit_D_Rq 3;
BA_ "GenSigStartValue" SG_ 985 IaccVLim_D_Rq 254;
BA_ "GenSigSendType" SG_ 986 LightAmbColor_No_Rq 3;
BA_ "GenSigSendType" SG_ 986 LightAmbIntsty_No_Rq 3;
BA_ "GenSigSendType" SG_ 986 LghtAmbRqSrc_B_Stat 3;
BA_ "GenSigSendType" SG_ 986 VehPayloadTare_D_Rq 3;
BA_ "GenSigSendType" SG_ 986 VehFalr_D_Rq 3;
BA_ "GenSigSendType" SG_ 986 TailLghtLoadMde_D_Rq 3;
BA_ "GenSigStartValue" SG_ 986 Trlr_M_Rq 2046;
BA_ "GenSigSendType" SG_ 986 Trlr_M_Rq 3;
BA_ "GenSigStartValue" SG_ 986 PsngrLoad_M_Rq 1022;
BA_ "GenSigSendType" SG_ 986 VehPayloadScrn_D_Rq 3;
BA_ "GenSigSendType" SG_ 986 DcacPwRsrvSet_D_Stat 3;
BA_ "ECGUsedRxSignal" SG_ 986 DcacPwRsrvSet_D_Stat 1;
BA_ "GenSigSendType" SG_ 986 OnbSndActv_D_Rq 3;
BA_ "GenSigStartValue" SG_ 990 PersIndexDdm_D_Actl 4;
BA_ "GenSigStartValue" SG_ 991 Trlr_M_Actl 2046;
BA_ "GenSigStartValue" SG_ 991 PersIndexVdm_D_Actl 4;
BA_ "GenSigStartValue" SG_ 991 TrlrTngLoad_D_Stat 6;
BA_ "GenSigSendType" SG_ 992 MsgCntrFeatNoRq 3;
BA_ "GenSigSendType" SG_ 992 MsgCntrFeatConfigRq 3;
BA_ "GenSigSendType" SG_ 992 MsgCntrDsplyOp_D_Rq 3;
BA_ "GenSigStartValue" SG_ 992 MsgCntrPersIndex_D_Rq 4;
BA_ "GenSigSendType" SG_ 992 MsgCntrPersIndex_D_Rq 3;
BA_ "WakeupSignal" SG_ 993 MemSwtch_D_RqAssoc 1;
BA_ "WakeupSignal" SG_ 993 MemSwtch_D_RqRecall 1;
BA_ "GenSigStartValue" SG_ 993 PersIndexDsm_D_Actl 4;
BA_ "GenSigSendType" SG_ 994 CtrStkFeatConfigActl 3;
BA_ "GenSigSendType" SG_ 994 CtrStkFeatNoActl 3;
BA_ "WakeupSignal" SG_ 994 Pers2OptIn_B_Stats 1;
BA_ "GenSigSendType" SG_ 994 Pers2OptIn_B_Stats 3;
BA_ "WakeupSignal" SG_ 994 Pers3OptIn_B_Stats 1;
BA_ "GenSigSendType" SG_ 994 Pers3OptIn_B_Stats 3;
BA_ "GenSigSendType" SG_ 994 PersStore_D_Rq 3;
BA_ "GenSigStartValue" SG_ 994 CtrStkPersIndex_D_Actl 4;
BA_ "GenSigSendType" SG_ 994 CtrStkPersIndex_D_Actl 3;
BA_ "GenSigSendType" SG_ 994 PersCtaSplitView_D_Rq 3;
BA_ "WakeupSignal" SG_ 994 Pers4OptIn_B_Stats 1;
BA_ "GenSigSendType" SG_ 994 Pers4OptIn_B_Stats 3;
BA_ "WakeupSignal" SG_ 994 Pers1OptIn_B_Stats 1;
BA_ "GenSigSendType" SG_ 994 Pers1OptIn_B_Stats 3;
BA_ "GenSigSendType" SG_ 994 CtrStkDsplyOp_D_Rq 3;
VAL_ 866 Voice_Blower_Limit 0 "NoRequest" 1 "Request" ;
VAL_ 866 Frt_Blower_Speed 0 "No_Request" 1 "Min_Blower" 2 "Max_Blower" 3 "NotUsed" ;
VAL_ 866 Drv_Set_Temp 0 "No_Request" 1 "LO" 2 "15_5" 3 "16_0" 4 "16_5" 5 "17_0" 6 "17_5" 7 "18_0" 8 "18_5" 9 "19_0" 10 "19_5" 11 "20_0" 12 "20_5" 13 "21_0" 14 "21_5" 15 "22_0" 16 "22_5" 17 "23_0" 18 "23_5" 19 "24_0" 20 "24_5" 21 "25_0" 22 "25_5" 23 "26_0" 24 "26_5" 25 "27_0" 26 "27_5" 27 "28_0" 28 "28_5" 29 "29_0" 30 "29_5" 31 "HI" ;
VAL_ 866 CabnScentMde_D_Rq 0 "NoneOrNoneYet" 1 "StartOrContinueScent" 2 "StopScent" 3 "MasterError" ;
VAL_ 866 Frt_Btn_Status_1st 0 "None_Pressed" 1 "Panel_Pressed" 2 "Panel_Floor_Pressed" 3 "Floor_Pressed" 4 "Floor_Ws_Pressed" 5 "AC_Pressed" 6 "Dual_Pressed" 7 "LHS_Temp_Inc_Pressed" 8 "LHS_Temp_Dec_Pressed" 9 "RHS_Temp_Inc_Pressed" 10 "RHS_Temp_Dec_Pressed" 11 "Blwr_Inc_Pressed" 12 "Blwr_Dec_Pressed" 13 "AUTO_Pressed" 14 "Max_AC_Pressed" 15 "Recirc_Pressed" 16 "Outside_Pressed" 17 "Auto_Recirc_Pressed" 18 "Htd_Frt_Wsh_Pressed" 19 "Windscreen_Pressed" 20 "Pnl_Ws_Pressed" 21 "Pnl_Flr_Ws_Pressed" 22 "Rear_Defrost_Pressed" 23 "Front_Power_Pressed" 24 "My_Temp_Pressed" 25 "Max_Defrost_Pressed" 26 "LHS_Htd_Seat_Pressed" 27 "RHS_Htd_Seat_Pressed" 28 "LHS_Cld_Seat_Pressed" 29 "RHS_Cld_Seat_Pressed" 30 "Htg_Strg_Whl_Pressed" 31 "Defrost_Pressed" 32 "FrontMnu_Pressed" 33 "RearMnu_Pressed" 34 "Heat_Pressed" 35 "AAR_Pressed" 36 "MdeMnu_Pressed" 37 "DrvrFcsdMde_Pressed" 38 "LHS_Seat_Off_Pressed" 39 "LHS_Htd_Seat1_Pressed" 40 "LHS_Htd_Seat2_Pressed" 41 "LHS_Htd_Seat3_Pressed" 42 "LHS_Auto_Seat_Pressed" 43 "RHS_Seat_Off_Pressed" 44 "RHS_Htd_Seat1_Pressed" 45 "RHS_Htd_Seat2_Pressed" 46 "RHS_Htd_Seat3_Pressed" 47 "RHS_Auto_Seat_Pressed" 48 "LHS_Cld_Seat1_Pressed" 49 "LHS_Cld_Seat2_Pressed" 50 "LHS_Cld_Seat3_Pressed" 51 "RHS_Cld_Seat1_Pressed" 52 "RHS_Cld_Seat2_Pressed" 53 "RHS_Cld_Seat3_Pressed" 54 "AUTO_Lo_Pressed" 55 "AUTO_Med_Pressed" 56 "AUTO_Hi_Pressed" 57 "AUTO_Inc_Pressed" 58 "AUTO_Dec_Pressed" 59 "NotUsed_6" 60 "NotUsed_7" 61 "NotUsed_8" 62 "NotUsed_9" 63 "NotUsed_10" ;
VAL_ 866 Frt_Btn_Status_2nd 0 "None_Pressed" 1 "Panel_Pressed" 2 "Panel_Floor_Pressed" 3 "Floor_Pressed" 4 "Floor_Ws_Pressed" 5 "AC_Pressed" 6 "Dual_Pressed" 7 "LHS_Temp_Inc_Pressed" 8 "LHS_Temp_Dec_Pressed" 9 "RHS_Temp_Inc_Pressed" 10 "RHS_Temp_Dec_Pressed" 11 "Blwr_Inc_Pressed" 12 "Blwr_Dec_Pressed" 13 "AUTO_Pressed" 14 "Max_AC_Pressed" 15 "Recirc_Pressed" 16 "Outside_Pressed" 17 "Auto_Recirc_Pressed" 18 "Htd_Frt_Wsh_Pressed" 19 "Windscreen_Pressed" 20 "Pnl_Ws_Pressed" 21 "Pnl_Flr_Ws_Pressed" 22 "Rear_Defrost_Pressed" 23 "Front_Power_Pressed" 24 "My_Temp_Pressed" 25 "Max_Defrost_Pressed" 26 "LHS_Htd_Seat_Pressed" 27 "RHS_Htd_Seat_Pressed" 28 "LHS_Cld_Seat_Pressed" 29 "RHS_Cld_Seat_Pressed" 30 "Htg_Strg_Whl_Pressed" 31 "Defrost_Pressed" 32 "FrontMnu_Pressed" 33 "RearMnu_Pressed" 34 "Heat_Pressed" 35 "AAR_Pressed" 36 "MdeMnu_Pressed" 37 "DrvrFcsdMde_Pressed" 38 "LHS_Seat_Off_Pressed" 39 "LHS_Htd_Seat1_Pressed" 40 "LHS_Htd_Seat2_Pressed" 41 "LHS_Htd_Seat3_Pressed" 42 "LHS_Auto_Seat_Pressed" 43 "RHS_Seat_Off_Pressed" 44 "RHS_Htd_Seat1_Pressed" 45 "RHS_Htd_Seat2_Pressed" 46 "RHS_Htd_Seat3_Pressed" 47 "RHS_Auto_Seat_Pressed" 48 "LHS_Cld_Seat1_Pressed" 49 "LHS_Cld_Seat2_Pressed" 50 "LHS_Cld_Seat3_Pressed" 51 "RHS_Cld_Seat1_Pressed" 52 "RHS_Cld_Seat2_Pressed" 53 "RHS_Cld_Seat3_Pressed" 54 "AUTO_Lo_Pressed" 55 "AUTO_Med_Pressed" 56 "AUTO_Hi_Pressed" 57 "AUTO_Inc_Pressed" 58 "AUTO_Dec_Pressed" 59 "NotUsed_6" 60 "NotUsed_7" 61 "NotUsed_8" 62 "NotUsed_9" 63 "NotUsed_10" ;
VAL_ 866 CabnScentChnl_D_Rq 0 "Off" 1 "Channel_1" 2 "Channel_2" 3 "Channel_3" 4 "Channel_4" 5 "Channel_5" 6 "Channel_6" 7 "Channel_7" ;
VAL_ 866 Rr_Btn_Status_1st 0 "None_Pressed" 1 "Panel_Pressed" 2 "Panel_Floor_Pressed" 3 "Floor_Pressed" 4 "LHS_Temp_Inc_Pressed" 5 "LHS_Temp_Dec_Pressed" 6 "RHS_Temp_Inc_Pressed" 7 "RHS_Temp_Dec_Pressed" 8 "Blwr_Inc_Pressed" 9 "Blwr_Dec_Pressed" 10 "AUTO_Pressed" 11 "Rear_Power_Pressed" 12 "LHS_Htd_Seat_Pressed" 13 "RHS_Htd_Seat_Pressed" 14 "LHS_Cld_Seat_Pressed" 15 "RHS_Cld_Seat_Pressed" 16 "Rear_Lock_Pressed" 17 "Third_Blwr_Inc_Pressed" 18 "Third_Blwr_Dec_Pressed" 19 "Third_Panel_Pressed" 20 "Third_Floor_Pressed" 21 "Third_Pnl_Flr_Pressed" 22 "Third_Auto_Pressed" 23 "Third_Rr_Pwr_Pressed" 24 "Third_Sync_Pressed" 25 "NotUsed_1" 26 "NotUsed_2" 27 "NotUsed_3" 28 "NotUsed_4" 29 "NotUsed_5" 30 "NotUsed_6" 31 "NotUsed_7" ;
VAL_ 866 ClimtRearView_D_Stat 0 "NotDisplayed" 1 "Both" 2 "SecondRow" 3 "ThirdRow" ;
VAL_ 866 SnowPlowOn_B_Rq 0 "Off" 1 "On" ;
VAL_ 866 Rr_Btn_Status_2nd 0 "None_Pressed" 1 "Panel_Pressed" 2 "Panel_Floor_Pressed" 3 "Floor_Pressed" 4 "LHS_Temp_Inc_Pressed" 5 "LHS_Temp_Dec_Pressed" 6 "RHS_Temp_Inc_Pressed" 7 "RHS_Temp_Dec_Pressed" 8 "Blwr_Inc_Pressed" 9 "Blwr_Dec_Pressed" 10 "AUTO_Pressed" 11 "Rear_Power_Pressed" 12 "LHS_Htd_Seat_Pressed" 13 "RHS_Htd_Seat_Pressed" 14 "LHS_Cld_Seat_Pressed" 15 "RHS_Cld_Seat_Pressed" 16 "Rear_Lock_Pressed" 17 "Third_Blwr_Inc_Pressed" 18 "Third_Blwr_Dec_Pressed" 19 "Third_Panel_Pressed" 20 "Third_Floor_Pressed" 21 "Third_Pnl_Flr_Pressed" 22 "Third_Auto_Pressed" 23 "Third_Rr_Pwr_Pressed" 24 "Third_Sync_Pressed" 25 "NotUsed_1" 26 "NotUsed_2" 27 "NotUsed_3" 28 "NotUsed_4" 29 "NotUsed_5" 30 "NotUsed_6" 31 "NotUsed_7" ;
VAL_ 866 CabnScentIntns_D_Rq 0 "NotDetermined" 1 "Off" 2 "Very_Low" 3 "Low" 4 "Medium_Low" 5 "Medium" 6 "Medium_High" 7 "High" ;
VAL_ 866 Psngr_Set_Temp 0 "No_Request" 1 "LO" 2 "15_5" 3 "16_0" 4 "16_5" 5 "17_0" 6 "17_5" 7 "18_0" 8 "18_5" 9 "19_0" 10 "19_5" 11 "20_0" 12 "20_5" 13 "21_0" 14 "21_5" 15 "22_0" 16 "22_5" 17 "23_0" 18 "23_5" 19 "24_0" 20 "24_5" 21 "25_0" 22 "25_5" 23 "26_0" 24 "26_5" 25 "27_0" 26 "27_5" 27 "28_0" 28 "28_5" 29 "29_0" 30 "29_5" 31 "HI" ;
VAL_ 866 Frt_Blower_Speed2 0 "No_Request" 1 "Blower_Speed_1" 2 "Blower_Speed_2" 3 "Blower_Speed_3" 4 "Blower_Speed_4" 5 "Blower_Speed_5" 6 "Blower_Speed_6" 7 "Blower_Speed_7" 8 "Min_Blower" 9 "Max_Blower" 10 "Zero_Blower" 11 "NotUsed_2" 12 "NotUsed_3" 13 "NotUsed_4" 14 "NotUsed_5" 15 "NotUsed_6" ;
VAL_ 866 CabnScentFanCalib_No_Rq 0 "Invalid" 1 "Calib_1" 254 "Calib_254" 255 "NotDetermined" ;
VAL_ 867 EATC_LHS_Unit 0 "Off" 1 "Celsius" 2 "Fahrenheit" ;
VAL_ 867 LHS_Temp_Disp_Digit3 0 "OFF" 1 "0" 2 "5" ;
VAL_ 867 Front_Blower_Ind 0 "Indicators_Off" 1 "1_Indicator_On" 2 "2_Indicators_On" 3 "3_Indicators_On" 4 "4_Indicators_On" 5 "5_Indicators_On" 6 "6_Indicators_On" 7 "7_Indicators_On" 8 "8_Indicators_On" 9 "9_Indicators_On" 10 "10_Indicators_On" 11 "11_Indicators_On" 12 "12_Indicators_On" 13 "13_Indicators_On" 14 "14_Indicators_On" 15 "Display_Blank" ;
VAL_ 868 Rr_Blower_Indicate_Stat 0 "Indicators_Off" 1 "1_Indicator_On" 2 "2_Indicators_On" 3 "3_Indicators_On" 4 "4_Indicators_On" 5 "5_Indicators_On" 6 "6_Indicators_On" 7 "7_Indicators_On" 8 "8_Indicators_On" 9 "9_Indicators_On" 10 "10_Indicators_On" 11 "11_Indicators_On" 12 "12_Indicators_On" 13 "13_Indicators_On" 14 "14_Indicators_On" 15 "Display_Blank" ;
VAL_ 869 EngActv_B_Dsply 0 "Off" 1 "On" ;
VAL_ 869 EffWhlThresOn_B_Dsply 0 "Off" 1 "On" ;
VAL_ 869 ChrgActv_B_Dsply 0 "Off" 1 "On" ;
VAL_ 869 DchrgActv_B_Dsply 0 "Off" 1 "On" ;
VAL_ 869 RgenActv_B_Dsply 0 "Off" 1 "On" ;
VAL_ 869 PwrFlowTxt_D_Dsply 0 "No_Text" 1 "Disp_Hyb_Drive_Txt" 2 "Disp_Charg_HV_Batt_Txt" 3 "Disp_Idle_Txt" 4 "Disp_Idle_with_Chrg_Txt" 5 "Disp_Elec_Drv_Txt" 6 "Disp_Eng_Drv_Txt" 7 "Disp_Remote_Start_Txt" 8 "Disp_Charge_Cmplt_Txt" 9 "Disp_Fast_Charge_Cmplt_Txt" 10 "Disp_Fast_Charge_Txt" 11 "Disply_Rgen_Chrg_Txt" 12 "NotUsed4" 13 "NotUsed5" 14 "NotUsed6" 15 "NotUsed7" ;
VAL_ 869 FuelMaintMde_D_Dsply 0 "OK" 1 "Close_to_Fuel_Maint" 2 "In_Fuel_Maint_Mode" 3 "Feature_Not_Present" ;
VAL_ 869 EngOnMsg1_D_Dsply 0 "No_Display" 1 "Acceleration" 2 "High_Speed" 3 "Heater_Setting" 4 "Neutral_Gear" 5 "Engine_Cold" 6 "Batt_Charging" 7 "Low_Gear" 8 "Normal_Operation" 9 "Oil_Maintenance" 10 "Fuel_Maintenance" 11 "Hill_Decent_Control" 12 "Battery_Temperature" 13 "Drive_Mode_Selection" 14 "0xE_to_1F_NotUsed" ;
VAL_ 869 EngOnMsg2_D_Dsply 0 "No_Display" 1 "Acceleration" 2 "High_Speed" 3 "Heater_Setting" 4 "Neutral_Gear" 5 "Engine_Cold" 6 "Batt_Charging" 7 "Low_Gear" 8 "Normal_Operation" 9 "Oil_Maintenance" 10 "Fuel_Maintenance" 11 "Hill_Decent_Control" 12 "Battery_Temperature" 13 "Drive_Mode_Selection" 14 "0xE_to_1F_NotUsed" ;
VAL_ 869 EngOffTe_B_Dsply 0 "Eng_not_warm_engh_for_pd" 1 "Eng_warm_engh_for_pd" ;
VAL_ 870 PolicePurstMde_B_Stat 0 "Off" 1 "On" ;
VAL_ 870 HybMdeLimMsgTxt_D_Rq 0 "Null" 1 "Limited_System_Performance" 2 "Limited_Climate_Defrost" 3 "Limited_Req_Full_Defrost" ;
VAL_ 870 ChkPlgtoStrt_D_Dsply 0 "No_Message_Display" 1 "Check_Plug_to_Start" 2 "Is_VehicleUnplugged_Prompt" 3 "NotUsed" ;
VAL_ 870 EngMdeMsgTxt_D_Rq 0 "NoMessage" 1 "Ev" 2 "Hybrid" 3 "GlowingCharge" 4 "Charge" 5 "NotUsed_1" 6 "NotUsed_2" 7 "NotUsed_3" ;
VAL_ 870 ShifOutNtrlMsgTxt_D_Rq 0 "NoMessage" 1 "Message1" 2 "Message2" 3 "Message3" 4 "Message4" 5 "Message5" 6 "Message6" 7 "Message7" ;
VAL_ 870 HybMdeMsgTxt_D2_Rq 0 "Null" 1 "EvAutoActv_AllPhevMdeAvail" 2 "EvNowActv_AllPhevMdeAvail" 3 "EvLaterActv_AllPhevMdeAvai" 4 "EvChrgActv_AllPhevMdeAvail" 5 "EvAutoActv_EvChrgMdeAvail" 6 "EvChrgActv_EvAutoMdeAvail" 7 "EvAutoActv_NoOtherMdeAvail" 8 "EvAutoActv_EvNow_LaterAvai" 9 "EvNowActv_EvAuto_LaterAvai" 10 "EvLaterActv_EvAuto_NowAvai" 11 "EvOverride_Avail" 12 "NotUsed_1" 13 "NotUsed_2" 14 "NotUsed_3" 15 "NotUsed_4" ;
VAL_ 870 RngPerChrgInst_L_Dsply 4094 "NoDataExists" 4095 "Faulty" ;
VAL_ 871 BattChrgTrgtLPt_T_Est 2046 "NoDataExists" 2047 "Faulty" ;
VAL_ 871 BattChrgTrgSocPt_T_Est 2046 "NoDataExists" 2047 "Faulty" ;
VAL_ 871 BattChrgCmpltPt_T_Est 2046 "NoDataExists" 2047 "Faulty" ;
VAL_ 871 DrvEffLvlIncDec_D_Cmd 0 "Null_State" 1 "Increase_Level_by_1" 2 "Decrease_Level_by_1" 3 "NotUsed" ;
VAL_ 871 BattElecPerf_D_Actl 0 "Ok_no_message_displayed" 1 "Cold_Batt_Close_to_lim_Pe" 2 "Cold_Batt_Reduced_Perf" 3 "Cold_Batt_Severe_Lim_Perf" 4 "Hot_Batt_Close_to_lim_Per" 5 "Hot_Batt_Reduced_Perf" 6 "Hot_Batt_Severe_Lim_Perf" 7 "NotUsed" ;
VAL_ 872 PwFlowEngFuel_D_Dsply 0 "No_Flow" 1 "Flow_from_Fuel_to_Eng" 2 "Flow_from_Eng_to_Fuel" 3 "NotUsed" ;
VAL_ 872 PwFlowEngDrv_D_Dsply 0 "No_Flow" 1 "Flow_from_Axle_to_Eng" 2 "Flow_from_Eng_to_Axle" 3 "NotUsed" ;
VAL_ 872 PwFlowBattMtr_D_Dsply 0 "No_Flow" 1 "Flow_from_Mtr_to_Batt" 2 "Flow_from_Batt_to_Mtr" 3 "NotUsed" ;
VAL_ 872 PwFlowPlgBatt_D_Dsply 0 "No_Flow" 1 "Flow_from_Batt_to_Plug" 2 "Flow_from_Plug_to_Batt" 3 "NotUsed" ;
VAL_ 872 PwFlowMtrDrv_D_Dsply 0 "No_FLow" 1 "Flow_from_Axle_to_Mtr" 2 "Flow_from_Mtr_to_Axle" 3 "NotUsed" ;
VAL_ 872 PwFlowEngMtr_D_Dsply 0 "No_Flow" 1 "Flow_from_Mtr_to_Eng" 2 "Flow_from_Eng_to_Mtr" 3 "NotUsed" ;
VAL_ 872 EcoMode_B_Stat 0 "Off" 1 "On" ;
VAL_ 872 HybMdeStat_D_Dsply 0 "Null_State" 1 "Auto_Charge_Deplete_Mode" 2 "Auto_Charge_Sustain_Mode" 3 "Forced_Charge_Sustain_Mode" 4 "Forced_EV_Mode" 5 "EV_Override" 6 "EV_Charge" 7 "NotUsed2" ;
VAL_ 872 MildHybStat_D_Dsply 0 "Off" 1 "SystemError" 2 "SystemInhibited" 3 "Boost" 4 "Assist" 5 "Charge" 6 "Recovery" 7 "NotUsed" ;
VAL_ 872 PlgActvArb_B_Dsply 0 "Off" 1 "On" ;
VAL_ 873 GpsElMdeActv_B_Dsply 0 "Off" 1 "On" ;
VAL_ 873 EffRelTrgtOn_B_Dsply 0 "Off" 1 "On" ;
VAL_ 873 LoAirAmbPlgIn_B_Dsply 0 "Off" 1 "On" ;
VAL_ 873 BattTracEMaint_B_Dsply 0 "Off" 1 "On" ;
VAL_ 874 E_Frt_Btn_Status_1st 0 "None_Pressed" 1 "Panel_Pressed" 2 "Panel_Floor_Pressed" 3 "Floor_Pressed" 4 "Floor_Ws_Pressed" 5 "AC_Pressed" 6 "Dual_Pressed" 7 "LHS_Temp_Inc_Pressed" 8 "LHS_Temp_Dec_Pressed" 9 "RHS_Temp_Inc_Pressed" 10 "RHS_Temp_Dec_Pressed" 11 "Blwr_Inc_Pressed" 12 "Blwr_Dec_Pressed" 13 "Auto_Pressed" 14 "Max_AC_Pressed" 15 "Recirc_Pressed" 16 "Outside_Pressed" 17 "Auto_Recirc_Pressed" 18 "Htd_Frt_Wsh_Pressed" 19 "Windscreen_Pressed" 20 "Pnl_Ws_Pressed" 21 "Pnl_Flr_Ws_Pressed" 22 "Rear_Defrost_Pressed" 23 "Front_Power_Pressed" 24 "My_Temp_Pressed" 25 "Max_Defrost_Pressed" 26 "LHS_Htd_Seat_Pressed" 27 "RHS_Htd_Seat_Pressed" 28 "LHS_Cld_Seat_Pressed" 29 "RHS_Cld_Seat_Pressed" 30 "Htg_Strg_Whl_Pressed" 31 "Defrost_Pressed" 32 "FrontMnu_Pressed" 33 "RearMnu_Pressed" 34 "Heat_Pressed" 35 "AAR_Pressed" 36 "MdeMnu_Pressed" 37 "DrvrFcsdMde_Pressed" 38 "LHS_Seat_Off_Pressed" 39 "LHS_Htd_Seat1_Pressed" 40 "LHS_Htd_Seat2_Pressed" 41 "LHS_Htd_Seat3_Pressed" 42 "LHS_Auto_Seat_Pressed" 43 "RHS_Seat_Off_Pressed" 44 "RHS_Htd_Seat1_Pressed" 45 "RHS_Htd_Seat2_Pressed" 46 "RHS_Htd_Seat3_Pressed" 47 "RHS_Auto_Seat_Pressed" 48 "LHS_Cld_Seat1_Pressed" 49 "LHS_Cld_Seat2_Pressed" 50 "LHS_Cld_Seat3_Pressed" 51 "RHS_Cld_Seat1_Pressed" 52 "RHS_Cld_Seat2_Pressed" 53 "RHS_Cld_Seat3_Pressed" 54 "AUTO_Lo_Pressed" 55 "AUTO_Med_Pressed" 56 "AUTO_Hi_Pressed" 57 "AUTO_Inc_Pressed" 58 "AUTO_Dec_Pressed" 59 "NotUsed_1" 60 "NotUsed_2" 61 "NotUsed_3" 62 "NotUsed_4" 63 "NotUsed_5" ;
VAL_ 874 E_Frt_Btn_Status_2nd 0 "None_Pressed" 1 "Panel_Pressed" 2 "Panel_Floor_Pressed" 3 "Floor_Pressed" 4 "Floor_Ws_Pressed" 5 "AC_Pressed" 6 "Dual_Pressed" 7 "LHS_Temp_Inc_Pressed" 8 "LHS_Temp_Dec_Pressed" 9 "RHS_Temp_Inc_Pressed" 10 "RHS_Temp_Dec_Pressed" 11 "Blwr_Inc_Pressed" 12 "Blwr_Dec_Pressed" 13 "Auto_Pressed" 14 "Max_AC_Pressed" 15 "Recirc_Pressed" 16 "Outside_Pressed" 17 "Auto_Recirc_Pressed" 18 "Htd_Frt_Wsh_Pressed" 19 "Windscreen_Pressed" 20 "Pnl_Ws_Pressed" 21 "Pnl_Flr_Ws_Pressed" 22 "Rear_Defrost_Pressed" 23 "Front_Power_Pressed" 24 "My_Temp_Pressed" 25 "Max_Defrost_Pressed" 26 "LHS_Htd_Seat_Pressed" 27 "RHS_Htd_Seat_Pressed" 28 "LHS_Cld_Seat_Pressed" 29 "RHS_Cld_Seat_Pressed" 30 "Htg_Strg_Whl_Pressed" 31 "Defrost_Pressed" 32 "FrontMnu_Pressed" 33 "RearMnu_Pressed" 34 "Heat_Pressed" 35 "AAR_Pressed" 36 "MdeMnu_Pressed" 37 "DrvrFcsdMde_Pressed" 38 "LHS_Seat_Off_Pressed" 39 "LHS_Htd_Seat1_Pressed" 40 "LHS_Htd_Seat2_Pressed" 41 "LHS_Htd_Seat3_Pressed" 42 "LHS_Auto_Seat_Pressed" 43 "RHS_Seat_Off_Pressed" 44 "RHS_Htd_Seat1_Pressed" 45 "RHS_Htd_Seat2_Pressed" 46 "RHS_Htd_Seat3_Pressed" 47 "RHS_Auto_Seat_Pressed" 48 "LHS_Cld_Seat1_Pressed" 49 "LHS_Cld_Seat2_Pressed" 50 "LHS_Cld_Seat3_Pressed" 51 "RHS_Cld_Seat1_Pressed" 52 "RHS_Cld_Seat2_Pressed" 53 "RHS_Cld_Seat3_Pressed" 54 "AUTO_Lo_Pressed" 55 "AUTO_Med_Pressed" 56 "AUTO_Hi_Pressed" 57 "AUTO_Inc_Pressed" 58 "AUTO_Dec_Pressed" 59 "NotUsed_1" 60 "NotUsed_2" 61 "NotUsed_3" 62 "NotUsed_4" 63 "NotUsed_5" ;
VAL_ 874 E_Rr_Btn_Status_1st 0 "None_Pressed" 1 "Panel_Pressed" 2 "Panel_Floor_Pressed" 3 "Floor_Pressed" 4 "LHS_Temp_Inc_Pressed" 5 "LHS_Temp_Dec_Pressed" 6 "RHS_Temp_Inc_Pressed" 7 "RHS_Temp_Dec_Pressed" 8 "Blwr_Inc_Pressed" 9 "Blwr_Dec_Pressed" 10 "AUTO_Pressed" 11 "Rear_Power_Pressed" 12 "LHS_Htd_Seat_Pressed" 13 "RHS_Htd_Seat_Pressed" 14 "LHS_Cld_Seat_Pressed" 15 "RHS_Cld_Seat_Pressed" 16 "Rear_Lock_Pressed" 17 "Third_Blwr_Inc_Pressed" 18 "Third_Blwr_Dec_Pressed" 19 "Third_Panel_Pressed" 20 "Third_Floor_Pressed" 21 "Third_Pnl_Flr_Pressed" 22 "Third_Auto_Pressed" 23 "Third_Rr_Pwr_Pressed" 24 "Third_Synch_Pressed" 25 "NotUsed9" 26 "NotUsed10" 27 "NotUsed11" 28 "NotUsed12" 29 "NotUsed13" 30 "NotUsed14" 31 "NotUsed15" ;
VAL_ 874 E_Rr_Btn_Status_2nd 0 "None_Pressed" 1 "Panel_Pressed" 2 "Panel_Floor_Pressed" 3 "Floor_Pressed" 4 "LHS_Temp_Inc_Pressed" 5 "LHS_Temp_Dec_Pressed" 6 "RHS_Temp_Inc_Pressed" 7 "RHS_Temp_Dec_Pressed" 8 "Blwr_Inc_Pressed" 9 "Blwr_Dec_Pressed" 10 "AUTO_Pressed" 11 "Rear_Power_Pressed" 12 "LHS_Htd_Seat_Pressed" 13 "RHS_Htd_Seat_Pressed" 14 "LHS_Cld_Seat_Pressed" 15 "RHS_Cld_Seat_Pressed" 16 "Rear_Lock_Pressed" 17 "Third_Blwr_Inc_Pressed" 18 "Third_Blwr_Dec_Pressed" 19 "Third_Panel_Pressed" 20 "Third_Floor_Pressed" 21 "Third_Pnl_Flr_Pressed" 22 "Third_Auto_Pressed" 23 "Third_Rr_Pwr_Pressed" 24 "Third_Synch_Pressed" 25 "NotUsed9" 26 "NotUsed10" 27 "NotUsed11" 28 "NotUsed12" 29 "NotUsed13" 30 "NotUsed14" 31 "NotUsed15" ;
VAL_ 875 SeatPRl_B_Stat 0 "NotUpdating" 1 "Updating" ;
VAL_ 875 SeatFnRl_D_Stat 0 "Null" 1 "LowerLumbar" 2 "MiddleLumbar" 3 "UpperLumbar" 4 "LowerBolster" 5 "UpperBolster" 6 "LumbarMassage" 7 "CushionMassage" ;
VAL_ 875 StmsLmbrDrv_D_Stat2 0 "Null" 1 "Off" 2 "Low" 3 "High" ;
VAL_ 875 StmsCshnDrv_D_Stat2 0 "Null" 1 "Off" 2 "Low" 3 "High" ;
VAL_ 875 SeatSwtchRl_B_Stat 0 "Off" 1 "On" ;
VAL_ 875 SeatMasgDrvRr_D_Stat 0 "Null" 1 "Pattern1" 2 "Pattern2" 3 "Pattern3" 4 "Pattern4" 5 "Pattern5" 6 "Pattern6" 7 "Pattern7" 8 "Pattern8" 9 "Pattern9" 10 "Pattern10" 11 "NotUsed_6" 12 "NotUsed_7" 13 "NotUsed_8" 14 "NotUsed_9" 15 "NotUsed_10" ;
VAL_ 875 SeatIntnsDrvRr_D_Stat 0 "Null" 1 "Off" 2 "Low" 3 "Medium" 4 "High" 5 "NotUsed_1" 6 "NotUsed_2" 7 "NotUsed_3" ;
VAL_ 875 StmsMduleDrvRear_D_St 0 "Null" 1 "Off" 2 "Partial_Active" 3 "Fully_Active" ;
VAL_ 876 SeatPRr_B_Stat 0 "NotUpdating" 1 "Updating" ;
VAL_ 876 SeatFnRr_D_Stat 0 "Null" 1 "LowerLumbar" 2 "MiddleLumbar" 3 "UpperLumbar" 4 "LowerBolster" 5 "UpperBolster" 6 "LumbarMassage" 7 "CushionMassage" ;
VAL_ 876 StmsLmbrPsgr_D_Stat2 0 "Null" 1 "Off" 2 "Low" 3 "High" ;
VAL_ 876 StmsCshnPsgr_D_Stat2 0 "Null" 1 "Off" 2 "Low" 3 "High" ;
VAL_ 876 SeatSwtchRr_B_Stat 0 "Off" 1 "On" ;
VAL_ 876 SeatMasgPsngrRr_D_Stat 0 "Null" 1 "Pattern1" 2 "Pattern2" 3 "Pattern3" 4 "Pattern4" 5 "Pattern5" 6 "Pattern6" 7 "Pattern7" 8 "Pattern8" 9 "Pattern9" 10 "Pattern10" 11 "NotUsed_6" 12 "NotUsed_7" 13 "NotUsed_8" 14 "NotUsed_9" 15 "NotUsed_10" ;
VAL_ 876 SeatIntnsPsngrRr_D_Stat 0 "Null" 1 "Off" 2 "Low" 3 "Medium" 4 "High" 5 "NotUsed_1" 6 "NotUsed_2" 7 "NotUsed_3" ;
VAL_ 876 StmsMdulePsngRear_D_St 0 "Null" 1 "Off" 2 "Partial_Active" 3 "Fully_Active" ;
VAL_ 877 Rr_Synch_Btn_Stt 0 "Enabled_Inactive" 1 "Active" 2 "Disabled" 3 "Unused" ;
VAL_ 877 Rr_Lock_Btn_Stt 0 "Enabled_Inactive" 1 "Active" 2 "Disabled" 3 "Unused" ;
VAL_ 877 Heat_Btn_Stt 0 "Enabled_Inactive" 1 "Active" 2 "Disabled" 3 "Unused" ;
VAL_ 877 AAR_Btn_Stt 0 "Enabled_Inactive" 1 "Active" 2 "Disabled" 3 "Unused" ;
VAL_ 877 RstrtClimtSet_B_Actv 0 "Inactive" 1 "Active" ;
VAL_ 877 Rr_RHS_Blower_Indicate 0 "Indicators_Off" 1 "1_Indicator_On" 2 "2_Indicators_On" 3 "3_Indicators_On" 4 "4_Indicators_On" 5 "5_Indicators_On" 6 "6_Indicators_On" 7 "7_Indicators_On" 8 "8_Indicators_On" 9 "9_Indicators_On" 10 "10_Indicators_On" 11 "11_Indicators_On" 12 "12_Indicators_On" 13 "13_Indicators_On" 14 "14_Indicators_On" 15 "Display_Blank" ;
VAL_ 877 Rr_Third_Power_Btn_Stt 0 "Enabled_Inactive" 1 "Active" 2 "Disabled" 3 "Unused" ;
VAL_ 877 Rr_Third_Panel_Btn_Stt 0 "Enabled_Inactive" 1 "Active" 2 "Disabled" 3 "Unused" ;
VAL_ 877 Rr_Third_Floor_Btn_Stt 0 "Enabled_Inactive" 1 "Active" 2 "Disabled" 3 "Unused" ;
VAL_ 877 Rr_Third_Auto_Btn_Stt 0 "Enabled_Inactive" 1 "Active" 2 "Disabled" 3 "Unused" ;
VAL_ 877 CabnAmb_Te_ActlAft 255 "Faulty" ;
VAL_ 877 Manual_Temp_Setting2 0 "Off" 1 "Full_Cool" 2 "Setting_2" 3 "Setting_3" 4 "Setting_4" 5 "Setting_5" 6 "Setting_6" 7 "Setting_7" 8 "Setting_8" 9 "Setting_9" 10 "Setting_10" 11 "Setting_11" 12 "Setting_12" 13 "Setting_13" 14 "Setting_14" 15 "Setting_15" 16 "Setting_16" 17 "Setting_17" 18 "Setting_18" 19 "Setting_19" 20 "Setting_20" 21 "Setting_21" 22 "Setting_22" 23 "Setting_23" 24 "Setting_24" 25 "Setting_25" 26 "Setting_26" 27 "Setting_27" 28 "Setting_28" 29 "Setting_29" 30 "Setting_30" 31 "Full_Heat" ;
VAL_ 878 ClimtRearTe2_An_Actl 511 "Faulty" ;
VAL_ 878 ClimtRearBlwr2_D_Stat 0 "Inactive" 1 "Increment" 2 "Decrement" 3 "NotUsed" ;
VAL_ 878 ClimtRearTe2_D_Stat 0 "Inactive" 1 "Increment" 2 "Decrement" 3 "NotUsed" ;
VAL_ 878 ClimtRearFlr2_B_Stat 0 "Not_Pressed" 1 "Pressed" ;
VAL_ 878 ClimtRearPnlFlr2_B_Stat 0 "Not_Pressed" 1 "Pressed" ;
VAL_ 878 ClimtRearPnl2_B_Stat 0 "Not_Pressed" 1 "Pressed" ;
VAL_ 878 ClimtRearBlwr2_An_Actl 511 "Faulty" ;
VAL_ 878 ClimtRearPw2_B_Stat 0 "Not_Pressed" 1 "Pressed" ;
VAL_ 878 ClimtRearAuto2_B_Stat 0 "Not_Pressed" 1 "Pressed" ;
VAL_ 878 ClimtSeatRr2_D_Rq 2 "Off" 4 "C1_Low_Cool" 8 "C2_Medium_Cool" 16 "C3_High_Cool_MAX" 32 "H1_Low_Heat" 64 "H2_Medium_Heat" 128 "H3_High_Heat_MAX" ;
VAL_ 878 ClimtSeatRl2_D_Rq 2 "Off" 4 "C1_Low_Cool" 8 "C2_Medium_Cool" 16 "C3_High_Cool_MAX" 32 "H1_Low_Heat" 64 "H2_Medium_Heat" 128 "H3_High_Heat_MAX" ;
VAL_ 878 ClimtRrBlwr3rd2_D_Stat 0 "Inactive" 1 "Increment" 2 "Decrement" 3 "NotUsed" ;
VAL_ 878 ClimtRrTe3rd2_D_Stat 0 "Inactive" 1 "Increment" 2 "Decrement" 3 "NotUsed" ;
VAL_ 878 ClimtStCoolRr2_B_Stat 0 "Not_Pressed" 1 "Pressed" ;
VAL_ 878 ClimtStCoolRl2_B_Stat 0 "Not_Pressed" 1 "Pressed" ;
VAL_ 878 ClimtStHeatRr2_B_Stat 0 "Not_Pressed" 1 "Pressed" ;
VAL_ 878 ClimtStHeatRl2_B_Stat 0 "Not_Pressed" 1 "Pressed" ;
VAL_ 878 ClimtRearView2_D_Stat 0 "NotDisplayed" 1 "Both" 2 "SecondRow" 3 "ThirdRow" ;
VAL_ 878 ClimtSyncRear2_B_Stat 0 "Not_Pressed" 1 "Pressed" ;
VAL_ 878 ClimtRrPw3rd2_B_Stat 0 "Not_Pressed" 1 "Pressed" ;
VAL_ 878 ClimtRrAuto3rd2_B_Stat 0 "Not_Pressed" 1 "Pressed" ;
VAL_ 878 ClimtRrFlr3rd2_B_Stat 0 "Not_Pressed" 1 "Pressed" ;
VAL_ 878 ClimtRrPnl3rd2_B_Stat 0 "Not_Pressed" 1 "Pressed" ;
VAL_ 878 ClimtRrPf3rd2_B_Stat 0 "Not_Pressed" 1 "Pressed" ;
VAL_ 883 PmCabn02Mnte_Conc_Actl 510 "NoDataExists" 511 "Faulty" ;
VAL_ 883 PmCabn04Mnte_Conc_Actl 510 "NoDataExists" 511 "Faulty" ;
VAL_ 883 PmCabn06Mnte_Conc_Actl 510 "NoDataExists" 511 "Faulty" ;
VAL_ 883 PmCabn08Mnte_Conc_Actl 510 "NoDataExists" 511 "Faulty" ;
VAL_ 883 PmCabn10Mnte_Conc_Actl 510 "NoDataExists" 511 "Faulty" ;
VAL_ 884 PmCabn12Mnte_Conc_Actl 510 "NoDataExists" 511 "Faulty" ;
VAL_ 884 PmCabn14Mnte_Conc_Actl 510 "NoDataExists" 511 "Faulty" ;
VAL_ 884 PmCabn16Mnte_Conc_Actl 510 "NoDataExists" 511 "Faulty" ;
VAL_ 884 PmCabn18Mnte_Conc_Actl 510 "NoDataExists" 511 "Faulty" ;
VAL_ 884 PmCabn20Mnte_Conc_Actl 510 "NoDataExists" 511 "Faulty" ;
VAL_ 884 PmCabn_Conc_Actl 510 "NoDataExists" 511 "Faulty" ;
VAL_ 884 UltraFreshCabn_D_Stat 0 "Null" 1 "Inactive" 2 "Active" 3 "Complete" 4 "Interrupted" 5 "NotSupported" 6 "NotUsed_1" 7 "NotUsed_2" ;
VAL_ 884 PmSnsCabn_D_Stat 0 "Initializing" 1 "Unsupported" 2 "CleanSensor" 3 "ReplaceSensor" 4 "BlankField" 5 "NoIssue" 6 "IntermittentInhibit" 7 "NotUsed_1" ;
VAL_ 885 VehOn_D_RqCld 0 "Null" 1 "Off" 2 "On" 3 "NoControl" ;
VAL_ 885 VehOnRqstr_D_Stat 0 "NoRequestor" 1 "OverTheAir" 2 "StolenVehInhbt" 3 "FleetVehInhbt" 4 "NotUsed_1" 5 "NotUsed_2" 6 "NotUsed_3" 7 "NotUsed_4" 8 "NotUsed_5" 9 "NotUsed_6" 10 "NotUsed_7" 11 "NotUsed_8" 12 "NotUsed_9" 13 "NotUsed_10" 14 "NotUsed_11" 15 "NotUsed_12" ;
VAL_ 885 VehStrtInhbt_D_RqCld 0 "Null" 1 "Off" 2 "On" 3 "NotUsed" ;
VAL_ 885 VehStrtInhbt_D_Dsply 0 "NoMessage" 1 "DuringOtaActivate" 2 "PostOtaActivateWarning" 3 "PostOtaActivatePermFail" 4 "OtaSuccess" 5 "FleetGeneral" 6 "FleetPhoneNumber" 7 "AutoInhibit" 8 "NotUsed_5" 9 "NotUsed_6" 10 "NotUsed_7" 11 "NotUsed_8" 12 "NotUsed_9" 13 "NotUsed_10" 14 "NotUsed_11" 15 "NotUsed_12" ;
VAL_ 885 OtaActv_D_Stat 0 "NoInVehicleOta" 1 "Interruptible_AB" 2 "NonInterruptible_AB" 3 "NonInterruptible_ER" 4 "NonInterruptible_Config" 5 "NonInterruptible_Pending" 6 "NotUsed_1" 7 "NotUsed_2" 8 "NotUsed_3" 9 "NotUsed_4" 10 "NotUsed_5" 11 "NotUsed_6" 12 "NotUsed_7" 13 "NotUsed_8" 14 "NotUsed_9" 15 "NotUsed_10" ;
VAL_ 885 BattULoChrg_D_RqOta 0 "No" 1 "Yes" ;
VAL_ 890 ActvNseMute_D_Rq 0 "Inactive" 1 "Unmute" 2 "Mute" 3 "NotUsed_1" ;
VAL_ 890 ActvNse_B_Actv 0 "Inactive" 1 "Active" ;
VAL_ 890 ActvNseAudio_D_Stat 0 "Invalid" 1 "Audio_Standby" 2 "Audio_Active" 3 "Audio_Off" ;
VAL_ 896 Trip1BattULoE_Pc_Dsply 1022 "NoDataExists" 1023 "Faulty" ;
VAL_ 896 Trip1ClimE_Pc_Dsply 1022 "NoDataExists" 1023 "Faulty" ;
VAL_ 896 Trip1ExtFctrE_Pc_Dsply 1022 "NoDataExists" 1023 "Faulty" ;
VAL_ 896 Trip1SumDrvE_Pc_Dsply 1022 "NoDataExists" 1023 "Faulty" ;
VAL_ 896 VehElAvgTrip1_Eff_Dsply 126 "NoDataExists" 127 "Faulty" ;
VAL_ 896 BptDly_T_Actl 62 "NoDataExists" 63 "Faulty" ;
VAL_ 897 Trip2BattULoE_Pc_Dsply 1022 "NoDataExists" 1023 "Faulty" ;
VAL_ 897 Trip2ClimE_Pc_Dsply 1022 "NoDataExists" 1023 "Faulty" ;
VAL_ 897 Trip2ExtFctrE_Pc_Dsply 1022 "NoDataExists" 1023 "Faulty" ;
VAL_ 897 Trip2SumDrvE_Pc_Dsply 1022 "NoDataExists" 1023 "Faulty" ;
VAL_ 897 VehElAvgTrip2_Eff_Dsply 126 "NoDataExists" 127 "Faulty" ;
VAL_ 898 SecondRowBuckleDrvMid 0 "Faulty" 1 "Belted" 2 "Unbelted" 3 "Unknown" ;
VAL_ 898 FourthRowBucklePsngr 0 "Faulty" 1 "Belted" 2 "Unbelted" 3 "Unknown" ;
VAL_ 898 FourthRowBuckleMid 0 "Faulty" 1 "Belted" 2 "Unbelted" 3 "Unknown" ;
VAL_ 898 FourthRowBuckleDriver 0 "Faulty" 1 "Belted" 2 "Unbelted" 3 "Unknown" ;
VAL_ 898 Row2PsngrPrsnc_D_Actl 0 "Fault" 1 "Occupied" 2 "Empty" 3 "Unknown" ;
VAL_ 898 Row2MidPrsnc_D_Actl 0 "Fault" 1 "Occupied" 2 "Empty" 3 "Unknown" ;
VAL_ 898 Row2DrvPrsnc_D_Actl 0 "Fault" 1 "Occupied" 2 "Empty" 3 "Unknown" ;
VAL_ 898 SecondRowBcklPsngrMid 0 "Faulty" 1 "Belted" 2 "Unbelted" 3 "Unknown" ;
VAL_ 898 Row3PsngrPrsnc_D_Actl 0 "Fault" 1 "Occupied" 2 "Empty" 3 "Unknown" ;
VAL_ 898 Row3MidPrsnc_D_Actl 0 "Fault" 1 "Occupied" 2 "Empty" 3 "Unknown" ;
VAL_ 898 Row3DrvPrsnc_D_Actl 0 "Fault" 1 "Occupied" 2 "Empty" 3 "Unknown" ;
VAL_ 898 VedsPrmDirOfF_An_Ltchd 0 "No_Event" 254 "Not_Supported" 255 "Faulty" ;
VAL_ 898 VedsRoll_An_Ltchd 0 "No_Event" 8190 "Not_Supported" 8191 "Faulty" ;
VAL_ 901 AplSnd_D_Rq 0 "NoSound" 1 "MgMercNudge" 2 "RNudge" 3 "MgMercBttnPressOrder" 4 "MgMercBttnPressKeypad" 5 "MgRecBttnPressKeypad" 6 "RBttnPressKeypad" 7 "MgRecTimeOut" 8 "MgMercTimeOut" 9 "RTimeOutUnloading" 10 "RTimeOutLoading" 11 "MgMercExtendTime" 12 "MgReciExtendTime" 13 "RExtendTimeLoading" 14 "RExtendTimeUnloading" 15 "MgMercMaxTime" 16 "MgRecMaxTime" 17 "RMaxTime" 18 "MgMercAuthSucc" 19 "MgRecAuthSucc" 20 "RAuthSucc" 21 "MgRec_6ft" 22 "R_6ft" 23 "MgMercAuthFail" 24 "RAuthFail" 25 "MgMercAuthFailMax" 26 "RAuthFailMax" 27 "MgRecBarcode" 28 "MgRecBarcodeError" 29 "MgMercLoadOrder" 30 "MgRecOpenDoor" 31 "MgMercItemDetection" 32 "MgRecItemDetection" 33 "RItemDetection" 34 "MgRecCallCustCare" 35 "RCallCustCare" 36 "MgRecCustCareCalling" 37 "RCustCareCalling" 38 "MgRecAuthFail_Max" 39 "MgMercOpenDoor" 40 "ROpenDoor" 41 "NotUsed_2" 42 "NotUsed_3" 43 "NotUsed_4" 44 "NotUsed_5" 45 "NotUsed_6" 46 "NotUsed_7" 47 "NotUsed_8" 48 "NotUsed_9" 49 "NotUsed_10" 50 "NotUsed_11" 51 "NotUsed_12" 52 "NotUsed_13" 53 "NotUsed_14" 54 "NotUsed_15" 55 "NotUsed_16" 56 "NotUsed_17" 57 "NotUsed_18" 58 "NotUsed_19" 59 "NotUsed_20" 60 "NotUsed_21" 61 "NotUsed_22" 62 "NotUsed_23" 63 "NotUsed_24" ;
VAL_ 903 AprSnd_D_Rq 0 "NoSound" 1 "MgMercNudge" 2 "RNudge" 3 "MgMercBttnPressOrder" 4 "MgMercBttnPressKeypad" 5 "MgRecBttnPressKeypad" 6 "RBttnPressKeypad" 7 "MgRecTimeOut" 8 "MgMercTimeOut" 9 "RTimeOutUnloading" 10 "RTimeOutLoading" 11 "MgMercExtendTime" 12 "MgReciExtendTime" 13 "RExtendTimeLoading" 14 "RExtendTimeUnloading" 15 "MgMercMaxTime" 16 "MgRecMaxTime" 17 "RMaxTime" 18 "MgMercAuthSucc" 19 "MgRecAuthSucc" 20 "RAuthSucc" 21 "MgRec_6ft" 22 "R_6ft" 23 "MgMercAuthFail" 24 "RAuthFail" 25 "MgMercAuthFailMax" 26 "RAuthFailMax" 27 "MgRecBarcode" 28 "MgRecBarcodeError" 29 "MgMercLoadOrder" 30 "MgRecOpenDoor" 31 "MgMercItemDetection" 32 "MgRecItemDetection" 33 "RItemDetection" 34 "MgRecCallCustCare" 35 "RCallCustCare" 36 "MgRecCustCareCalling" 37 "RCustCareCalling" 38 "MgRecAuthFail_Max" 39 "MgMercOpenDoor" 40 "ROpenDoor" 41 "NotUsed_2" 42 "NotUsed_3" 43 "NotUsed_4" 44 "NotUsed_5" 45 "NotUsed_6" 46 "NotUsed_7" 47 "NotUsed_8" 48 "NotUsed_9" 49 "NotUsed_10" 50 "NotUsed_11" 51 "NotUsed_12" 52 "NotUsed_13" 53 "NotUsed_14" 54 "NotUsed_15" 55 "NotUsed_16" 56 "NotUsed_17" 57 "NotUsed_18" 58 "NotUsed_19" 59 "NotUsed_20" 60 "NotUsed_21" 61 "NotUsed_22" 62 "NotUsed_23" 63 "NotUsed_24" ;
VAL_ 904 AplPrimForUnload_D_Rq 0 "NoRequest" 1 "Disable" 2 "Enable" 3 "NotUsed_1" ;
VAL_ 904 AplPrimForLoad_D_Rq 0 "NoRequest" 1 "Disable" 2 "Enable" 3 "NotUsed_1" ;
VAL_ 904 AplReas_D_Stat 0 "Commanded" 1 "Faulted" 2 "SystemOverride" 3 "UserOverride" ;
VAL_ 904 AplHelpButtn_D_Stat 0 "NoCallRequest" 1 "RequestCall" 2 "CancelCall" 3 "PwFailed" ;
VAL_ 904 AprForNextOrder_D_Rq 0 "NoRequest" 1 "Disable" 2 "Enable" 3 "NotUsed_1" ;
VAL_ 905 AprPrimForUnload_D_Rq 0 "NoRequest" 1 "Disable" 2 "Enable" 3 "NotUsed_1" ;
VAL_ 905 AprPrimForLoad_D_Rq 0 "NoRequest" 1 "Disable" 2 "Enable" 3 "NotUsed_1" ;
VAL_ 905 AprReas_D_Stat 0 "Commanded" 1 "Faulted" 2 "SystemOverride" 3 "UserOverride" ;
VAL_ 905 AprHelpButtn_D_Stat 0 "NoCallRequest" 1 "RequestCall" 2 "CancelCall" 3 "PwFailed" ;
VAL_ 905 AplForNextOrder_D_Rq 0 "NoRequest" 1 "Disable" 2 "Enable" 3 "NotUsed_1" ;
VAL_ 909 KeyMykeyTot_No_Cnt 0 "Zero" 1 "One" 2 "Two" 3 "Three" 4 "Four" 5 "Five" 6 "Six" 7 "Seven" 8 "Eight" 9 "Nine" 10 "Ten" 11 "Eleven" 12 "Twelve" 13 "Thirteen" 14 "Unlimited" 15 "Invalid" ;
VAL_ 909 KeyAdmnTot_No_Cnt 0 "Zero" 1 "One" 2 "Two" 3 "Three" 4 "Four" 5 "Five" 6 "Six" 7 "Seven" 8 "Eight" 9 "Nine" 10 "Ten" 11 "Eleven" 12 "Twelve" 13 "Thirteen" 14 "Unlimited" 15 "Invalid" ;
VAL_ 909 SteWhlLckMsgTxt_D_Rq 0 "No_Message" 1 "Message_1" 2 "Message_2" 3 "Message_3" ;
VAL_ 909 PEBackupSlot_Stats 0 "Null" 1 "Standard_FOB_In_Slot" 2 "MyKey_FOB_In_Slot" 3 "No_Valid_FOB_In_Slot" ;
VAL_ 909 PrmtrAlrmEvnt_D_Stat 0 "Null" 1 "DF_Door" 2 "DR_Door" 3 "PF_Door" 4 "PR_Door" 5 "Hood" 6 "Decklid" 7 "LG_Door" 8 "Ign_Tamper" 9 "Inclination" 10 "Intrusion" 11 "Panic" 12 "Post_Crash" 13 "Shock_Sensor" 14 "Trailer" 15 "Diag_Tamper" ;
VAL_ 909 immoMsgTxt_D_Rq 0 "Immo_Msg_0_Null" 1 "Immo_Msg_1" 2 "Immo_Msg_2" 3 "Immo_Msg_3" 4 "Immo_Msg_4" 5 "Immo_Msg_5" 6 "Immo_Msg_6" 7 "Immo_Msg_7" 8 "Immo_Msg_8" 9 "Immo_Msg_9" 10 "Immo_Msg_10" 11 "Immo_Msg_11" 12 "Immo_Msg_12" 13 "Immo_Msg_13" 14 "Immo_Msg_14" 15 "Immo_Msg_15" ;
VAL_ 909 PrsnlDevcChrgEnbl_B_Rq 0 "Inactive" 1 "Active" ;
VAL_ 909 DrLatchMsgTxt_D_Rq 0 "NoMessage" 1 "Message1" 2 "Message2" 3 "Message3" 4 "Message4" 5 "Message5" 6 "Message6" 7 "Message7" ;
VAL_ 909 TracKeyMde_D_Stat 0 "ModeNotDetermined" 1 "Active" 2 "NotActive" 3 "NotUsed" ;
VAL_ 909 SecurityMsgTxt_D_Rq 0 "NoMessage" 1 "Message1" 2 "Message2" 3 "Message3" ;
VAL_ 909 TurnLghtSwtch_D_Stat2 0 "Off" 1 "Left" 2 "Right" 3 "NotUsed" ;
VAL_ 909 HeadLghtHiPrmsn_D_Stat 0 "AllowChange" 1 "Hold" 2 "Cancel" 3 "CancelAndSuppress" ;
VAL_ 909 PoliceIdlMde_D_Stat 0 "Off" 1 "Prearmed" 2 "Arm" 3 "Active" 4 "OffFault" 5 "PrearmedFault" 6 "ArmFault" 7 "ActiveFault" 8 "Decommissioned" 9 "PepsActive" 10 "UtilityIdleActive" 11 "NotUsed_3" 12 "NotUsed_4" 13 "NotUsed_5" 14 "NotUsed_6" 15 "NotUsed_7" ;
VAL_ 909 HazrdLght_B_Stat 0 "Off" 1 "On" ;
VAL_ 909 IgnPsswrdDsply_B_Rq 0 "Inactive" 1 "Active" ;
VAL_ 909 ElPwPoint_D_Rq 0 "Null" 1 "Off1" 2 "Off2" 3 "On" ;
VAL_ 909 WiprFront_D_Stat2 0 "OFF" 1 "AUTO_OFF" 2 "OFF_MOVING" 3 "MAN_INT_OFF" 4 "MAN_INT_ON" 5 "MAN_LOW" 6 "MAN_HIGH" 7 "MIST_FLICK" 8 "WASH" 9 "AUTO_LOW" 10 "AUTO_HIGH" 11 "COURTESYWIPE" 12 "AUTO_ADJUST" 13 "NotUsed" 14 "STALLED" 15 "NO_DATA_EXISTS" ;
VAL_ 912 AdasRelay_B_Stat 0 "Off" 1 "On" ;
VAL_ 912 BattTracSov_D_Stat 0 "OffNoPowerToLoad" 1 "OnPowerToLoad" 2 "FetNotControlled" 3 "FetOutputShortToGround" 4 "FetOutputShortToPower" 5 "FetOpenCircuit" 6 "FetLifeLimitReached" 7 "FetLowSideOpenOrShort" ;
VAL_ 912 BattChlrSov_D_Stat 0 "OffNoPowerToLoad" 1 "OnPowerToLoad" 2 "FetNotControlled" 3 "FetOutputShortToGround" 4 "FetOutputShortToPower" 5 "FetOpenCircuit" 6 "FetLifeLimitReached" 7 "FetLowSideOpenOrShort" ;
VAL_ 912 CabnEvapSovRear_D_Stat 0 "OffNoPowerToLoad" 1 "OnPowerToLoad" 2 "FetNotControlled" 3 "FetOutputShortToGround" 4 "FetOutputShortToPower" 5 "FetOpenCircuit" 6 "FetLifeLimitReached" 7 "FetLowSideOpenOrShort" ;
VAL_ 912 CabnEvapSovFront_D_Stat 0 "OffNoPowerToLoad" 1 "OnPowerToLoad" 2 "FetNotControlled" 3 "FetOutputShortToGround" 4 "FetOutputShortToPower" 5 "FetOpenCircuit" 6 "FetLifeLimitReached" 7 "FetLowSideOpenOrShort" ;
VAL_ 912 VehHorn_D_Stat 0 "Off" 1 "On" 2 "Outage" 3 "Faulty" ;
VAL_ 912 GearPrkLck_D_Stat 0 "OffNoPowerToLoad" 1 "OnPowerToLoad" 2 "FetNotControlled" 3 "FetOutputShortToGround" 4 "FetOutputShortToPower" 5 "FetOpenCircuit" 6 "FetLifeLimitReached" 7 "NotUsed_1" ;
VAL_ 912 HeatCoreSovRear_D_Stat 0 "OffNoPowerToLoad" 1 "OnPowerToLoad" 2 "FetNotControlled" 3 "FetOutputShortToGround" 4 "FetOutputShortToPower" 5 "FetOpenCircuit" 6 "FetLifeLimitReached" 7 "FetLowSideOpenOrShort" ;
VAL_ 912 OraZone2_D_Stat 0 "Null" 1 "Off" 2 "On" 3 "NotUsed" ;
VAL_ 912 BattTracClntVlv_D_Stat 0 "OffNoPowerToLoad" 1 "OnPowerToLoad" 2 "FetNotControlled" 3 "FetOutputShortToGround" 4 "FetOutputShortToPower" 5 "FetOpenCircuit" 6 "FetLifeLimitReached" 7 "FetLowSideOpenOrShort" ;
VAL_ 912 GearPrkMtr_D_Stat 0 "OffNoPowerToLoad" 1 "OnPowerToLoad" 2 "FetNotControlled" 3 "FetOutputShortToGround" 4 "FetOutputShortToPower" 5 "FetOpenCircuit" 6 "FetLifeLimitReached" 7 "NotUsed_1" ;
VAL_ 912 OraZone4_D_Stat 0 "Null" 1 "Off" 2 "On" 3 "NotUsed" ;
VAL_ 912 PwBus07_D_Res 0 "Null" 1 "Success" 2 "Pending" 3 "Rejected" 4 "Interrupted" 5 "InProgress" 6 "Failed" 7 "Faulty" ;
VAL_ 912 PwBus06_D_Res 0 "Null" 1 "Success" 2 "Pending" 3 "Rejected" 4 "Interrupted" 5 "InProgress" 6 "Failed" 7 "Faulty" ;
VAL_ 912 OraZone5_D_Stat 0 "Null" 1 "Off" 2 "On" 3 "NotUsed" ;
VAL_ 912 PwBus09_D_Res 0 "Null" 1 "Success" 2 "Pending" 3 "Rejected" 4 "Interrupted" 5 "InProgress" 6 "Failed" 7 "Faulty" ;
VAL_ 912 PwBus08_D_Res 0 "Null" 1 "Success" 2 "Pending" 3 "Rejected" 4 "Interrupted" 5 "InProgress" 6 "Failed" 7 "Faulty" ;
VAL_ 912 OraZone6_D_Stat 0 "Null" 1 "Off" 2 "On" 3 "NotUsed" ;
VAL_ 919 VehArrv_B_Stat 0 "No" 1 "Yes" ;
VAL_ 919 VehArrvSoon_B_Stat 0 "No" 1 "Yes" ;
VAL_ 919 CabnRdyToGo_B_Stat 0 "False" 1 "True" ;
VAL_ 919 ApnlGoButtnEnbl_B_Rq 0 "Disable" 1 "Enable" ;
VAL_ 919 ApnlExitNotice_B_Rq 0 "No" 1 "Yes" ;
VAL_ 919 ApnlLinger_B_Stat 0 "No" 1 "Yes" ;
VAL_ 919 ApnlLingerTExcd_B_Stat 0 "No" 1 "Yes" ;
VAL_ 919 VehTvf_D_Stat 0 "Unassigned" 1 "DrivingToPickupEmpty" 2 "DrivingToPickupOccupied" 3 "DrivingToDropOff" 4 "DrivingToLogistics" 5 "DrivingToBackup" 6 "OnboardingSingle" 7 "OnboardingMultiple" 8 "OnboardingOccupiedToSta" 9 "OffboardingSingle" 10 "OffboardingMultiple" 11 "OffboardingAndOnboarding" 12 "AtLogistics" 13 "ApproachingPickupUnoccup" 14 "OnboardingAuthenticated" 15 "InitDriveOccupied" 16 "ApproachingDropoff" 17 "ApproachingPickupOccupied" 18 "GoodsLoading" 19 "GoodsUnloading" 20 "GoodsLoadAuthenticated" 21 "GoodsUnloadAuthenticated" 22 "NotUsed_1" 23 "NotUsed_2" 24 "NotUsed_3" 25 "NotUsed_4" 26 "NotUsed_5" 27 "NotUsed_6" 28 "NotUsed_7" 29 "NotUsed_8" 30 "NotUsed_9" 31 "NotUsed_10" 32 "NotUsed_11" 33 "NotUsed_12" 34 "NotUsed_13" 35 "NotUsed_14" 36 "NotUsed_15" 37 "NotUsed_16" 38 "NotUsed_17" 39 "NotUsed_18" 40 "NotUsed_19" 41 "NotUsed_20" 42 "NotUsed_21" 43 "NotUsed_22" 44 "NotUsed_23" 45 "NotUsed_24" 46 "NotUsed_25" 47 "NotUsed_26" 48 "NotUsed_27" 49 "NotUsed_28" 50 "NotUsed_29" 51 "NotUsed_30" 52 "NotUsed_31" 53 "NotUsed_32" 54 "NotUsed_33" 55 "NotUsed_34" 56 "NotUsed_35" 57 "NotUsed_36" 58 "NotUsed_37" 59 "NotUsed_38" 60 "NotUsed_39" 61 "NotUsed_40" 62 "NotUsed_41" 63 "NotUsed_42" 64 "NotUsed_43" 65 "NotUsed_44" 66 "NotUsed_45" 67 "NotUsed_46" 68 "NotUsed_47" 69 "NotUsed_48" 70 "NotUsed_49" 71 "NotUsed_50" 72 "NotUsed_51" 73 "NotUsed_52" 74 "NotUsed_53" 75 "NotUsed_54" 76 "NotUsed_55" 77 "NotUsed_56" 78 "NotUsed_57" 79 "NotUsed_58" 80 "NotUsed_59" 81 "NotUsed_60" 82 "NotUsed_61" 83 "NotUsed_62" 84 "NotUsed_63" 85 "NotUsed_64" 86 "NotUsed_65" 87 "NotUsed_66" 88 "NotUsed_67" 89 "NotUsed_68" 90 "NotUsed_69" 91 "NotUsed_70" 92 "NotUsed_71" 93 "NotUsed_72" 94 "NotUsed_73" 95 "NotUsed_74" 96 "NotUsed_75" 97 "NotUsed_76" 98 "NotUsed_77" 99 "NotUsed_78" 100 "NotUsed_79" 101 "NotUsed_80" 102 "NotUsed_81" 103 "NotUsed_82" 104 "NotUsed_83" 105 "NotUsed_84" 106 "NotUsed_85" 107 "NotUsed_86" 108 "NotUsed_87" 109 "NotUsed_88" 110 "NotUsed_89" 111 "NotUsed_90" 112 "NotUsed_91" 113 "NotUsed_92" 114 "NotUsed_93" 115 "NotUsed_94" 116 "NotUsed_95" 117 "NotUsed_96" 118 "NotUsed_97" 119 "NotUsed_98" 120 "NotUsed_99" 121 "NotUsed_100" 122 "NotUsed_101" 123 "NotUsed_102" 124 "NotUsed_103" 125 "NotUsed_104" 126 "NotUsed_105" 127 "NotUsed_106" 128 "NotUsed_107" 129 "NotUsed_108" 130 "NotUsed_109" 131 "NotUsed_110" 132 "NotUsed_111" 133 "NotUsed_112" 134 "NotUsed_113" 135 "NotUsed_114" 136 "NotUsed_115" 137 "NotUsed_116" 138 "NotUsed_117" 139 "NotUsed_118" 140 "NotUsed_119" 141 "NotUsed_120" 142 "NotUsed_121" 143 "NotUsed_122" 144 "NotUsed_123" 145 "NotUsed_124" 146 "NotUsed_125" 147 "NotUsed_126" 148 "NotUsed_127" 149 "NotUsed_128" 150 "NotUsed_129" 151 "NotUsed_130" 152 "NotUsed_131" 153 "NotUsed_132" 154 "NotUsed_133" 155 "NotUsed_134" 156 "NotUsed_135" 157 "NotUsed_136" 158 "NotUsed_137" 159 "NotUsed_138" 160 "NotUsed_139" 161 "NotUsed_140" 162 "NotUsed_141" 163 "NotUsed_142" 164 "NotUsed_143" 165 "NotUsed_144" 166 "NotUsed_145" 167 "NotUsed_146" 168 "NotUsed_147" 169 "NotUsed_148" 170 "NotUsed_149" 171 "NotUsed_150" 172 "NotUsed_151" 173 "NotUsed_152" 174 "NotUsed_153" 175 "NotUsed_154" 176 "NotUsed_155" 177 "NotUsed_156" 178 "NotUsed_157" 179 "NotUsed_158" 180 "NotUsed_159" 181 "NotUsed_160" 182 "NotUsed_161" 183 "NotUsed_162" 184 "NotUsed_163" 185 "NotUsed_164" 186 "NotUsed_165" 187 "NotUsed_166" 188 "NotUsed_167" 189 "NotUsed_168" 190 "NotUsed_169" 191 "NotUsed_170" 192 "NotUsed_171" 193 "NotUsed_172" 194 "NotUsed_173" 195 "NotUsed_174" 196 "NotUsed_175" 197 "NotUsed_176" 198 "NotUsed_177" 199 "NotUsed_178" 200 "NotUsed_179" 201 "NotUsed_180" 202 "NotUsed_181" 203 "NotUsed_182" 204 "NotUsed_183" 205 "NotUsed_184" 206 "NotUsed_185" 207 "NotUsed_186" 208 "NotUsed_187" 209 "NotUsed_188" 210 "NotUsed_189" 211 "NotUsed_190" 212 "NotUsed_191" 213 "NotUsed_192" 214 "NotUsed_193" 215 "NotUsed_194" 216 "NotUsed_195" 217 "NotUsed_196" 218 "NotUsed_197" 219 "NotUsed_198" 220 "NotUsed_199" 221 "NotUsed_200" 222 "NotUsed_201" 223 "NotUsed_202" 224 "NotUsed_203" 225 "NotUsed_204" 226 "NotUsed_205" 227 "NotUsed_206" 228 "NotUsed_207" 229 "NotUsed_208" 230 "NotUsed_209" 231 "NotUsed_210" 232 "NotUsed_211" 233 "NotUsed_212" 234 "NotUsed_213" 235 "NotUsed_214" 236 "NotUsed_215" 237 "NotUsed_216" 238 "NotUsed_217" 239 "NotUsed_218" 240 "NotUsed_219" 241 "NotUsed_220" 242 "NotUsed_221" 243 "NotUsed_222" 244 "NotUsed_223" 245 "NotUsed_224" 246 "NotUsed_225" 247 "NotUsed_226" 248 "NotUsed_227" 249 "NotUsed_228" 250 "NotUsed_229" 251 "NotUsed_230" 252 "NotUsed_231" 253 "NotUsed_232" 254 "NotUsed_233" 255 "NotUsed_234" ;
VAL_ 919 VehCurbside_D_Stat 0 "Null" 1 "Left" 2 "Right" 3 "Both" 4 "Neither" 5 "NotUsed_1" 6 "NotUsed_2" 7 "NotUsed_3" ;
VAL_ 919 CabnClimtPurge_D_Rq 0 "NoRequest" 1 "Request" 2 "Cancel" 3 "Faulty" ;
VAL_ 919 Row2PsngrPrsnc_D_Actl2 0 "Fault" 1 "Occupied" 2 "Empty" 3 "Unknown" ;
VAL_ 919 Row2DrvPrsnc_D_Actl2 0 "Fault" 1 "Occupied" 2 "Empty" 3 "Unknown" ;
VAL_ 925 TripBattULoE_Pc_Dsply 1022 "NoDataExists" 1023 "Faulty" ;
VAL_ 925 TripClimE_Pc_Dsply 1022 "NoDataExists" 1023 "Faulty" ;
VAL_ 925 TripExtFctrE_Pc_Dsply 1022 "NoDataExists" 1023 "Faulty" ;
VAL_ 925 TripSumDrvE_Pc_Dsply 1022 "NoDataExists" 1023 "Faulty" ;
VAL_ 925 VehElEffTrip_No_Dsply 126 "NoDataExists" 127 "Faulty" ;
VAL_ 929 BalrChimeLeft_D_Rq 0 "Off" 1 "Normal" 2 "Soft" 3 "NotUsed" ;
VAL_ 929 DrLckActv_B_RqBalrl 0 "Null" 1 "Active" ;
VAL_ 929 CamraRearOn_B_RqBalrl 0 "Inactive" 1 "Active" ;
VAL_ 929 BalrMdeSelLeft_B_Stat 0 "Disable" 1 "Enable" ;
VAL_ 929 BalrLeft_D_Stat 0 "Off" 1 "On" 2 "Disabled" 3 "Inhibited" ;
VAL_ 929 BalrLckLeft_B_Stat 0 "Disable" 1 "Enable" ;
VAL_ 929 BalrWndwLeft_B_Stat 0 "Disable" 1 "Enable" ;
VAL_ 929 BalrSnsLeft_D_Falt 0 "Clear" 1 "Blocked" 2 "SystemFailure" 3 "Invalid" ;
VAL_ 929 BalrMdeLeft_D_Stat 0 "Low" 1 "Medium" 2 "High" 3 "NotUsed" ;
VAL_ 929 WndwPsngrRear_D_RqBalrl 0 "NoRequest" 1 "AutoUp" 2 "Stop" 3 "NotUsed" ;
VAL_ 929 WndwPsngr_D_RqBalrl 0 "NoRequest" 1 "AutoUp" 2 "Stop" 3 "NotUsed" ;
VAL_ 929 WndwDrvRear_D_RqBalrl 0 "NoRequest" 1 "AutoUp" 2 "Stop" 3 "NotUsed" ;
VAL_ 929 WndwDrv_D_RqBalrl 0 "NoRequest" 1 "AutoUp" 2 "Stop" 3 "NotUsed" ;
VAL_ 930 BalrChimeRight_D_Rq 0 "Off" 1 "Normal" 2 "Soft" 3 "NotUsed" ;
VAL_ 930 DrLckActv_B_RqBalrr 0 "Null" 1 "Active" ;
VAL_ 930 CamraRearOn_B_RqBalrr 0 "Inactive" 1 "Active" ;
VAL_ 930 BalrMdeSelRight_B_Stat 0 "Disable" 1 "Enable" ;
VAL_ 930 BalrRight_D_Stat 0 "Off" 1 "On" 2 "Disabled" 3 "Inhibited" ;
VAL_ 930 BalrLckRight_B_Stat 0 "Disable" 1 "Enable" ;
VAL_ 930 BalrWndwRight_B_Stat 0 "Disable" 1 "Enable" ;
VAL_ 930 BalrSnsRight_D_Falt 0 "Clear" 1 "Blocked" 2 "SystemFailure" 3 "Invalid" ;
VAL_ 930 BalrMdeRight_D_Stat 0 "Low" 1 "Medium" 2 "High" 3 "NotUsed" ;
VAL_ 930 WndwPsngrRear_D_RqBalrr 0 "NoRequest" 1 "AutoUp" 2 "Stop" 3 "NotUsed" ;
VAL_ 930 WndwPsngr_D_RqBalrr 0 "NoRequest" 1 "AutoUp" 2 "Stop" 3 "NotUsed" ;
VAL_ 930 WndwDrvRear_D_RqBalrr 0 "NoRequest" 1 "AutoUp" 2 "Stop" 3 "NotUsed" ;
VAL_ 930 WndwDrv_D_RqBalrr 0 "NoRequest" 1 "AutoUp" 2 "Stop" 3 "NotUsed" ;
VAL_ 931 EngStrt_B_Rq 0 "NoRequest" 1 "Request" ;
VAL_ 931 DrvInCtl_B_Stat 0 "No" 1 "Yes" ;
VAL_ 931 IgnPreOffActv_B_Stat 0 "Inactive" 1 "Active" ;
VAL_ 931 CrnkInhbt_B_Stat 0 "NoInhibit" 1 "Inhibit" ;
VAL_ 931 VehOnSrc_D_Stat 0 "Off" 1 "Manual" 2 "RemoteStart" 3 "RemoteParkAssist" 4 "OverTheAir" 5 "StolenVehicleInhibit" 6 "FleetVehicleInhibit" 7 "SecureIdle" 8 "AutonomousVehicle" 9 "EsclRssd" 10 "NotUsed_6" 11 "NotUsed_7" 12 "NotUsed_8" 13 "NotUsed_9" 14 "NotUsed_10" 15 "NotUsed_11" ;
VAL_ 931 PtWakeReas_D_Stat 0 "Null" 1 "MotiveStart" 2 "NonMotiveStart" 3 "EarlyWake" 4 "DoorAjar" 5 "ThirdPartyWakeup" 6 "ElapsedTime" 7 "NotUsed_1" 8 "NotUsed_2" 9 "NotUsed_3" 10 "NotUsed_4" 11 "NotUsed_5" 12 "NotUsed_6" 13 "NotUsed_7" 14 "NotUsed_8" 15 "NotUsed_9" ;
VAL_ 931 EngStrtActv_B_Stat 0 "Inactive" 1 "Active" ;
VAL_ 932 VehOnSrc2_D_Stat 0 "Off" 1 "Manual" 2 "RemoteStart" 3 "RemoteParkAssist" 4 "OverTheAir" 5 "StolenVehicleInhibit" 6 "FleetVehicleInhibit" 7 "SecureIdle" 8 "AutonomousVehicle" 9 "EsclRssd" 10 "NotUsed_6" 11 "NotUsed_7" 12 "NotUsed_8" 13 "NotUsed_9" 14 "NotUsed_10" 15 "NotUsed_11" ;
VAL_ 932 ChildLck_D_Dsply 0 "CHILD_LOCK" 1 "CHILD_UNLOCK" 2 "ERROR" 3 "NOT_SUPPORTED" ;
VAL_ 932 VehInhbtMde_D_Stat 0 "Unconfigured" 1 "NoOtaSupport" 2 "SyncOta" 3 "Iviota" 4 "FullVehicleOta" 5 "NotUsed_1" 6 "NotUsed_2" 7 "NotUsed_3" ;
VAL_ 932 VehOnCtl_D_Stat 0 "Null" 1 "Off" 2 "On" 3 "NotUsed" ;
VAL_ 932 VehStrtInhbt_D_Stat 0 "NoInhibit" 1 "Inhibit" ;
VAL_ 932 RmtCtlBattMntr_B_Falt 0 "No" 1 "Yes" ;
VAL_ 934 CtaLeftBrkDecel_B_Rq 0 "Disable" 1 "Enable" ;
VAL_ 934 CtaAlrtLeft_D_Stat 0 "Off" 1 "On" ;
VAL_ 934 SodAlrtLeft_D_Stat 0 "Off" 1 "On" 2 "Flash" 3 "Bulb_Proveout" ;
VAL_ 934 SodSnsLeft_D_Stat 0 "Clear" 1 "Blocked" 2 "System_Failure" 3 "Second_Warning_Audio" ;
VAL_ 934 SodLeft_D_Stat 0 "Off" 1 "Trailer_Tow_Off" 2 "On" 3 "Disabled" 4 "Invalid" 5 "NotUsed_1" 6 "NotUsed_2" 7 "NotUsed_3" ;
VAL_ 934 CtaLeft_D_Stat 0 "Off" 1 "Trailer_Tow_Off" 2 "On" 3 "Disabled" 4 "Invalid" 5 "NotUsed_1" 6 "NotUsed_2" 7 "NotUsed_3" ;
VAL_ 934 SodDetctLeft_D_Stat 0 "AlertOff_FlashOff_SensrClr" 1 "Alert_On" 2 "Flash_On" 3 "Sensor_Fault" 4 "Sensor_Blocked" ;
VAL_ 934 CtaSnsLeft_D_Stat 0 "Clear" 1 "Blocked" 2 "System_Failure" 3 "Invalid" ;
VAL_ 934 CtaAlrtLeft2_D_Stat 0 "Off" 1 "AlertZone1" 2 "AlertZone2" 3 "AlertZone3" 4 "AlertZone4" 5 "NotUsed1" 6 "NotUsed2" 7 "NotUsed3" ;
VAL_ 934 CtaLeftBrkEnbl_B_Rq 0 "Disable" 1 "Enable" ;
VAL_ 934 CtaBrkLeftMsgTxt_B_Rq 0 "Disable" 1 "Enable" ;
VAL_ 934 BttLeft_D_Stat 0 "NotDetermined" 1 "Connected" 2 "Pending" 3 "NotConnected" 4 "OffTemp" 5 "Off" 6 "Disabled" 7 "BTT5GFault" ;
VAL_ 934 BttLeft_D_RqDrv 0 "Null" 1 "NoRequest" 2 "Request" 3 "NotUsed" ;
VAL_ 935 CtaRightBrkDecel_B_Rq 0 "Disable" 1 "Enable" ;
VAL_ 935 CtaAlrtRight_D_Stat 0 "Off" 1 "On" ;
VAL_ 935 SodAlrtRight_D_Stat 0 "Off" 1 "On" 2 "Flash" 3 "Bulb_Proveout" ;
VAL_ 935 SodSnsRight_D_Stat 0 "Clear" 1 "Blocked" 2 "System_Failure" 3 "Second_Warning_Audio" ;
VAL_ 935 SodRight_D_Stat 0 "Off" 1 "Trailer_Tow_Off" 2 "On" 3 "Disabled" 4 "Invalid" 5 "NotUsed_1" 6 "NotUsed_2" 7 "NotUsed_3" ;
VAL_ 935 CtaRight_D_Stat 0 "Off" 1 "Trailer_Tow_Off" 2 "On" 3 "Disabled" 4 "Invalid" 5 "NotUsed_1" 6 "NotUsed_2" 7 "NotUsed_3" ;
VAL_ 935 SodDetctRight_D_Stat 0 "AlertOff_FlashOff_SensrClr" 1 "Alert_On" 2 "Flash_On" 3 "Sensor_Fault" 4 "Sensor_Blocked" ;
VAL_ 935 CtaSnsRight_D_Stat 0 "Clear" 1 "Blocked" 2 "System_Failure" 3 "Invalid" ;
VAL_ 935 CtaAlrtRight2_D_Stat 0 "Off" 1 "AlertZone1" 2 "AlertZone2" 3 "AlertZone3" 4 "AlertZone4" 5 "NotUsed1" 6 "NotUsed2" 7 "NotUsed3" ;
VAL_ 935 CtaRightBrkEnbl_B_Rq 0 "Disable" 1 "Enable" ;
VAL_ 935 CtaBrkRightMsgTxt_B_Rq 0 "Disable" 1 "Enable" ;
VAL_ 935 BttRight_D_Stat 0 "NotDetermined" 1 "Connected" 2 "Pending" 3 "NotConnected" 4 "OffTemp" 5 "Off" 6 "Disabled" 7 "BTT5GFault" ;
VAL_ 935 BttRight_D_RqDrv 0 "Null" 1 "NoRequest" 2 "Request" 3 "NotUsed" ;
VAL_ 936 ApaTrgtDist_D_Stat 0 "Off" 1 "Step1" 2 "Step2" 3 "Step3" 4 "Step4" 5 "Step5" 6 "Step6" 7 "Step7" 8 "Step8" 9 "Step9" 10 "Step10" 11 "Step11" 12 "Step12" 13 "Step13" 14 "Step14" 15 "Step15" ;
VAL_ 936 ApaMsgTxt_D_Rq 0 "Null" 1 "None" 2 "WheelSlip" 3 "TcsDisabled" 4 "SpeedLimitExceeded" 5 "HighInclination" 6 "BrakingActive" 7 "SteeringInteraction" 8 "WrongDirection" 9 "AccelPedalInactive" 10 "TrailerFeatureNotAvailable" 11 "ReleaseEpb" 12 "NotUsed_3" 13 "NotUsed_4" 14 "NotUsed_5" 15 "NotUsed_6" ;
VAL_ 936 ExtSteeringAngleReq2 32766 "Unknown" 32767 "Invalid" ;
VAL_ 936 EPASExtAngleStatReq 0 "NoRequest" 1 "Request" ;
VAL_ 936 ApaActvSide2_D_Stat 0 "Null" 1 "Left" 2 "Right" 3 "NoSide" ;
VAL_ 936 ApaAcsy_D_RqDrv 0 "Null" 1 "NoRequest" 2 "SelectSide" 3 "PressApaButton" 4 "CheckForObject" 5 "SelectSideLeft" 6 "SelectSideRight" 7 "CloseDoor" ;
VAL_ 936 ApaChime_D_Rq 0 "No_Chime" 1 "Spot_Found_Chime" 2 "Spot_Ready_Chime" 3 "Stop_Now_Chime" 4 "Finish_Chime" 5 "Warning_Chime" 6 "NotUsed1" 7 "NotUsed2" ;
VAL_ 936 ApaScan_D_Stat 0 "Null" 1 "NoParkSlot" 2 "ParkSlotFound" 3 "ParkSlotReady" ;
VAL_ 936 ApaLongCtl_D_RqDrv 0 "Null" 1 "NoRequest" 2 "Stop" 3 "DriveForward" 4 "DriveBackward" 5 "ReleaseBrake" 6 "NotUsed2" 7 "NotUsed3" ;
VAL_ 936 ApaGearShif_D_RqDrv 0 "Null" 1 "NoRequest" 2 "ShiftToR" 3 "ShiftToD" 4 "ShiftToN" 5 "ShiftToP" 6 "NotUsed1" 7 "NotUSed2" ;
VAL_ 936 ApaSteScanMde_D_Stat 0 "Null" 1 "NotScanning" 2 "Scanning" 3 "Steering" ;
VAL_ 936 ApaSelSapp_D_Stat 0 "Null" 1 "Selectable" 2 "NotSelectable" 3 "NotConfigured" ;
VAL_ 936 ApaSelPpa_D_Stat 0 "Null" 1 "Selectable" 2 "NotSelectable" 3 "NotConfigured" ;
VAL_ 936 ApaSelPoa_D_Stat 0 "Null" 1 "Selectable" 2 "NotSelectable" 3 "NotConfigured" ;
VAL_ 936 ApaButtnPrssd_B_Stat 0 "Not_Pressed" 1 "Pressed" ;
VAL_ 936 ApaSys_D_Stat 0 "Null" 1 "Off" 2 "On" 3 "Overspeed" 4 "ApaCancelled" 5 "NotAccessible" 6 "Finished" 7 "Faulty" ;
VAL_ 936 ApaSteWhl_D_RqDrv 0 "Null" 1 "NoRequest" 2 "RemoveHands" 3 "TakeControl" ;
VAL_ 938 FpaChime_D_Rq 0 "No_Chime" 1 "Zone1_Chime" 2 "Zone2_Chime" 3 "Zone3_Chime" 4 "Zone4_Chime" 5 "Zone5_Chime" 6 "Zone6_Chime" 7 "Zone7_Chime" 8 "Zone8_Chime" 9 "Zone9_Chime" 10 "Zone10_Chime" 11 "Zone11_Chime" 12 "Zone12_Chime" 13 "Zone13_Chime" 14 "Zone14_Chime" 15 "Zone15_Chime" ;
VAL_ 938 RpaChime_D_Rq 0 "No_Chime" 1 "Zone1_Chime" 2 "Zone2_Chime" 3 "Zone3_Chime" 4 "Zone4_Chime" 5 "Zone5_Chime" 6 "Zone6_Chime" 7 "Zone7_Chime" 8 "Zone8_Chime" 9 "Zone9_Chime" 10 "Zone10_Chime" 11 "Zone11_Chime" 12 "Zone12_Chime" 13 "Zone13_Chime" 14 "Zone14_Chime" 15 "Zone15_Chime" ;
VAL_ 938 PrkAidSwtch_B_Stat 0 "Not_Pressed" 1 "Pressed" ;
VAL_ 938 ApaMde_D_Avail 0 "Null" 1 "None" 2 "SAPP_PPA" 3 "SAPP_PPA_POA" 4 "SAPP" 5 "PPA" 6 "POA" 7 "SAPP_POA" 8 "PPA_POA" 9 "NotUsed1" 10 "NotUsed2" 11 "NotUsed3" 12 "NotUsed4" 13 "NotUsed5" 14 "NotUsed6" 15 "NotUsed7" ;
VAL_ 938 ApaActvSd_D_Actl 0 "Null" 1 "No_Side" 2 "Passenger_Side" 3 "Dirver_Side" ;
VAL_ 938 PrkAidAudioMute_B_Rq 0 "Disable" 1 "Enable" ;
VAL_ 938 PrkAidMsgTxt_D_Rq 0 "All_Park_Sensors_Off" 1 "R_Snsrs_On_F_Snsrs_Off" 2 "R_Snsrs_Off_F_Snsrs_On" 3 "Reset_Message_Warn" 4 "NotUsed2" 5 "R_Snsrs_On_F_Snsrs_On" 6 "Park_Sys_Alternate_Mode" 7 "NotUsed3" 8 "R_Sns_Trlr_F_Sns_Blk" 9 "Fail_Mode_with_Chime" 10 "Fail_Mode_no_Chime" 11 "Not_Avail_Trlr_attchd" 12 "R_Sns_Inactive_Trlr_atch" 13 "R_Sns_Blk_F_Sns_ON" 14 "R_Sns_ON_F_Sns_Blk" 15 "All_Sns_Blk" ;
VAL_ 938 PrkBrkEl_B_RqFap 0 "No" 1 "Yes" ;
VAL_ 938 ApaMde_D_Stat 0 "Null" 1 "Off" 2 "SAPP" 3 "PPA" 4 "POA" 5 "ParkIn" 6 "RePA" 7 "NotUsed" ;
VAL_ 938 PrkAidSnsFlCrnr_D_Stat 0 "Off" 1 "Zone_1" 2 "Zone_2" 3 "Zone_3" 4 "Zone_4" 5 "Zone_5" 6 "Zone_6" 7 "Zone_7" 8 "Zone_8" 9 "Zone_9" 10 "Zone_10" 11 "Zone_11" 12 "Zone_12" 13 "Zone_13" 14 "Zone_14" 15 "Zone_15" ;
VAL_ 938 PrkAidSnsFlCntr_D_Stat 0 "Off" 1 "Zone_1" 2 "Zone_2" 3 "Zone_3" 4 "Zone_4" 5 "Zone_5" 6 "Zone_6" 7 "Zone_7" 8 "Zone_8" 9 "Zone_9" 10 "Zone_10" 11 "Zone_11" 12 "Zone_12" 13 "Zone_13" 14 "Zone_14" 15 "Zone_15" ;
VAL_ 938 PrkAidSnsFrCntr_D_Stat 0 "Off" 1 "Zone_1" 2 "Zone_2" 3 "Zone_3" 4 "Zone_4" 5 "Zone_5" 6 "Zone_6" 7 "Zone_7" 8 "Zone_8" 9 "Zone_9" 10 "Zone_10" 11 "Zone_11" 12 "Zone_12" 13 "Zone_13" 14 "Zone_14" 15 "Zone_15" ;
VAL_ 938 PrkAidSnsFrCrnr_D_Stat 0 "Off" 1 "Zone_1" 2 "Zone_2" 3 "Zone_3" 4 "Zone_4" 5 "Zone_5" 6 "Zone_6" 7 "Zone_7" 8 "Zone_8" 9 "Zone_9" 10 "Zone_10" 11 "Zone_11" 12 "Zone_12" 13 "Zone_13" 14 "Zone_14" 15 "Zone_15" ;
VAL_ 938 SidePrkSnsL2_D_Stat 0 "Off" 1 "Zone1" 2 "Zone2" 3 "Zone3" 4 "Zone4" 5 "Zone5" 6 "Zone6" 7 "Zone7" 8 "Zone8" 9 "Zone9" 10 "Zone10" 11 "Zone11" 12 "Zone12" 13 "NoObjectInSector" 14 "NotFullyScannedYet" 15 "NotUsed" ;
VAL_ 938 SidePrkSnsL1_D_Stat 0 "Off" 1 "Zone1" 2 "Zone2" 3 "Zone3" 4 "Zone4" 5 "Zone5" 6 "Zone6" 7 "Zone7" 8 "Zone8" 9 "Zone9" 10 "Zone10" 11 "Zone11" 12 "Zone12" 13 "NoObjectInSector" 14 "NotFullyScannedYet" 15 "NotUsed" ;
VAL_ 938 SidePrkSnsR2_D_Stat 0 "Off" 1 "Zone1" 2 "Zone2" 3 "Zone3" 4 "Zone4" 5 "Zone5" 6 "Zone6" 7 "Zone7" 8 "Zone8" 9 "Zone9" 10 "Zone10" 11 "Zone11" 12 "Zone12" 13 "NoObjectInSector" 14 "NotFullyScannedYet" 15 "NotUsed" ;
VAL_ 938 SidePrkSnsR1_D_Stat 0 "Off" 1 "Zone1" 2 "Zone2" 3 "Zone3" 4 "Zone4" 5 "Zone5" 6 "Zone6" 7 "Zone7" 8 "Zone8" 9 "Zone9" 10 "Zone10" 11 "Zone11" 12 "Zone12" 13 "NoObjectInSector" 14 "NotFullyScannedYet" 15 "NotUsed" ;
VAL_ 939 ApaLongCtrlEnbl_D_Rq 0 "Disable" 1 "Enable" ;
VAL_ 939 PrkAidFront_D_Stat 0 "Disabled" 1 "Enabled" 2 "Unused" 3 "Faulted" ;
VAL_ 939 PrkAidChime_D_Stat 0 "Off" 1 "On" 2 "No_Data_Exists" 3 "Fault" ;
VAL_ 939 PrkAid_D_Falt 0 "No_Fault" 1 "ECU_Fault" 2 "Speaker_Fault" 3 "Failure_Rear_Sensors" 4 "No_Data_Exists" 5 "Failure_Front_PSM_Sensors" 6 "NotUsed1" 7 "NotUsed2" ;
VAL_ 939 PrkAidSnsRlCrnr_D_Stat 0 "Off" 1 "Zone_1" 2 "Zone_2" 3 "Zone_3" 4 "Zone_4" 5 "Zone_5" 6 "Zone_6" 7 "Zone_7" 8 "Zone_8" 9 "Zone_9" 10 "Zone_10" 11 "Zone_11" 12 "Zone_12" 13 "Zone_13" 14 "Zone_14" 15 "Zone_15" ;
VAL_ 939 PrkAidSnsRlCntr_D_Stat 0 "Off" 1 "Zone_1" 2 "Zone_2" 3 "Zone_3" 4 "Zone_4" 5 "Zone_5" 6 "Zone_6" 7 "Zone_7" 8 "Zone_8" 9 "Zone_9" 10 "Zone_10" 11 "Zone_11" 12 "Zone_12" 13 "Zone_13" 14 "Zone_14" 15 "Zone_15" ;
VAL_ 939 PrkAidSnsRrCntr_D_Stat 0 "Off" 1 "Zone_1" 2 "Zone_2" 3 "Zone_3" 4 "Zone_4" 5 "Zone_5" 6 "Zone_6" 7 "Zone_7" 8 "Zone_8" 9 "Zone_9" 10 "Zone_10" 11 "Zone_11" 12 "Zone_12" 13 "Zone_13" 14 "Zone_14" 15 "Zone_15" ;
VAL_ 939 ResPrkAidSnsRlSide_D_Stat 0 "Off" 1 "Zone_1" 2 "Zone_2" 3 "Zone_3" 4 "Zone_4" 5 "Zone_5" 6 "Zone_6" 7 "Zone_7" 8 "Zone_8" 9 "Zone_9" 10 "Zone_10" 11 "Zone_11" 12 "Zone_12" 13 "Zone_13" 14 "Zone_14" 15 "Zone_15" ;
VAL_ 939 ResPrkAidSnsRrSide_D_Stat 0 "Off" 1 "Zone_1" 2 "Zone_2" 3 "Zone_3" 4 "Zone_4" 5 "Zone_5" 6 "Zone_6" 7 "Zone_7" 8 "Zone_8" 9 "Zone_9" 10 "Zone_10" 11 "Zone_11" 12 "Zone_12" 13 "Zone_13" 14 "Zone_14" 15 "Zone_15" ;
VAL_ 939 PrkAidSnsRrCrnr_D_Stat 0 "Off" 1 "Zone_1" 2 "Zone_2" 3 "Zone_3" 4 "Zone_4" 5 "Zone_5" 6 "Zone_6" 7 "Zone_7" 8 "Zone_8" 9 "Zone_9" 10 "Zone_10" 11 "Zone_11" 12 "Zone_12" 13 "Zone_13" 14 "Zone_14" 15 "Zone_15" ;
VAL_ 939 PrkAidLamp_D_Rq 0 "Off" 1 "On" 2 "Flash" 3 "Not_Used" ;
VAL_ 939 SidePrkSnsL3_D_Stat 0 "Off" 1 "Zone1" 2 "Zone2" 3 "Zone3" 4 "Zone4" 5 "Zone5" 6 "Zone6" 7 "Zone7" 8 "Zone8" 9 "Zone9" 10 "Zone10" 11 "Zone11" 12 "Zone12" 13 "NoObjectInSector" 14 "NotFullyScannedYet" 15 "NotUsed" ;
VAL_ 939 PrkAidRear_D_Stat 0 "Disabled" 1 "Enabled" 2 "Unused" 3 "Faulted" ;
VAL_ 939 SidePrkSnsL4_D_Stat 0 "Off" 1 "Zone1" 2 "Zone2" 3 "Zone3" 4 "Zone4" 5 "Zone5" 6 "Zone6" 7 "Zone7" 8 "Zone8" 9 "Zone9" 10 "Zone10" 11 "Zone11" 12 "Zone12" 13 "NoObjectInSector" 14 "NotFullyScannedYet" 15 "NotUsed" ;
VAL_ 939 SidePrkSnsR3_D_Stat 0 "Off" 1 "Zone1" 2 "Zone2" 3 "Zone3" 4 "Zone4" 5 "Zone5" 6 "Zone6" 7 "Zone7" 8 "Zone8" 9 "Zone9" 10 "Zone10" 11 "Zone11" 12 "Zone12" 13 "NoObjectInSector" 14 "NotFullyScannedYet" 15 "NotUsed" ;
VAL_ 939 DrTgateMde_D_Stat 0 "NotAvailable" 1 "Down" 2 "Up" 3 "NotUsed_1" ;
VAL_ 939 ApaBrk_D_Rq 0 "NoRequest" 1 "HighDecel" 2 "LowDecel" 3 "NotUsed" ;
VAL_ 939 SidePrkSnsR4_D_Stat 0 "Off" 1 "Zone1" 2 "Zone2" 3 "Zone3" 4 "Zone4" 5 "Zone5" 6 "Zone6" 7 "Zone7" 8 "Zone8" 9 "Zone9" 10 "Zone10" 11 "Zone11" 12 "Zone12" 13 "NoObjectInSector" 14 "NotFullyScannedYet" 15 "NotUsed" ;
VAL_ 942 ApaControlMode_D_Stat 0 "Inactive" 1 "Active" ;
VAL_ 942 PrkAidAcsyRear_D_Stat 0 "Null" 1 "Off" 2 "On" 3 "NotUsed" ;
VAL_ 942 PrkAidAcsyFront_D_Stat 0 "Null" 1 "Off" 2 "On" 3 "NotUsed" ;
VAL_ 942 PrkAidDrvDir_D_Stat 0 "DirectionNotKnown" 1 "NoMotion" 2 "ForwardPositive" 3 "BackwardPositive" 4 "ForwardNegative" 5 "BackwardNegative" 6 "NotUsed_1" 7 "NotUsed_2" ;
VAL_ 942 ApaParkInSel_B_Avail 0 "NotAvailable" 1 "Available" ;
VAL_ 942 ApaMsgTxt_D2_Stat 0 "None" 1 "WaitForSteering" 2 "ObstacleInPath" 3 "BrakeEvent" 4 "SpeedLimitExceeded" 5 "WrongDirection" 6 "SteeringInteraction" 7 "DoorOpen" 8 "HighInclination" 9 "WheelSlip" 10 "TcsDeactivated" 11 "TrailerAttached" 12 "SensorsBlocked" 13 "AcceleratorPedalInactive" 14 "TrailerFeatureNotAvailable" 15 "ReducedFunction" ;
VAL_ 942 ApaDynmcSlot_B_Stat 0 "Off" 1 "On" ;
VAL_ 942 ApaDisplayMode_D_Stat 0 "Off" 1 "Menu" 2 "FullScreen" 3 "NotUsed" ;
VAL_ 942 ApaSys_D2_Stat 0 "NormalOperation" 1 "Pause" 2 "Overspeed" 3 "NotAvailable" 4 "Cancelled" 5 "Finished" 6 "Faulty" 7 "BothSidesSelectable" 8 "LeftSideSelectable" 9 "RightSideSelectable" 10 "NoSideSelectable" 11 "NotUsed_1" 12 "NotUsed_2" 13 "NotUsed_3" 14 "NotUsed_4" 15 "NotUsed_5" ;
VAL_ 942 ApaSlotTrgt_D_Stat 0 "None" 1 "Left1" 2 "Left2" 3 "Left3" 4 "Right1" 5 "Right2" 6 "Right3" 7 "Rear" 8 "Front" 9 "NotUsed_1" 10 "NotUsed_2" 11 "NotUsed_3" 12 "NotUsed_4" 13 "NotUsed_5" 14 "NotUsed_6" 15 "NotUsed_7" ;
VAL_ 942 ApaDrvRq1MsgTxt_D_Rq 0 "NoRequest" 1 "ShiftToR" 2 "ShiftToD" 3 "ShiftToN" 4 "ShiftToP" 5 "PressApaButton" 6 "ExitVehicle" 7 "NotUsed" ;
VAL_ 942 ApaSlotOption_B_Avail 0 "NotAvailable" 1 "Available" ;
VAL_ 942 ApaSlotAlrtSet_B_Stat 0 "Disable" 1 "Enable" ;
VAL_ 942 ApaSlotAlrt_B_Rq 0 "False" 1 "True" ;
VAL_ 942 ApaRmtFeatSel_B_Avail 0 "NotAvailable" 1 "Available" ;
VAL_ 942 ApaParkOutSel_B_Avail 0 "NotAvailable" 1 "Available" ;
VAL_ 942 PrkBrkElRleas_B_RqApa 0 "No" 1 "Yes" ;
VAL_ 942 ApaOffOptnSel_B_Avail 0 "NotAvailable" 1 "Available" ;
VAL_ 942 ApaDrvRq2MsgTxt_D_Rq 0 "NoRequest" 1 "Stop" 2 "DriveForward" 3 "DriveBackward" 4 "ReleaseBrake" 5 "ReleaseSteering" 6 "ReleaseEpb" 7 "TakeControl" 8 "CloseDoor" 9 "NotUsed_1" 10 "NotUsed_2" 11 "NotUsed_3" 12 "NotUsed_4" 13 "NotUsed_5" 14 "NotUsed_6" 15 "NotUsed_7" ;
VAL_ 945 PrkLckCtlMsgTxt_D2_Rq 0 "NoMessage" 1 "Message1" 2 "Message2" 3 "Message3" 4 "Message4" 5 "Message5" 6 "Message6" 7 "Message7" ;
VAL_ 945 PrkLckCtlLatch_B_Rq 0 "Off" 1 "On" ;
VAL_ 945 KeyOffMde_D_Actl 0 "Normal" 1 "Factory" 2 "Transport" 3 "Hibernate" 4 "CriticalBattery" 5 "NotUsed_1" 6 "NotUsed_2" 7 "NotUsed_3" 8 "NotUsed_4" 9 "NotUsed_5" 10 "NotUsed_6" 11 "NotUsed_7" 12 "NotUsed_8" 13 "NotUsed_9" 14 "NotUsed_10" 15 "NotUsed_11" ;
VAL_ 945 KeyPadCodeDgt2_D_Dsply 0 "EndofString" 1 "Button1_2or1" 2 "Button2" 3 "Button3_4or3" 4 "Button4" 5 "Button5_6or5" 6 "Button6" 7 "Button7_8or7" 8 "Button8" 9 "Button9_0or9" 10 "Button0" 11 "Button7_8and9_0" 12 "NotUsed_1" 13 "NotUsed_2" 14 "NotUsed_3" 15 "NotUsed_4" ;
VAL_ 945 KeyPadCodeDgt1_D_Dsply 0 "EndofString" 1 "Button1_2or1" 2 "Button2" 3 "Button3_4or3" 4 "Button4" 5 "Button5_6or5" 6 "Button6" 7 "Button7_8or7" 8 "Button8" 9 "Button9_0or9" 10 "Button0" 11 "Button7_8and9_0" 12 "NotUsed_1" 13 "NotUsed_2" 14 "NotUsed_3" 15 "NotUsed_4" ;
VAL_ 945 KeyPadCodeDgt4_D_Dsply 0 "EndofString" 1 "Button1_2or1" 2 "Button2" 3 "Button3_4or3" 4 "Button4" 5 "Button5_6or5" 6 "Button6" 7 "Button7_8or7" 8 "Button8" 9 "Button9_0or9" 10 "Button0" 11 "Button7_8and9_0" 12 "NotUsed_1" 13 "NotUsed_2" 14 "NotUsed_3" 15 "NotUsed_4" ;
VAL_ 945 KeyPadCodeDgt3_D_Dsply 0 "EndofString" 1 "Button1_2or1" 2 "Button2" 3 "Button3_4or3" 4 "Button4" 5 "Button5_6or5" 6 "Button6" 7 "Button7_8or7" 8 "Button8" 9 "Button9_0or9" 10 "Button0" 11 "Button7_8and9_0" 12 "NotUsed_1" 13 "NotUsed_2" 14 "NotUsed_3" 15 "NotUsed_4" ;
VAL_ 945 KeyPadCodeDgt6_D_Dsply 0 "EndofString" 1 "Button1_2or1" 2 "Button2" 3 "Button3_4or3" 4 "Button4" 5 "Button5_6or5" 6 "Button6" 7 "Button7_8or7" 8 "Button8" 9 "Button9_0or9" 10 "Button0" 11 "Button7_8and9_0" 12 "NotUsed_1" 13 "NotUsed_2" 14 "NotUsed_3" 15 "NotUsed_4" ;
VAL_ 945 KeyPadCodeDgt5_D_Dsply 0 "EndofString" 1 "Button1_2or1" 2 "Button2" 3 "Button3_4or3" 4 "Button4" 5 "Button5_6or5" 6 "Button6" 7 "Button7_8or7" 8 "Button8" 9 "Button9_0or9" 10 "Button0" 11 "Button7_8and9_0" 12 "NotUsed_1" 13 "NotUsed_2" 14 "NotUsed_3" 15 "NotUsed_4" ;
VAL_ 945 KeyPadCodeDgt7_D_Dsply 0 "EndofString" 1 "Button1_2or1" 2 "Button2" 3 "Button3_4or3" 4 "Button4" 5 "Button5_6or5" 6 "Button6" 7 "Button7_8or7" 8 "Button8" 9 "Button9_0or9" 10 "Button0" 11 "Button7_8and9_0" 12 "NotUsed_1" 13 "NotUsed_2" 14 "NotUsed_3" 15 "NotUsed_4" ;
VAL_ 945 DelvrAsstMsgTxt_D_Rq 0 "NoMessage" 1 "Message1" 2 "Message2" 3 "Message3" 4 "Message4" 5 "Message5" 6 "Message6" 7 "Message7" 8 "Message8" 9 "Message9" 10 "Message10" 11 "Message11" 12 "Message12" 13 "Message13" 14 "Message14" 15 "Message15" ;
VAL_ 945 StrtrMtrCtlMsgTxt_D_Rq2 0 "NoMessage" 1 "Fault_GoToDealer" 2 "PressTwiceToStart" 3 "Fault_UnableToStrtOrStop" 4 "No_Key_Learned" 5 "One_Key_Learned" 6 "Two_Keys_Learned" 7 "Three_Keys_Learned" 8 "Not_Used_5" 9 "Not_Used_6" 10 "Not_Used_7" 11 "Not_Used_8" 12 "Not_Used_9" 13 "Not_Used_10" 14 "Not_Used_11" 15 "Not_Used_12" ;
VAL_ 945 DrMatRleas_B_Rq 0 "False" 1 "True" ;
VAL_ 945 DrMatChime_B_Rq 0 "Off" 1 "On" ;
VAL_ 945 PaseKeySearch_Stat 0 "Inactive" 1 "Active" ;
VAL_ 945 BrkPtsActv_B_Stat 0 "Inactive" 1 "Active" ;
VAL_ 946 DrStatTgate_B_Actl 0 "Closed" 1 "Ajar" ;
VAL_ 946 FogLghtRearOn_B_Stat 0 "Off" 1 "On" ;
VAL_ 946 Parklamp_Status 0 "Off" 1 "On" 2 "Unknown" 3 "Invalid" ;
VAL_ 946 Ignition_Status 0 "Unknown" 1 "Off" 2 "Accessory" 4 "Run" 8 "Start" 15 "Invalid" ;
VAL_ 946 TurnLghtLeft_D_Rq 0 "Null" 1 "Off" 2 "On" 3 "Seq" ;
VAL_ 946 BodySrvcRqd_B_Rq 0 "No" 1 "Yes" ;
VAL_ 946 Key_In_Ignition_Stat 0 "Out" 1 "In" ;
VAL_ 946 Remote_Start_Status 0 "Null" 1 "Remote" 2 "Unknown" 3 "Invalid" ;
VAL_ 946 Day_Night_Status 0 "Null" 1 "Day" 2 "Night" 3 "NotUsed" ;
VAL_ 946 ValetMode_D_Mem 0 "Off" 1 "On" ;
VAL_ 946 DrStatDrvErrCnt_B_Stat 0 "No" 1 "Yes" ;
VAL_ 946 Backlit_LED_Status 0 "Off" 1 "Night_1" 2 "Night_2" 3 "Night_3" 4 "Night_4" 5 "Night_5" 6 "Night_6" 7 "Night_7" 8 "Night_8" 9 "Night_9" 10 "Night_10" 11 "Night_11" 12 "Night_12" 13 "Unused1" 14 "Unused2" 15 "Unused3" ;
VAL_ 946 Dimming_Lvl 0 "Off" 1 "Night_1" 2 "Night_2" 3 "Night_3" 4 "Night_4" 5 "Night_5" 6 "Night_6" 7 "Night_7" 8 "Night_8" 9 "Night_9" 10 "Night_10" 11 "Night_11" 12 "Night_12" 13 "Day_1" 14 "Day_2" 15 "Day_3" 16 "Day_4" 17 "Day_5" 18 "Day_6" 254 "Unknown" 255 "Invalid" ;
VAL_ 946 FuelPmpInhbt_B_Stat 0 "No_Inibit" 1 "Inhibit" ;
VAL_ 946 CrashEvnt_D_Stat 0 "No_Event" 1 "Deploy_Event" 2 "Fuel_Cutoff_Event" 3 "Invalid" ;
VAL_ 946 TurnLghtRightOn_B_Stat 0 "Off" 1 "On" ;
VAL_ 946 IgnKeyType_D_Actl 0 "Key_Read_In_Progress" 1 "Key_In_Ign_Standard_Key" 2 "Key_In_Ign_My_Key" 3 "Key_Not_Prgrm_Read_Failure" 14 "Unknown" 15 "Invalid" ;
VAL_ 946 Litval 0 "Night" 1 "Twilight_1" 2 "Twilight_2" 3 "Twilight_3" 4 "Twilight_4" 5 "Day" 254 "Unknown" 255 "Invalid" ;
VAL_ 946 DrStatRl_B_Actl 0 "Closed" 1 "Ajar" ;
VAL_ 946 DrStatRr_B_Actl 0 "Closed" 1 "Ajar" ;
VAL_ 946 LifeCycMde_D_Actl 0 "Normal" 1 "Factory" 2 "NotUsed" 3 "Transport" ;
VAL_ 946 TurnLghtLeftOn_B_Stat 0 "Off" 1 "On" ;
VAL_ 946 PrkBrkActv_B_Actl 0 "Inactive" 1 "Active" ;
VAL_ 946 FogLghtFrontOn_B_Stat 0 "Off" 1 "On" ;
VAL_ 946 Delay_Accy 0 "Off" 1 "On" ;
VAL_ 946 DrStatInnrTgate_B_Actl 0 "Closed" 1 "Ajar" ;
VAL_ 946 DrStatHood_B_Actl 0 "Closed" 1 "Ajar" ;
VAL_ 946 DrStatPsngr_B_Actl 0 "Closed" 1 "Ajar" ;
VAL_ 946 DrStatDrv_B_Actl 0 "Closed" 1 "Ajar" ;
VAL_ 946 TurnLghtRight_D_Rq 0 "Null" 1 "Off" 2 "On" 3 "Seq" ;
VAL_ 948 TirePReset_D_Stat 0 "Null" 1 "Ack" 2 "Nack" 3 "Not_Used" ;
VAL_ 948 Tire_Press_Telltale 0 "Off" 1 "On" 2 "Flash" 3 "Not_Used" ;
VAL_ 948 Tire_Press_System_Stat 0 "Unknown_Composite_Stat" 1 "Systm_Fault_Composite_Stat" 2 "Sensr_Fault_Composite_Stat" 3 "Low_Composite_Stat" 4 "Systm_Activ_Composite_Stat" 5 "Train_LeftFront_tire" 6 "Train_RightFront_tire" 7 "Train_RightRear_tire" 8 "Train_OutsideRtRear_tire" 9 "Train_InsideRtRear_tire" 10 "Train_LeftRear_tire" 11 "Train_OutsideLeftRear_tire" 12 "Train_InsideLeftRear_tire" 13 "Training_Complete" 14 "Tires_not_trained" ;
VAL_ 948 Tire_Press_RF_Stat 0 "Unknown" 1 "Normal" 2 "Low" 3 "Fault" 4 "Alert" 15 "Not_Supported" ;
VAL_ 948 Tire_Press_LF_Stat 0 "Unknown" 1 "Normal" 2 "Low" 3 "Fault" 4 "Alert" 15 "Not_Supported" ;
VAL_ 948 Tire_Press_LR_OLR_Stat 0 "Unknown" 1 "Normal" 2 "Low" 3 "Fault" 4 "Alert" 15 "Not_Supported" ;
VAL_ 948 Tire_Press_RR_ORR_Stat 0 "Unknown" 1 "Normal" 2 "Low" 3 "Fault" 4 "Alert" 15 "Not_Supported" ;
VAL_ 948 Tire_Press_ILR_Stat 0 "Unknown" 1 "Normal" 2 "Low" 3 "Fault" 4 "Alert" 15 "Not_Supported" ;
VAL_ 948 Tire_Press_IRR_Stat 0 "Unknown" 1 "Normal" 2 "Low" 3 "Fault" 4 "Alert" 15 "Not_Supported" ;
VAL_ 948 TlghtTestPrecnd_D2_Stat 0 "Null" 1 "IgnitionNotOn" 2 "TailLightsOn" 3 "BattSocLessThan75Percent" 4 "PreconditionsPassed" 5 "InteractionPresent" 6 "NotStationary" 7 "TrailerNotConnected" ;
VAL_ 948 TlghtTestLght_D2_Stat 0 "Null" 1 "ParkingLightsIlluminated" 2 "TestingRightTurnSignal" 3 "TestingLeftTurnSignal" 4 "TestingBrakeLights" 5 "TestingReverseLights" 6 "AllOff" 7 "TestingRearFogLights" ;
VAL_ 949 Tire_Press_LF_Data 65533 "Unknown" 65534 "Invalid" 65535 "Not_Supported" ;
VAL_ 949 Tire_Press_RF_Data 65533 "Unknown" 65534 "Invalid" 65535 "Not_Supported" ;
VAL_ 949 Tire_Press_RR_ORR_Data 65533 "Unknown" 65534 "Invalid" 65535 "Not_Supported" ;
VAL_ 949 Tire_Press_LR_OLR_Data 65533 "Unknown" 65534 "Invalid" 65535 "Not_Supported" ;
VAL_ 952 Tire_Press_ILR_Data 65533 "Unknown" 65534 "Invalid" 65535 "Not_Supported" ;
VAL_ 952 Tire_Press_IRR_Data 65533 "Unknown" 65534 "Invalid" 65535 "Not_Supported" ;
VAL_ 953 WakeAlarm3_D_Stat 0 "AlarmOff" 1 "AlarmRunning" 2 "Wake" 3 "PublisherReset" ;
VAL_ 953 WakeAlarm2_D_Stat 0 "AlarmOff" 1 "AlarmRunning" 2 "Wake" 3 "PublisherReset" ;
VAL_ 953 WakeAlarm1_D_Stat 0 "AlarmOff" 1 "AlarmRunning" 2 "Wake" 3 "PublisherReset" ;
VAL_ 953 WakeAlarm0_D_Stat 0 "AlarmOff" 1 "AlarmRunning" 2 "Wake" 3 "PublisherReset" ;
VAL_ 953 BattRgenLoChrg_D_Rq 0 "Open" 1 "Closed" 2 "Retain" 3 "DoNotCare" ;
VAL_ 953 BattRgenLoDChrg_D_Rq 0 "Open" 1 "Closed" 2 "Retain" 3 "DoNotCare" ;
VAL_ 953 PaakMyKeySearch_D_Stat 0 "Null" 1 "NoValidPaakFound" 2 "StandardPaakFound" 3 "MyKeyPaakFound" 4 "ConfirmHmi" 5 "PressLockButton" 6 "LockButtonTimeOut" 7 "PhoneErased" ;
VAL_ 953 ChrgCordLck_B_Stat 0 "Null" 1 "Unlock" ;
VAL_ 953 BattULoChrgHyb_B_Rq 0 "False" 1 "True" ;
VAL_ 953 OraZone1_D_Stat 0 "Null" 1 "Off" 2 "On" 3 "Not_Used" ;
VAL_ 953 BattULoChrgHyb_D_Stat 0 "Null" 1 "BatteryServiceRequired" 2 "EvRangeLossDueToLoadActive" 3 "VehicleServiceRequired" 4 "NotUsed_1" 5 "NotUsed_2" 6 "NotUsed_3" 7 "NotUsed_4" ;
VAL_ 954 ExtLght_D_Falt 0 "Null" 1 "StartEngine" 2 "NoStationary" 3 "Error" ;
VAL_ 954 ExtLghtLeft_D_Stat 0 "Null" 1 "Off" 2 "On" 3 "NotUsed" ;
VAL_ 954 ExtLghtFront_D_Stat 0 "Null" 1 "Off" 2 "On" 3 "NotUsed" ;
VAL_ 954 ExtLghtAlrt_B_Rq 0 "No" 1 "Yes" ;
VAL_ 954 PudSptLghtRight_D_Rq 0 "Null" 1 "Off" 2 "On" 3 "NotUsed" ;
VAL_ 954 PudSptLghtLeft_D_Rq 0 "Null" 1 "Off" 2 "On" 3 "NotUsed" ;
VAL_ 954 ExtLghtRight_D_Stat 0 "Null" 1 "Off" 2 "On" 3 "NotUsed" ;
VAL_ 954 ExtLghtRear_D_Stat 0 "Null" 1 "Off" 2 "On" 3 "NotUsed" ;
VAL_ 954 TrukBedLght_B_Stat 0 "Off" 1 "On" ;
VAL_ 954 TrlrHitchLamp_D_Stat 0 "Off" 1 "On" ;
VAL_ 954 LicPlateLght_B_Stat 0 "Off" 1 "On" ;
VAL_ 954 VehWlcmFrwlMde_D_Stat 0 "Null" 1 "Approach" 2 "IlluminatedEntry" 3 "CourtesyLightingAll" 4 "CourtesyLightingDelayAll" 5 "CourtesyLightingExtended" 6 "CourtesyLightingDelayExt" 7 "IlluminatedExit" ;
VAL_ 954 VehWlcmFrwl_D_Stat 0 "Null" 1 "Welcome" 2 "Farewell" 3 "RunStart" ;
VAL_ 954 TlghtTest_D_Stat 0 "Null" 1 "Completed" 2 "Ended" 3 "InProgress" ;
VAL_ 954 LghtAmbDrvMde_B_Stat 0 "Manual" 1 "Automatic" ;
VAL_ 954 PwRnngBoardPoll_D_Stat 0 "NotPolling" 1 "PkNotPresent" 2 "PkPresent" 3 "NotUsed" ;
VAL_ 954 PoliceDmngLvl_D_Stat 0 "Null" 1 "Decommissioned" 2 "Inactive" 3 "Low1Day" 4 "Low1Night" 5 "Off_Day" 6 "Off_Night" 7 "NotUsed" ;
VAL_ 954 LoadShedRelay_B_Rq 0 "Inactive" 1 "Active" ;
VAL_ 954 KeylessIdl_B_Stat 0 "Not_Pressed" 1 "Pressed" ;
VAL_ 954 TlghtTestLght_D_Stat 0 "Null" 1 "ParkingLightsIlluminated" 2 "TestingRightTurnSignal" 3 "TestingLeftTurnSignal" 4 "TestingBrakeLights" 5 "TestingReverseLights" 6 "AllOff" 7 "Error" ;
VAL_ 954 TlghtTestPrecnd_D_Stat 0 "Null" 1 "IgnitionNotOn" 2 "TailLightsOn" 3 "BattSocLessThan75Percent" 4 "PreconditionsPassed" 5 "InteractionPresent" 6 "NotStationary" 7 "Error" ;
VAL_ 954 PosLghtFr_D_Stat 0 "Off" 1 "On" 2 "Outage" 3 "Faulty" ;
VAL_ 954 PosLghtFl_D_Stat 0 "Off" 1 "On" 2 "Outage" 3 "Faulty" ;
VAL_ 954 LoadShedRelayMde_D_Stat 0 "LoadShed" 1 "SnowPlow" 2 "EngRunRelay" 3 "NotUsed_1" ;
VAL_ 954 CargoLght_D_Stat 0 "Null" 1 "Manual" 2 "Automatic" 3 "NotUsed" ;
VAL_ 954 TrlrHitchLamp_D2_Stat 0 "Null" 1 "Manual" 2 "Automatic" 3 "NotUsed" ;
VAL_ 954 ChildLckMaint_D_Stat 0 "Off" 1 "On" 2 "Overruled" 3 "NotUsed_1" ;
VAL_ 954 ExtLghtFront_D_RqBody 0 "Null" 1 "Off" 2 "On" 3 "NotUsed" ;
VAL_ 954 CrtsyLghtRear_D_Stat 0 "Null" 1 "Manual" 2 "Automatic" 3 "NotUsed_1" ;
VAL_ 955 Tire_Temp_ILR_Data 254 "Invalid" 255 "NotSupported" ;
VAL_ 955 Tire_Temp_IRR_Data 254 "Invalid" 255 "NotSupported" ;
VAL_ 955 Tire_Temp_LF_Data 254 "Invalid" 255 "NotSupported" ;
VAL_ 955 Tire_Temp_OLR_Data 254 "Invalid" 255 "NotSupported" ;
VAL_ 955 Tire_Temp_ORR_Data 254 "Invalid" 255 "NotSupported" ;
VAL_ 955 Tire_Temp_RF_Data 254 "Invalid" 255 "NotSupported" ;
VAL_ 963 PerimeterAlarmChimeRq 0 "Off" 1 "On" ;
VAL_ 963 HeadLghtHiOn_B_Stat 0 "Off" 1 "On" ;
VAL_ 963 HeadLampLoFrOn_B_Stat 0 "Not_Low" 1 "Low" ;
VAL_ 963 HeadLampLoFlOn_B_Stat 0 "Not_Low" 1 "Low" ;
VAL_ 963 HeadLampLoActv_B_Stat 0 "Off" 1 "On" ;
VAL_ 963 DayRnngLampOn_B_Stat 0 "Off" 1 "On" ;
VAL_ 963 Courtesy_BSave_Stat 0 "Off" 1 "No_Effect" 2 "Unknown" 3 "Invalid" ;
VAL_ 963 StopLghtOn_B_Stat 0 "Off" 1 "On" ;
VAL_ 963 RvrseLghtOn_B_Stat 0 "Off" 1 "On" ;
VAL_ 963 PudLamp_D_Rq 0 "OFF" 1 "ON" 2 "RAMP_UP" 3 "RAMP_DOWN" ;
VAL_ 963 PrkLght_D_Stat 0 "Off" 1 "Park_Left" 2 "Park_Right" 3 "Park_Both" ;
VAL_ 963 HeadLghtSwtch_D_Stat 0 "Off" 1 "Parklamp" 2 "Headlamp" 3 "Autolamp" ;
VAL_ 963 Perimeter_Alarm_Status 0 "Disarmed" 1 "Prearmed" 2 "Armed" 3 "Activated" ;
VAL_ 963 ReducedGuard_D_Stat 0 "Alarm_Off" 1 "Alarm_Off_Previously_On" 2 "Alarm_On" 3 "Person_Inside_DSIS" ;
VAL_ 963 BrkWarnInd_B_Rq 0 "Off" 1 "On" ;
VAL_ 963 WndwGlbl_D_Cmd 0 "Null" 1 "GSTOP" 2 "GOPEN" 3 "GCLOSE" 4 "GLEARN" 5 "NotUsed1" 6 "NotUsed2" 7 "NotUsed3" ;
VAL_ 963 TrnNotInPrkChime_B_Rq 0 "Off" 1 "On" ;
VAL_ 963 PrkLightChime_B_Rq 0 "Off" 1 "On" ;
VAL_ 963 Park_Brake_Chime_Rqst 0 "Off" 1 "On" ;
VAL_ 963 KeyInIgnWarn_B_Cmd 0 "Off" 1 "On" ;
VAL_ 963 HomeSafeLtChime_B_Rq 0 "Off" 1 "On" ;
VAL_ 963 Headlamp_On_Wrning_Cmd 0 "Off" 1 "On" ;
VAL_ 963 Brk_Fluid_Lvl_Low 0 "OK" 1 "Low" 2 "Unknown" 3 "Invalid" ;
VAL_ 963 HeadLampLoOut_B_Stat 0 "Null" 1 "Out" ;
VAL_ 963 WrlssAcsyChrgInhbt_B_Rq 0 "No" 1 "Yes" ;
VAL_ 963 Dr_Courtesy_Light_Stat 0 "Off" 1 "On" 2 "Unknown" 3 "Invalid" ;
VAL_ 963 Courtesy_Delay_Status 0 "Off" 1 "On" 2 "Unknown" 3 "Invalid" ;
VAL_ 963 ImpactEvntFdbck_D_Stat 0 "Normal" 1 "EventInProgress" 2 "EventComplete" 3 "NotUsed" ;
VAL_ 963 HeadLghtHiFdbck_D_Stat 0 "Allow_Change" 1 "Hold" 2 "Cancel" 3 "NotUsed" ;
VAL_ 963 PudLampPsngr_D_Rq 0 "Off" 1 "On" 2 "Ramp_Up" 3 "Ramp_Down" ;
VAL_ 963 PudLampDrv_D_Rq 0 "Off" 1 "On" 2 "Ramp_Up" 3 "Ramp_Down" ;
VAL_ 963 DrTgateLck_D_Stat 0 "Null" 1 "Lock" 2 "Unlock" 3 "NotUsed" ;
VAL_ 963 Illuminated_Entry_Stat 0 "Off" 1 "On" 2 "Unknown" 3 "Invalid" ;
VAL_ 965 TrnkFrontLatch_B_Falt 0 "No_Fault" 1 "Fault" ;
VAL_ 965 TrnkFrontPrim_B_Falt 0 "NoFault" 1 "Fault" ;
VAL_ 965 TrnkFrontEmgcy_D_Stat 0 "NotPressed" 1 "SwitchState1" 2 "SwitchState2" 3 "NotDetermined" ;
VAL_ 965 PtWakeupActv4_B_Rq 0 "Off" 1 "On" ;
VAL_ 965 TrunkFrontOpen_D_Stat 0 "Null" 1 "Restricted" 2 "NotRestricted" 3 "NotUsed" ;
VAL_ 965 DrHoodPos_D_Stat 0 "Unknown" 1 "Latched" 2 "Secondary" 3 "Unlatched" 4 "NotUsed_1" 5 "NotUsed_2" 6 "NotUsed_3" 7 "Faulty" ;
VAL_ 966 VehHorn_D_RqAlrt 0 "Off" 1 "On" 2 "Null" 3 "NotUsed" ;
VAL_ 966 TrnkFrontRleas_D_Src 0 "Null" 1 "Remote" 2 "Keypad" 3 "Sync" 4 "Cpp" 5 "NotUsed_1" 6 "NotUsed_2" 7 "NotUsed_3" ;
VAL_ 966 ExtLghtRear_D_RqBody 0 "Null" 1 "Off" 2 "On" 3 "NotUsed" ;
VAL_ 966 TrnkFrontInhbt_B_Stat 0 "NoInhibit" 1 "Inhibit" ;
VAL_ 966 ScrtyHornActv_B_Rq 0 "Inactive" 1 "Active" ;
VAL_ 966 VehHorn_D_Rq 0 "Off" 1 "Null" 2 "Chirp_1" 3 "Chirp_2" 4 "Chirp_2H" 5 "ChirpHonk" 6 "Honk" 7 "ManualOn" 8 "Chirp_3" 9 "NotUsed_1" 10 "NotUsed_2" 11 "NotUsed_3" 12 "NotUsed_4" 13 "NotUsed_5" 14 "NotUsed_6" 15 "NotUsed_7" ;
VAL_ 966 NfcDevcAuthrzT_B_Rq 0 "Null" 1 "Valid" ;
VAL_ 966 PwTrnkFrntRelay_B_Stat 0 "NoInhibit" 1 "Inhibit" ;
VAL_ 966 PwTrnkFrontRleas_D_Src 0 "PowerOff" 1 "Remote" 2 "Keypad" 3 "Sync" 4 "Cpp" 5 "IpSwitch" 6 "ExteriorSwitch" 7 "ManualCinch" 8 "EmergencyReleaseSwitch" 9 "Diagnostics" 10 "SelfTest" 11 "NotUsed_1" 12 "NotUsed_2" 13 "NotUsed_3" 14 "NotUsed_4" 15 "NotUsed_5" ;
VAL_ 966 TrnkFrontScnd_B_Falt 0 "NoFault" 1 "Fault" ;
VAL_ 966 NfcDevc_D_Dsply 0 "No_message" 1 "Message_1" 2 "Message_2" 3 "Message_3" 4 "Message_4" 5 "Message_5" 6 "Message_6" 7 "Message_7" 8 "Message_8" 9 "Message_9" 10 "Message_10" 11 "Message_11" 12 "Message_12" 13 "Message_13" 14 "Message_14" 15 "Message_15" ;
VAL_ 967 CamraZoomMan_D_Actl 0 "Off" 1 "Zoom_Level_I" 2 "Zoom_Level_II" 3 "Zoom_Level_III" 4 "Zoom_Level_IV" 5 "Zoom_Level_V" 6 "Invalid" 7 "Unknown" ;
VAL_ 967 CamraOvrlDyn_D_Actl 0 "Invalid" 1 "Active" 2 "Inactive" 3 "Not_Used" ;
VAL_ 967 CamraViewSplit_D_Actl 0 "Invalid" 1 "Active" 2 "Inactive" 3 "NotUsed" ;
VAL_ 967 CamraOvrlTow_D_Actl 0 "Invalid" 1 "Active" 2 "Inactive" 3 "Not_Used" ;
VAL_ 967 CamraOvrlStat_D_Actl 0 "Invalid" 1 "Active" 2 "Inactive" 3 "Not_Used" ;
VAL_ 967 CamZoomActiveState 0 "Invalid" 1 "Active" 2 "Inactive" 3 "Not_Used" ;
VAL_ 967 CamPDCGuidStat 0 "Invalid" 1 "Active" 2 "Inactive" 3 "Not_Used" ;
VAL_ 967 NfcMyKeyCreate_D2_Stat 0 "Null" 1 "TapNfcCard" 2 "TapTimeOut" 3 "KeyAlreadyMyKey" 4 "Device Not paired" 5 "NotUsed_1" 6 "NotUsed_2" 7 "NotUsed_3" ;
VAL_ 968 Dimming_Level_Cmd 0 "Null" 1 "High" 2 "Not_Used" 3 "Low" ;
VAL_ 968 BlendedColorBlue_Cmd 0 "Null" 1 "1" 2 "2" 3 "3" 4 "4" 5 "5" 6 "NotUsed1" 7 "NotUsed2" 8 "NotUsed3" 9 "NotUsed4" 10 "NotUsed5" 11 "NotUsed6" 12 "NotUsed7" 13 "NotUsed8" 14 "NotUsed9" 15 "NotUsed10" ;
VAL_ 968 BlendedColor_Cmd 0 "Off" 1 "On" 2 "Null" 3 "NotUsed" ;
VAL_ 968 BlendedColorRed_Cmd 0 "Null" 1 "1" 2 "2" 3 "3" 4 "4" 5 "5" 6 "NotUsed1" 7 "NotUsed2" 8 "NotUsed3" 9 "NotUsed4" 10 "NotUsed5" 11 "NotUsed6" 12 "NotUsed7" 13 "NotUsed8" 14 "NotUsed9" 15 "NotUsed10" ;
VAL_ 968 BlendedColorGreen_Cmd 0 "Null" 1 "1" 2 "2" 3 "3" 4 "4" 5 "5" 6 "NotUsed1" 7 "NotUsed2" 8 "NotUsed3" 9 "NotUsed4" 10 "NotUsed5" 11 "NotUsed6" 12 "NotUsed7" 13 "NotUsed8" 14 "NotUsed9" 15 "NotUsed10" ;
VAL_ 968 BrkDrvMde_D_Rq 0 "Normal" 1 "Sport" 2 "Snow_Wet" 3 "Track" 4 "DragOrMudAndSand" 5 "Baja" 6 "RockCrawl" 7 "Faulty" ;
VAL_ 968 Current_Color_Cmd 0 "Off" 1 "Color1" 2 "Color2" 3 "Color3" 4 "Color4" 5 "Color5" 6 "Color6" 7 "Color7" 8 "Null" 9 "NotUsed1" 10 "NotUsed2" 11 "NotUsed3" 12 "NotUsed4" 13 "NotUsed5" 14 "NotUsed6" 15 "NotUsed7" ;
VAL_ 968 BlendedColor_CmdGage 0 "Off" 1 "On" 2 "Null" 3 "NotUsed" ;
VAL_ 968 SlMde_D_Rq 0 "Null" 1 "Auto_Mode" 2 "Manual_Mode" 3 "IsaNotConfigured" ;
VAL_ 968 IsaOffst_D_Rq 0 "Zero" 1 "One" 2 "Two" 3 "Three" 4 "Four" 5 "Five" 6 "Six" 7 "Seven" 8 "Eight" 9 "Nine" 10 "Ten" 11 "Eleven" 12 "Twelve" 13 "Thirteen" 14 "Null" 15 "Faulty" ;
VAL_ 968 BlendColorGrn_CmdGage 0 "Null" 1 "1" 2 "2" 3 "3" 4 "4" 5 "5" 6 "NotUsed1" 7 "NotUsed2" 8 "NotUsed3" 9 "NotUsed4" 10 "NotUsed5" 11 "NotUsed6" 12 "NotUsed7" 13 "NotUsed8" 14 "NotUsed9" 15 "NotUsed10" ;
VAL_ 968 BlendColorBlue_CmdGage 0 "Null" 1 "1" 2 "2" 3 "3" 4 "4" 5 "5" 6 "NotUsed1" 7 "NotUsed2" 8 "NotUsed3" 9 "NotUsed4" 10 "NotUsed5" 11 "NotUsed6" 12 "NotUsed7" 13 "NotUsed8" 14 "NotUsed9" 15 "NotUsed10" ;
VAL_ 968 CurrentColor_CmdGage 0 "Off" 1 "Color1" 2 "Color2" 3 "Color3" 4 "Color4" 5 "Color5" 6 "Color6" 7 "Color7" 8 "Null" 9 "NotUsed1" 10 "NotUsed2" 11 "NotUsed3" 12 "NotUsed4" 13 "NotUsed5" 14 "NotUsed6" 15 "NotUsed7" ;
VAL_ 968 BlendColorRed_CmdGage 0 "Null" 1 "1" 2 "2" 3 "3" 4 "4" 5 "5" 6 "NotUsed1" 7 "NotUsed2" 8 "NotUsed3" 9 "NotUsed4" 10 "NotUsed5" 11 "NotUsed6" 12 "NotUsed7" 13 "NotUsed8" 14 "NotUsed9" 15 "NotUsed10" ;
VAL_ 968 IpcLvl_B_Type 0 "Low" 1 "High" ;
VAL_ 968 RvltnMatchAllw_D_Rq 0 "NoSelection" 1 "ChangeWithDriveMode" 2 "RevolutionMatchEnabled" 3 "RevolutionMatchDisabled" ;
VAL_ 968 SuspDrvMde_D_Rq 0 "Normal" 1 "Sport" 2 "Snow_Wet" 3 "Track" 4 "Drag" 5 "NotUsed1" 6 "NotUsed2" 7 "Faulty" ;
VAL_ 968 LnchCtl_D_Rq 0 "LC_Off" 1 "LC_On" 2 "NotUsed1" 3 "NotUsed2" ;
VAL_ 969 TurnLampRrOut_B_Stat 0 "Null" 1 "Out" ;
VAL_ 969 TurnLampRlOut_B_Stat 0 "Null" 1 "Out" ;
VAL_ 969 Dimming_Level_Stat 0 "Null" 1 "High" 2 "Not_Used" 3 "Low" ;
VAL_ 969 BlendedColor_Stat 0 "Off" 1 "On" 2 "Null" 3 "NotUsed" ;
VAL_ 969 WndwQtrRrDown_B_Stat 0 "No" 1 "Yes" ;
VAL_ 969 WndwQtrRlDown_B_Stat 0 "No" 1 "Yes" ;
VAL_ 969 BlendedColorGreen_Stat 0 "Null" 1 "1" 2 "2" 3 "3" 4 "4" 5 "5" 6 "NotUsed1" 7 "NotUsed2" 8 "NotUsed3" 9 "NotUsed4" 10 "NotUsed5" 11 "NotUsed6" 12 "NotUsed7" 13 "NotUsed8" 14 "NotUsed9" 15 "NotUsed10" ;
VAL_ 969 BlendedColorBlue_Stat 0 "Null" 1 "1" 2 "2" 3 "3" 4 "4" 5 "5" 6 "NotUsed1" 7 "NotUsed2" 8 "NotUsed3" 9 "NotUsed4" 10 "NotUsed5" 11 "NotUsed6" 12 "NotUsed7" 13 "NotUsed8" 14 "NotUsed9" 15 "NotUsed10" ;
VAL_ 969 Current_Color_Stat 0 "Off" 1 "Color1" 2 "Color2" 3 "Color3" 4 "Color4" 5 "Color5" 6 "Color6" 7 "Color7" 8 "Null" 9 "NotUsed1" 10 "NotUsed2" 11 "NotUsed3" 12 "NotUsed4" 13 "NotUsed5" 14 "NotUsed6" 15 "NotUsed7" ;
VAL_ 969 BlendedColorRed_Stat 0 "Null" 1 "1" 2 "2" 3 "3" 4 "4" 5 "5" 6 "NotUsed1" 7 "NotUsed2" 8 "NotUsed3" 9 "NotUsed4" 10 "NotUsed5" 11 "NotUsed6" 12 "NotUsed7" 13 "NotUsed8" 14 "NotUsed9" 15 "NotUsed10" ;
VAL_ 972 LsmcBrkDecelEnbl_D_Rq 0 "Off" 1 "On" 2 "NotUsed1" 3 "NotUsed2" ;
VAL_ 972 TjaHandsOnCnfdnc_B_Est 0 "Low_Confidence" 1 "High_Confidence" ;
VAL_ 972 LaActAvail_D2_Actl 0 "NoIntervention_NotAvailabl" 1 "Intervention_NotAvailable" 2 "NoIntervention_Available" 3 "Intervention_Available" ;
VAL_ 972 LaActDeny_B_Actl 0 "LA_Not_Denied" 1 "LA_Denied" ;
VAL_ 972 LaHandsOff_B_Actl 0 "Hands_On" 1 "Hands_Off" ;
VAL_ 972 LatCtlSte_D_Stat 0 "Unavailable" 1 "Available" 2 "ContLatControlInProgress" 3 "RampOut" 4 "Denied" 5 "NotUsed1" 6 "NotUsed2" 7 "NotUsed3" ;
VAL_ 972 LatCtlLim_D_Stat 0 "LimitNotReached" 1 "LimitClose" 2 "LimitReached" 3 "LimitWithDriverActive" ;
VAL_ 972 LatCtlCpblty_D_Stat 0 "NoModeAvailable" 1 "LimitedModeAvailable" 2 "ExtendedModeAvailable" 3 "Faulty" ;
VAL_ 973 TsrOvtkStatMsgTxt_D_Rq 0 "Null" 1 "LimitChanged" 2 "LimitReiable" 3 "LimitOutdated" ;
VAL_ 973 TsrOswWarnMsgTxt_D_Rq 0 "Null" 1 "False" 2 "True" 3 "NotUsed" ;
VAL_ 973 TsrMsgTxt_D_Rq 0 "Null" 1 "NoInformationAllOK" 2 "NoNavAvailableSwitchedOff" 3 "NoNavDataAvailable" 4 "WrngNavDatIncompDatCarrier" 5 "CountryNotSupported" 6 "RegionNotSupported" 7 "OffRoad" 8 "LimitedSystemPerformance" 9 "RecgnzdSignNotUsblForDsply" 10 "NotUsed1" 11 "NotUsed2" 12 "NotUsed3" 13 "NotUsed4" 14 "NotUsed5" 15 "NotUsed6" ;
VAL_ 973 TsrStatMsgTxt_D_Rq 0 "Null" 1 "TSR_Off" 2 "Available_FusionMode" 3 "Available_CameraOnly" 4 "Available_NavigationOnly" 5 "TSR_Error" 6 "NoDataExists" 7 "NotUsed" ;
VAL_ 973 PersCtaSplitView_D_Stat 0 "Null" 1 "Disabled" 2 "Enabled_180SwitchOnly" 3 "EnabledFull" ;
VAL_ 973 TsrOvtkMsgTxt_D_Rq 0 "Null" 1 "OvertakingAllowed" 2 "LimAllWithoutRestriction" 3 "LimAllWithoutQlfdRstrc" 4 "LimAllCancelled" 5 "LimForTrucksWithoutRstrc" 6 "LimForTrucksWoQlfdRstrc" 7 "LimForTrucksCancelled" ;
VAL_ 973 TsrVl2RstrcMsgTxt_D_Rq 0 "Null" 1 "NoSpeedLimitRestriction" 2 "NoRecognizableRestriction" 3 "NotUsed" ;
VAL_ 973 RoadSignRgltry_D_Dsply 0 "None" 1 "Yield" 2 "Stop" 3 "NoEntry" ;
VAL_ 973 TsrVl1StatMsgTxt_D_Rq 0 "Null" 1 "LimitChanged" 2 "LimitReiable" 3 "LimitOutdated" ;
VAL_ 973 TsrVl1RstrcMsgTxt_D_Rq 0 "Null" 1 "NoSpeedLimitRestriction" 2 "NoRecognizableRestriction" 3 "NotUsed" ;
VAL_ 973 TsrVLim1MsgTxt_D_Rq 0 "Null" 1 "Message1" 2 "Message2" 3 "Message3" 4 "Message4" 5 "Message5" 6 "Message6" 7 "Message7" 8 "Message8" 9 "Message9" 10 "Message10" 11 "Message11" 12 "Message12" 13 "Message13" 14 "Message14" 15 "Message15" 16 "Message16" 17 "Message17" 18 "Message18" 19 "Message19" 20 "Message20" 21 "Message21" 22 "Message22" 23 "Message23" 24 "Message24" 25 "Message25" 26 "Message26" 27 "Message27" 28 "Message28" 29 "Message29" 30 "Message30" 31 "1F_FA_Message31_250" 251 "LimitCancelled" 252 "NotToBeDisplayed" 253 "NotUsed1" 254 "NotUsed2" 255 "NoLimit" ;
VAL_ 973 TsrVLim2MsgTxt_D_Rq 0 "Null" 1 "Message1" 2 "Message2" 3 "Message3" 4 "Message4" 5 "Message5" 6 "Message6" 7 "Message7" 8 "Message8" 9 "Message9" 10 "Message10" 11 "Message11" 12 "Message12" 13 "Message13" 14 "Message14" 15 "Message15" 16 "Message16" 17 "Message17" 18 "Message18" 19 "Message19" 20 "Message20" 21 "Message21" 22 "Message22" 23 "Message23" 24 "Message24" 25 "Message25" 26 "Message26" 27 "Message27" 28 "Message28" 29 "Message29" 30 "Message30" 31 "1F_FA_Message31_250" 251 "LimitCancelled" 252 "NotToBeDisplayed" 253 "NotUsed1" 254 "NotUsed2" 255 "NoLimit" ;
VAL_ 973 TsrVl1PrmntMsgTxt_D_Rq 0 "DoNotShowSignPermanent" 1 "ShowPermanentlyWithoutSupp" 2 "ShowPermanentlyWithSupp" 3 "NotUsed" ;
VAL_ 973 TsrVlUnitMsgTxt_D_Rq 0 "Null" 1 "Kph" 2 "Mph" 3 "NoDataExists" ;
VAL_ 973 TsrChime_D_Rq 0 "Null" 1 "Overspeed_Chime" 2 "SL_Change_Chime" 3 "NotUsed_1" ;
VAL_ 973 TsrVl2StatMsgTxt_D_Rq 0 "Null" 1 "LimitChanged" 2 "LimitReiable" 3 "LimitOutdated" ;
VAL_ 973 WwaWarn_B_Rq 0 "Off" 1 "On" ;
VAL_ 973 TsrVl1RstrcMsgTxt2_D_Rq 0 "Null" 1 "NoSpeedLimitRestrictn" 2 "NoRecognizableRestrictn" 3 "RainWet" 4 "Snow" 5 "Trailer" 6 "Time" 7 "NotUsed" ;
VAL_ 973 TsrOvtkMsgTxt2_D_Rq 0 "OvertakingAllowed" 1 "LimAllWithoutRestriction" 2 "LimAllWithoutQlfdRstrc" 3 "LimAllWithRstrcRain" 4 "LimAllWithRstrcSnow" 5 "LimAllWithRstrcTrailer" 6 "LimAllWithRstrcTime" 7 "LimAllCancelled" 8 "LimForTrucksWithoutRstrc" 9 "LimForTrucksWoQlfdRstrc" 10 "LimForTrucksCancelled" 11 "NotUsed1" 12 "NotUsed2" 13 "NotUsed3" 14 "NotUsed4" 15 "NotUsed5" ;
VAL_ 973 LaSysOffStat_D_Dsply 0 "Level_0" 1 "Level_1" 2 "Level_2" 3 "Level_3" ;
VAL_ 973 TsrVl2PrmntMsgTxt_D_Rq 0 "DoNotShowSignPermanent" 1 "ShowPermanentlyWithoutSupp" 2 "ShowPermanentlyWithSupp" 3 "NotUsed" ;
VAL_ 973 TsrVl2RstrcMsgTxt2_D_Rq 0 "Null" 1 "NoSpeedLimitRestrictn" 2 "NoRecognizableRestrictn" 3 "RainWet" 4 "Snow" 5 "Trailer" 6 "Time" 7 "NotUsed" ;
VAL_ 974 DcacGfciTest_B_Rq 0 "Not_Pressed" 1 "Pressed" ;
VAL_ 974 DcacElPw_D_Stat 0 "Off" 1 "Low" 2 "High" 3 "NotUsed_1" ;
VAL_ 974 PwBedPnlEnbl_B_Rq 0 "Disable" 1 "Enable" ;
VAL_ 974 DcacOn_B_Rq 0 "Disable" 1 "Enable" ;
VAL_ 974 DcacSys_B_Falt 0 "No" 1 "Yes" ;
VAL_ 974 DcacLedCtl_D_Rq 0 "Off" 1 "On" 2 "Slow_Flash" 3 "Fast_Flash" ;
VAL_ 974 DcacHw_D_Confg 0 "NoDcacHardware" 1 "Power_2000W" 2 "Power_2400W" 3 "Power_7200W" 4 "Power_2300W" 5 "Dual_2400WAnd7200W" 6 "NotUsed_2" 7 "NotUsed_3" 8 "NotUsed_4" 9 "NotUsed_5" 10 "NotUsed_6" 11 "NotUsed_7" 12 "NotUsed_8" 13 "NotUsed_9" 14 "NotUsed_10" 15 "NotUsed_11" ;
VAL_ 974 DcacFaltMsgTxt_D_Rq 0 "Ok" 1 "Overcurrent" 2 "Gfci" 3 "Temperature" 4 "AcOnOutput" 5 "FuelLow" 6 "BreakerA" 7 "BreakerB" 8 "BreakerC" 9 "PlugWarnDrive" 10 "PlugWarn" 11 "NotAvailable" 12 "Service" 13 "EngineRun" 14 "OvercurrentLP" 15 "HvacOn" ;
VAL_ 974 DcacOut_Pw_DsplyMx 1023 "Faulty" ;
VAL_ 974 DcacGfciTestScnd_B_Rq 0 "Not_Pressed" 1 "Pressed" ;
VAL_ 974 DcacLoFuelMsgTxt_D_Rq 0 "Ok" 1 "Minute_1" 2 "Minute_2" 3 "Minute_3" 4 "Minute_4" 5 "Minute_5" 6 "Minute_6" 7 "Minute_7" 8 "Minute_8" 9 "Minute_9" 10 "Minute_10" 11 "Minute_11" 12 "Minute_12" 13 "Minute_13" 14 "Minute_14" 15 "Minute_15" 16 "Minute_16" 17 "Minute_17" 18 "Minute_18" 19 "Minute_19" 20 "Minute_20" 21 "Minute_21" 22 "Minute_22" 23 "Minute_23" 24 "Minute_24" 25 "Minute_25" 26 "Minute_26" 27 "Minute_27" 28 "Minute_28" 29 "Minute_29" 30 "Minute_30" 31 "Minute_31" ;
VAL_ 974 DcacOnScnd_B_Rq 0 "Disable" 1 "Enable" ;
VAL_ 974 DcacOut1_Pw_Dsply 63 "Faulty" ;
VAL_ 974 DcacSysScnd_B_Falt 0 "No" 1 "Yes" ;
VAL_ 974 DcacOut2_Pw_Dsply 63 "Faulty" ;
VAL_ 974 PwBedPnlEnblScnd_B_Rq 0 "Disable" 1 "Enable" ;
VAL_ 974 EngExhMdeHrStrt_D_Stat 0 "Null" 1 "Hour0_12am" 2 "Hour1_1am" 3 "Hour2_2am" 4 "Hour3_3am" 5 "Hour4_4am" 6 "Hour5_5am" 7 "Hour6_6am" 8 "Hour7_7am" 9 "Hour8_8am" 10 "Hour9_9am" 11 "Hour10_10am" 12 "Hour11_11am" 13 "Hour12_12pm" 14 "Hour13_1pm" 15 "Hour14_2pm" 16 "Hour15_3pm" 17 "Hour16_4pm" 18 "Hour17_5pm" 19 "Hour18_6pm" 20 "Hour19_7pm" 21 "Hour20_8pm" 22 "Hour21_9pm" 23 "Hour22_10pm" 24 "Hour23_11pm" 25 "NotUsed_1" 26 "NotUsed_2" 27 "NotUsed_3" 28 "NotUsed_4" 29 "NotUsed_5" 30 "NotUsed_6" 31 "NotUsed_7" ;
VAL_ 974 DcacEngOnMsgTxt_D_Rq 0 "Ok" 1 "DisplayWarning" 2 "DisplayQuestion" 3 "NotUsed" ;
VAL_ 974 LowFuelDsplyType_B_Rq 0 "Miles" 1 "Volume" ;
VAL_ 974 EngExhMdeHrEnbl_D_Stat 0 "Null" 1 "Disabled" 2 "Enabled" 3 "NotUsed" ;
VAL_ 974 EngExhMdeHrEnd_D_Stat 0 "Null" 1 "Hour0_12am" 2 "Hour1_1am" 3 "Hour2_2am" 4 "Hour3_3am" 5 "Hour4_4am" 6 "Hour5_5am" 7 "Hour6_6am" 8 "Hour7_7am" 9 "Hour8_8am" 10 "Hour9_9am" 11 "Hour10_10am" 12 "Hour11_11am" 13 "Hour12_12pm" 14 "Hour13_1pm" 15 "Hour14_2pm" 16 "Hour15_3pm" 17 "Hour16_4pm" 18 "Hour17_5pm" 19 "Hour18_6pm" 20 "Hour19_7pm" 21 "Hour20_8pm" 22 "Hour21_9pm" 23 "Hour22_10pm" 24 "Hour23_11pm" 25 "NotUsed_1" 26 "NotUsed_2" 27 "NotUsed_3" 28 "NotUsed_4" 29 "NotUsed_5" 30 "NotUsed_6" 31 "NotUsed_7" ;
VAL_ 977 CnvtTopPos_Up_Stat 0 "Not_Up" 1 "Up" ;
VAL_ 977 CnvtTopPos_Dn_Stat 0 "Not_Down" 1 "Down" ;
VAL_ 977 CnvtTopBrkActv_B_Rq 0 "Inactive" 1 "Active" ;
VAL_ 977 CnvtTop_D_Rq 0 "Stop" 1 "DirectPosition" 2 "DirectDriveOpen" 3 "DirectDriveClose" 4 "SetNormalization" 5 "DiscardNormalization" 6 "ResetErrorFlags" 7 "NotUsed" ;
VAL_ 977 WndwCnvtTopDrop_B_Cmd 0 "No" 1 "Yes" ;
VAL_ 977 CnvtTopTrgt_D_Rq 0 "CloseTarget" 1 "ClosePosition" 2 "OpenPosition" 3 "OpenTarget" 4 "NotUsed1" 5 "NotUsed2" 6 "NotUsed3" 7 "NotUsed4" ;
VAL_ 977 CnvtTopSleepActv_B_Rq 0 "Inactive" 1 "Active" ;
VAL_ 977 CnvtTopPar_D_Rq 0 "Normal" 1 "NoPwmNoAp" 2 "Teach" 3 "NoAdapt" 4 "ForceIncrease1" 5 "ForceIncrease2" 6 "ForceIncrease3" 7 "NotUsed" ;
VAL_ 977 CnvtTopMsgTxt_D_Rq 0 "NoWarning" 1 "RemoveCaps" 2 "NotAvailable" 3 "NotSecure" ;
VAL_ 978 CnvtTopDir_B_Falt 0 "No" 1 "Yes" ;
VAL_ 978 CnvtTopComplt_D_Stat 0 "StopByRequest" 1 "StopByStall" 2 "StopByPinch" 3 "StopByFault" 4 "StopByPositioning" 5 "RunoutComplete" 6 "NormalizingReady" 7 "DenormalizingReady" ;
VAL_ 978 CnvtTopCnfm_B_Stat 0 "No" 1 "Yes" ;
VAL_ 978 CnvtTopClose_D_Stat 0 "Inactive" 1 "Active" 2 "NotUsed" 3 "Faulty" ;
VAL_ 978 CnvtTopActv_B_Stat 0 "No" 1 "Yes" ;
VAL_ 978 CnvtTopPos_B_Falt 0 "No" 1 "Yes" ;
VAL_ 978 CnvtTopOut_B_Falt 0 "No" 1 "Yes" ;
VAL_ 978 CnvtTopOpen_D_Stat 0 "Inactive" 1 "Active" 2 "NotUsed" 3 "Faulty" ;
VAL_ 978 CnvtTopOpen_B_Stat 0 "No" 1 "Yes" ;
VAL_ 978 CnvtTopNom_B_Stat 0 "No" 1 "Yes" ;
VAL_ 978 CnvtTopRngClose_B_Stat 0 "Inactive" 1 "Active" ;
VAL_ 978 CnvtTopRestrc_B_Falt 0 "No" 1 "Yes" ;
VAL_ 978 CnvtTopRdy_B_Stat 0 "No" 1 "Yes" ;
VAL_ 978 CnvtTopPosSet_B_Stat 0 "No" 1 "Yes" ;
VAL_ 978 CnvtTopPos_D_Stat 0 "PositionCloseTarget" 1 "PositionClosePosition" 2 "PositionOpenPosition" 3 "PositionOpenTarget" 4 "PositionIntermediate" 5 "Moving" 6 "NoNormalised" 7 "ShutdownComplete" 8 "NotUsed1" 9 "NotUsed2" 10 "NotUsed3" 11 "NotUsed4" 12 "NotUsed5" 13 "NotUsed6" 14 "NotUsed7" 15 "Faulty" ;
VAL_ 978 CnvtTopTWarn_B_Falt 0 "No" 1 "Yes" ;
VAL_ 978 CnvtTopTOvr_B_Falt 0 "No" 1 "Yes" ;
VAL_ 978 CnvtTopTDir_B_Falt 0 "No" 1 "Yes" ;
VAL_ 978 CnvtTopStall_B_Falt 0 "No" 1 "Yes" ;
VAL_ 978 CnvtTopSns_B_Falt 0 "No" 1 "Yes" ;
VAL_ 978 CnvtTopRvrse_B_Stat 0 "No" 1 "Yes" ;
VAL_ 978 CnvtTopRngOpen_B_Stat 0 "Inactive" 1 "Active" ;
VAL_ 978 TonneuCapMde_D_Stat 0 "NotInstalled" 1 "Installed" 2 "NotUsed" 3 "Faulty" ;
VAL_ 980 BattDcChrg_U_Actl 1022 "NoDataExists" 1023 "Faulty" ;
VAL_ 980 BattChrgMde_D_Actl 0 "NotCharging" 1 "ConstantVoltage" 2 "ConstantCurrent" 3 "NotUsed" ;
VAL_ 980 BattAuxCnnct_B_Cmd 0 "Open" 1 "Close" ;
VAL_ 980 BattChrgCnnct_B_Cmd 0 "Open" 1 "Close" ;
VAL_ 980 PtWakeupActv2_B_Rq 0 "Off" 1 "On" ;
VAL_ 984 LaDenyStats_B_Dsply 0 "Available" 1 "Unavailable" ;
VAL_ 984 HzrdWarnLamp_B_Rq 0 "Inactive" 1 "Active" ;
VAL_ 984 CamraStats_D_Dsply 0 "Front_Camera_OK" 1 "Front_Camera_Service_Reqd" 2 "FrtCam_TempUnavailVisibile" 3 "FrtCam_TempUnavailOther" ;
VAL_ 984 CamraDefog_B_Req 0 "Off" 1 "On" ;
VAL_ 984 PersIndexIpma_D_Actl 0 "PERS_1" 1 "PERS_2" 2 "PERS_3" 3 "PERS_4" 4 "Vehicle" 5 "Unused_1" 6 "Unused_2" 7 "Unused_3" ;
VAL_ 984 DasAlrtLvl_D_Dsply 0 "Undefined" 1 "Alertness_Level_1" 2 "Alertness_Level_2" 3 "Alertness_Level_3" 4 "Alertness_Level_4" 5 "Alertness_Level_5" ;
VAL_ 984 DasWarn_D_Dsply 0 "No_Warning" 1 "Warning_Level_1" 2 "Warning_Level_2" 3 "Warning_Level_3" ;
VAL_ 984 DasFalt_B_Dsply 0 "Off" 1 "On" ;
VAL_ 984 DasStats_D_Dsply 0 "Off" 1 "Feedback_due_to_Speed" 2 "Unavailable_Other" 3 "Available" ;
VAL_ 984 LaHandsOff_D_Dsply 0 "HandsOn" 1 "Level1" 2 "Level2" 3 "Suppressed" ;
VAL_ 984 LaActvStats_D2_Dsply 0 "NoLeft_NoRight" 1 "AvailableLeft_NoRight" 2 "SuppressLeft_NoRight" 3 "WarnLeft_NoRight" 4 "InterveneLeft_NoRight" 5 "NoLeft_AvailableRight" 6 "AvailableLeft_AvailRight" 7 "SuppressLeft_AvailRight" 8 "WarnLeft_AvailRight" 9 "InterveneLeft_AvailRight" 10 "NoLeft_SuppressRight" 11 "AvailLeft_SuppressRight" 12 "SuppressLeft_SuppressRight" 13 "WarnLeft_SuppressRight" 14 "InterveneLeft_SuppressRght" 15 "NoLeft_WarnRight" 16 "AvailableLeft_WarnRight" 17 "SuppressLeft_WarnRight" 18 "WarnLeft_WarnRight" 19 "InterveneLeft_WarnRight" 20 "NoLeft_InterveneRight" 21 "AvailLeft_InterveneRhtt" 22 "SuppressLeft_InterveneRght" 23 "WarnLeft_InterveneRight" 24 "InerveneLeft_InterveneRght" 25 "Unused1" 26 "Unused2" 27 "Unused3" 28 "Unused4" 29 "ECE_OFF_RTT" 30 "LA_Off" 31 "Unused7" ;
VAL_ 984 AhbcRampingV_D_Rq 0 "Immediately" 1 "Fast" 2 "Medium" 3 "Slow" ;
VAL_ 984 AhbHiBeam_D_Rq 0 "DeactivatedUnavailable" 1 "LowBeamRecommended" 2 "HighBeamRecommended" 3 "NotUsed" ;
VAL_ 984 DsmcMsgTxt_D_Dsply 0 "NoMessage" 1 "Fault" 2 "DriverNotSeen" 3 "Blockage" ;
VAL_ 984 AhbFeat_D_Stat 0 "None" 1 "AHBC" 2 "GFHB" 3 "ADB" ;
VAL_ 985 IsaVLim_D_Rq 0 "LimitSpeed_0" 1 "LimitSpeed_1" 2 "LimitSpeed_2" 3 "LimitSpeed_3" 4 "LimitSpeed_4" 5 "LimitSpeed_5" 6 "LimitSpeed_6" 7 "LimitSpeed_7" 8 "LimitSpeed_8" 9 "LimitSpeed_9" 10 "LimitSpeed_10" 11 "LimitSpeed_11" 12 "LimitSpeed_12" 13 "LimitSpeed_13" 14 "LimitSpeed_14" 15 "LimitSpeed_15" 20 "LimtSpeed_20" 30 "LimitSpeed_30" 40 "LimitSpeed_40" 50 "LimitSpeed_50" 60 "LimitSpeed_60" 70 "LimitSpeed_70" 80 "LimitSpeed_80" 90 "LimitSpeed_90" 100 "LimitSpeed_100" 110 "LimitSpeed_110" 120 "LimitSpeed_120" 130 "LimitSpeed_130" 140 "LimitSpeed_140" 150 "LimitSpeed_150" 160 "LimitSpeed_160" 161 "LimitSpeed_161" 162 "LimitSpeed_162" 163 "LimitSpeed_163" 164 "LimitSpeed_164" 165 "LimitSpeed_165" 166 "LimitSpeed_166" 167 "LimitSpeed_167" 168 "LimitSpeed_168" 169 "LimitSpeed_169" 170 "LimitSpeed_170" 171 "LimitSpeed_171" 172 "LimitSpeed_172" 173 "LimitSpeed_173" 174 "LimitSpeed_174" 175 "LimitSpeed_175" 176 "LimitSpeed_176" 177 "LimitSpeed_177" 178 "LimitSpeed_178" 179 "LimitSpeed_179" 180 "LimitSpeed_180" 190 "LimitSpeed_190" 200 "LimitSpeed_200" 210 "LimitSpeed_210" 220 "LimitSpeed_220" 230 "LimitSpeed_230" 240 "LimitSpeed_240" 250 "LimitSpeed_250" 251 "NotUsed_1" 252 "NotUsed_2" 253 "NotUsed_3" 254 "NoDataExists" 255 "Faulty" ;
VAL_ 985 SblmStopScnr_B_Stat 0 "No" 1 "Yes" ;
VAL_ 985 SblmRndAbtScnr_B_Stat 0 "No" 1 "Yes" ;
VAL_ 985 IaccVLimUnit_D_Rq 0 "Null" 1 "Kph" 2 "Mph" 3 "NoDataExists" ;
VAL_ 985 DasAlrtInfo_D_Dsply 0 "Null" 1 "Off" 2 "On" 3 "NotUsed" ;
VAL_ 985 IsaVLimUnit_D_Rq 0 "Null" 1 "Kph" 2 "Mph" 3 "NoDataExists" ;
VAL_ 985 IaccVLim_D_Rq 0 "LimitSpeed_0" 1 "LimitSpeed_1" 2 "LimitSpeed_2" 3 "LimitSpeed_3" 4 "LimitSpeed_4" 5 "LimitSpeed_5" 6 "LimitSpeed_6" 7 "LimitSpeed_7" 8 "LimitSpeed_8" 9 "LimitSpeed_9" 10 "LimitSpeed_10" 11 "LimitSpeed_11" 12 "LimitSpeed_12" 13 "LimitSpeed_13" 14 "LimitSpeed_14" 15 "LimitSpeed_15" 20 "LimtSpeed_20" 30 "LimitSpeed_30" 40 "LimitSpeed_40" 50 "LimitSpeed_50" 60 "LimitSpeed_60" 70 "LimitSpeed_70" 80 "LimitSpeed_80" 90 "LimitSpeed_90" 100 "LimitSpeed_100" 110 "LimitSpeed_110" 120 "LimitSpeed_120" 130 "LimitSpeed_130" 140 "LimitSpeed_140" 150 "LimitSpeed_150" 160 "LimitSpeed_160" 161 "LimitSpeed_161" 162 "LimitSpeed_162" 163 "LimitSpeed_163" 164 "LimitSpeed_164" 165 "LimitSpeed_165" 166 "LimitSpeed_166" 167 "LimitSpeed_167" 168 "LimitSpeed_168" 169 "LimitSpeed_169" 170 "LimitSpeed_170" 171 "LimitSpeed_171" 172 "LimitSpeed_172" 173 "LimitSpeed_173" 174 "LimitSpeed_174" 175 "LimitSpeed_175" 176 "LimitSpeed_176" 177 "LimitSpeed_177" 178 "LimitSpeed_178" 179 "LimitSpeed_179" 180 "LimitSpeed_180" 190 "LimitSpeed_190" 200 "LimitSpeed_200" 210 "LimitSpeed_210" 220 "LimitSpeed_220" 230 "LimitSpeed_230" 240 "LimitSpeed_240" 250 "LimitSpeed_250" 251 "NotUsed_1" 252 "NotUsed_2" 253 "NotUsed_3" 254 "NoDataExists" 255 "Faulty" ;
VAL_ 985 LongCtrlBrk_D_Rq 0 "NoRequest" 1 "HighDecel" 2 "LowDecel" 3 "NotUsed" ;
VAL_ 985 AdbDividedRoad_B_Stat 0 "No" 1 "Yes" ;
VAL_ 985 SblmYieldScnr_B_Stat 0 "No" 1 "Yes" ;
VAL_ 985 SblmPedCrossScnr_B_Stat 0 "No" 1 "Yes" ;
VAL_ 985 LdwChime_B_Rq 0 "Off" 1 "On" ;
VAL_ 985 AdbDrvSide_B_Stat 0 "Right_Hand_Traffic" 1 "Left_Hand_Traffic" ;
VAL_ 985 LcwaMsgTxt_D_Stat 0 "NoMessage" 1 "TrailerConnected" 2 "SodXBlocked" 3 "SodXFaulty" ;
VAL_ 985 ClrExitAsst_D_Stat 0 "Null" 1 "Disabled" 2 "Enabled" 3 "NotUsed" ;
VAL_ 985 LongCtrlEnbl_D_Rq 0 "None" 1 "AutomaticParking" 2 "Autohitch" 3 "RemoteParking" 4 "NotUsed_1" 5 "NotUsed_2" 6 "NotUsed_3" 7 "Faulty" ;
VAL_ 985 TsrRegionTxt_D_Stat 0 "NotDetermined" 1 "Region_01" 2 "Region_02" 3 "Region_03" 4 "Region_04" 5 "Region_05" 6 "Region_06" 7 "Region_07" 8 "Region_08" 9 "Region_09" 10 "Region_10" 11 "Region_11" 12 "Region_12" 13 "Region_13" 14 "Region_14" 15 "Region_15" 16 "Region_16" 17 "Region_17" 18 "Region_18" 19 "Region_19" 20 "Region_20" 21 "Region_21" 22 "Region_22" 23 "NotUsed_1" 24 "NotUsed_2" 25 "NotUsed_3" 26 "NotUsed_4" 27 "NotUsed_5" 28 "NotUsed_6" 29 "NotUsed_7" 30 "NotUsed_8" 31 "Faulty" ;
VAL_ 985 PwSustnAdas_B_Rq 0 "Inactive" 1 "Active" ;
VAL_ 985 ClrExitAsstMsgTxt_D_Rq 0 "NoMessage" 1 "Shutdown" 2 "InformationLeft" 3 "InformationRight" 4 "WarningLeft" 5 "WarningRight" 6 "ChildLockMaintained" 7 "SystemFault" 8 "NotUsed_1" 9 "NotUsed_2" 10 "NotUsed_3" 11 "NotUsed_4" 12 "NotUsed_5" 13 "NotUsed_6" 14 "NotUsed_7" 15 "NotUsed_8" ;
VAL_ 985 ClrExitAsstChime_D_Rq 0 "Off" 1 "InformationChime" 2 "WarningChimeRear" 3 "WarningChimeFront" 4 "NotUsed_1" 5 "NotUsed_2" 6 "NotUsed_3" 7 "NotUsed_4" ;
VAL_ 986 LightAmbIntsty_No_Rq 0 "Off" ;
VAL_ 986 LghtAmbRqSrc_B_Stat 0 "Manual" 1 "Automatic" ;
VAL_ 986 VehPayloadTare_D_Rq 0 "NoRequest" 1 "Request" ;
VAL_ 986 VehFalr_D_Rq 0 "NoRequest" 1 "RequestFirstMeasurement" 2 "RequestSecondMeasurement" 3 "Complete" 4 "NotComplete" 5 "NotUsed_1" 6 "NotUsed_2" 7 "NotUsed_3" ;
VAL_ 986 TailLghtLoadMde_D_Rq 0 "NoCommand" 1 "ActivatePayloadMode" 2 "ActivateHitchLoadMode" 3 "ActivateFalrMode" 4 "DeactivateAll" 5 "NotUsed_1" 6 "NotUsed_2" 7 "NotUsed_3" ;
VAL_ 986 Trlr_M_Rq 2046 "NoDataExists" 2047 "Faulty" ;
VAL_ 986 PsngrLoad_M_Rq 1022 "NoDataExists" 1023 "Faulty" ;
VAL_ 986 VehPayloadScrn_D_Rq 0 "ScaleScreenNotActive" 1 "PayloadEstScreenActive" 2 "AddMassEstScreenActive" 3 "WeightDistScreenActive" 4 "FifthWheelScreenActive" 5 "GooseneckScreenActive" 6 "WeightCarryScreenActive" 7 "CheckLoadScreenActive" ;
VAL_ 986 DcacPwRsrvSet_D_Stat 0 "Null" 1 "Default" 2 "Manual" 3 "NearestChargeStation" ;
VAL_ 986 OnbSndActv_D_Rq 0 "Null" 1 "Deactivate" 2 "Activate" 3 "NotUsed_1" ;
VAL_ 989 AwlLamp_B_Rq 0 "Off" 1 "On" ;
VAL_ 989 AwlEnbl_B_Stat 0 "Disabled" 1 "Enabled" ;
VAL_ 990 PersIndexDdm_D_Actl 0 "PERS_1" 1 "PERS_2" 2 "PERS_3" 3 "PERS_4" 4 "Vehicle" 5 "Unused_1" 6 "Unused_2" 7 "Unused_3" ;
VAL_ 991 Trlr_M_Actl 2046 "NoDataExists" 2047 "Faulty" ;
VAL_ 991 VehPayloadGear_B_Stat 0 "No" 1 "Yes" ;
VAL_ 991 VehPayloadFlat_B_Stat 0 "No" 1 "Yes" ;
VAL_ 991 PersIndexVdm_D_Actl 0 "PERS_1" 1 "PERS_2" 2 "PERS_3" 3 "PERS_4" 4 "Vehicle" 5 "Unused_1" 6 "Unused_2" 7 "Unused_3" ;
VAL_ 991 VehPayloadTare_D_Stat 0 "NoRequest" 1 "Request" 2 "NotUsed" 3 "Faulty" ;
VAL_ 991 VehFalr_D_Stat 0 "NotActive" 1 "FirstMeasurementCollected" 2 "SecondMeasurementCollected" 3 "HeightCorrectionCompleted" 4 "NotUsed_1" 5 "NotUsed_2" 6 "NotUsed_3" 7 "Faulty" ;
VAL_ 991 TrlrTngLoad_D_Stat 0 "BelowRange" 1 "InRange" 2 "AboveRange" 3 "NotUsed_1" 4 "NotUsed_2" 5 "NotUsed_3" 6 "NoDataExists" 7 "Faulty" ;
VAL_ 991 PsngrLoad_D_Stat 0 "Inactive" 1 "NotAccepted" 2 "Accepted" 3 "NotUsed_1" ;
VAL_ 991 VehPayloadTireP_B_Stat 0 "No" 1 "Yes" ;
VAL_ 991 VehPayloadStew_B_Stat 0 "No" 1 "Yes" ;
VAL_ 991 VehPayloadScrn_D_Stat 0 "ScaleScreenNotActive" 1 "PayloadEstScreenActive" 2 "AddMassEstScreenActive" 3 "WeightDistScreenActive" 4 "FifthWheelScreenActive" 5 "GooseneckScreenActive" 6 "WeightCarryScreenActive" 7 "CheckLoadScreenActive" ;
VAL_ 992 MsgCntrDsplyOp_D_Rq 0 "Null" 1 "Query" 2 "Set" 3 "Upload" 4 "Restore" 5 "Copy" 6 "Unused_1" 7 "Unused_2" ;
VAL_ 992 MsgCntrPersIndex_D_Rq 0 "PERS_1" 1 "PERS_2" 2 "PERS_3" 3 "PERS_4" 4 "Vehicle" 5 "Unused_1" 6 "Unused_2" 7 "Unused_3" ;
VAL_ 993 MemSwtch_D_RqAssoc 0 "Null" 1 "PERS_1" 2 "PERS_2" 3 "PERS_3" 4 "PERS_4" 5 "Unused_1" 6 "Unused_2" 7 "Unused_3" ;
VAL_ 993 MemSwtch_D_RqRecall 0 "Null" 1 "PERS_1" 2 "PERS_2" 3 "PERS_3" 4 "PERS_4" 5 "Unused_1" 6 "Unused_2" 7 "Unused_3" ;
VAL_ 993 PersStore_D_Actl 0 "Complete" 1 "InProgress" 2 "Null" 3 "Unused" ;
VAL_ 993 MemSetButtnMsgTxt_D_Rq 0 "Null" 1 "Press1or2" 2 "Press1or2or3" 3 "NotUsed" ;
VAL_ 993 EmButtn_D_Stat 0 "Null" 1 "Button1Pressed" 2 "Button2Pressed" 3 "Button3Pressed" 4 "Button4Pressed" 5 "ButtonAssociationEntered" 6 "ButtonAssociationExited" 7 "ButtonAssociationFailed" ;
VAL_ 993 PersIndexDsm_D_Actl 0 "PERS_1" 1 "PERS_2" 2 "PERS_3" 3 "PERS_4" 4 "Vehicle" 5 "Unused_1" 6 "Unused_2" 7 "Unused_3" ;
VAL_ 993 StmsScrnDrvOn_B_Rq 0 "Off" 1 "On" ;
VAL_ 993 MemStoreMsgTxt_D_Rq 0 "Null" 1 "Mem1Saved_DoNotShowLinkMsg" 2 "Mem2Saved_DoNotShowLinkMsg" 3 "Mem3Saved_DoNotShowLinkMsg" 4 "Mem4Saved_DoNotShowLinkMsg" 5 "Mem1Saved_ShowLinkMsg" 6 "Mem2Saved_ShowLinkMsg" 7 "Mem3Saved_ShowLinkMsg" 8 "Mem4Saved_ShowLinkMsg" 9 "NotUsed_1" 10 "NotUsed_2" ;
VAL_ 994 Pers2OptIn_B_Stats 0 "NOT_OPTED_IN" 1 "OPTED_IN" ;
VAL_ 994 Pers3OptIn_B_Stats 0 "NOT_OPTED_IN" 1 "OPTED_IN" ;
VAL_ 994 PersStore_D_Rq 0 "Null" 1 "PERS_1" 2 "PERS_2" 3 "PERS_3" 4 "PERS_4" 5 "Vehicle" 6 "Unused_1" 7 "Unused_2" ;
VAL_ 994 CtrStkPersIndex_D_Actl 0 "PERS_1" 1 "PERS_2" 2 "PERS_3" 3 "PERS_4" 4 "Vehicle" 5 "Unused_1" 6 "Unused_2" 7 "Unused_3" ;
VAL_ 994 PersCtaSplitView_D_Rq 0 "Null" 1 "Disabled" 2 "Enabled_180SwitchOnly" 3 "EnabledFull" ;
VAL_ 994 Pers4OptIn_B_Stats 0 "NOT_OPTED_IN" 1 "OPTED_IN" ;
VAL_ 994 Pers1OptIn_B_Stats 0 "NOT_OPTED_IN" 1 "OPTED_IN" ;
VAL_ 994 CtrStkDsplyOp_D_Rq 0 "Null" 1 "Query" 2 "Set" 3 "Upload" 4 "Restore" 5 "Copy" 6 "Unused_1" 7 "Unused_2" ;
SIG_GROUP_ 885 SG_Profile1A_SigGroup_375 1 : BattULoChrg_D_RqOta CanMsg375_No_Cnt CanMsg375_No_Crc CanMsg375_UNUSED_4bit_1 CanMsg375_UNUSED_7bit_1 CanMsg375_UNUSED_8bit_1 OtaActv_D_Stat VehOnRqstr_D_Stat VehOn_D_RqCld VehStrtInhbt_D_Dsply VehStrtInhbt_D_RqCld VehStrtInhbt_T_Dsply;
SIG_GROUP_ 932 SG_Profile1A_SigGroup_3A4 1 : CanMsg3A4_No_Cnt CanMsg3A4_No_Crc CanMsg3A4_UNUSED_7bit_1 CanMsg3A4_UNUSED_8bit_1 CanMsg3A4_UNUSED_8bit_2 CanMsg3A4_UNUSED_8bit_3 CanMsg3A4_UNUSED_8bit_4 ChildLck_D_Dsply RmtCtlBattMntr_B_Falt VehInhbtMde_D_Stat VehOnCtl_D_Stat VehOnSrc2_D_Stat VehStrtInhbt_D_Stat;
